VERSION ""

NS_ :

BS_:

BU_: TCM iBooster HCU CIM SCM Right_Hand_Control Left_Hand_Control GPS VCM IC_2 XM GMRS Radio_CANtool Diagnostic_Tool_Digital_Wrench Information_System_Controller_1 STEERING_CONTROLLER VEHICLE_SECURITY RADIO_Hub ABS Battery_Management_Cntrl_2 Battery_Management_Cntrl_1 Auxiliary_Power_Unit_2 Auxiliary_Power_Unit_1 Electric_Propulsion_Cntrl_Unit_4 Electric_Propulsion_Cntrl_Unit_3 Electric_Propulsion_Cntrl_Unit_2 Electric_Propulsion_Cntrl_Unit_1 ECM IC

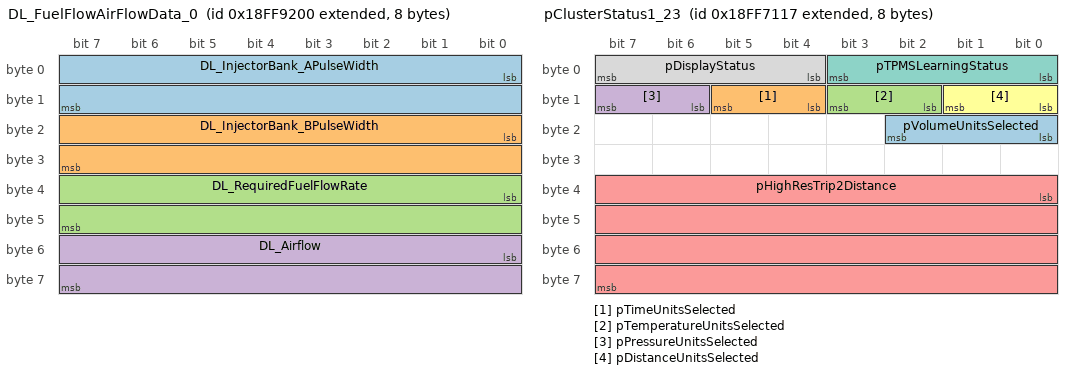
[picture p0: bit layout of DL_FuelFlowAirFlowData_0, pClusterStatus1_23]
BO_ 2566885888 DL_FuelFlowAirFlowData_0: 8 ECM
 SG_ DL_InjectorBank_APulseWidth : 0|16@1+ (0.01,0) [0|655.3] "ms" Vector__XXX
 SG_ DL_InjectorBank_BPulseWidth : 16|16@1+ (0.01,0) [0|655.3] "ms" Vector__XXX
 SG_ DL_RequiredFuelFlowRate : 32|16@1+ (0.003433,0) [0|224.96] "Kg/hr" Vector__XXX
 SG_ DL_Airflow : 48|16@1+ (0.05493,0) [0|3599.56] "Kg/hr" Vector__XXX

BO_ 2566877696 pVT1_0: 8 ECM
 SG_ pLeftHandGripTemp : 0|8@1+ (1,-40) [-40|210] "deg C" Vector__XXX
 SG_ pRightHandGripTemp : 8|8@1+ (1,-40) [-40|210] "deg C" Vector__XXX

BO_ 2566877463 pClusterStatus1_23: 8 IC
 SG_ pVolumeUnitsSelected : 16|3@1+ (1,0) [0|7] "" Vector__XXX
 SG_ pTimeUnitsSelected : 12|2@1+ (1,0) [0|3] "" Vector__XXX
 SG_ pTemperatureUnitsSelected : 10|2@1+ (1,0) [0|3] "" Vector__XXX
 SG_ pPressureUnitsSelected : 14|2@1+ (1,0) [0|3] "" Vector__XXX
 SG_ pHighResTrip2Distance : 32|32@1+ (0.005,0) [0|21055406] "km" Vector__XXX
 SG_ pDistanceUnitsSelected : 8|2@1+ (1,0) [0|3] "" Vector__XXX
 SG_ pTPMSLearningStatus : 0|4@1+ (1,0) [0|15] "" Vector__XXX
 SG_ pDisplayStatus : 4|4@1+ (1,0) [0|15] "" Vector__XXX

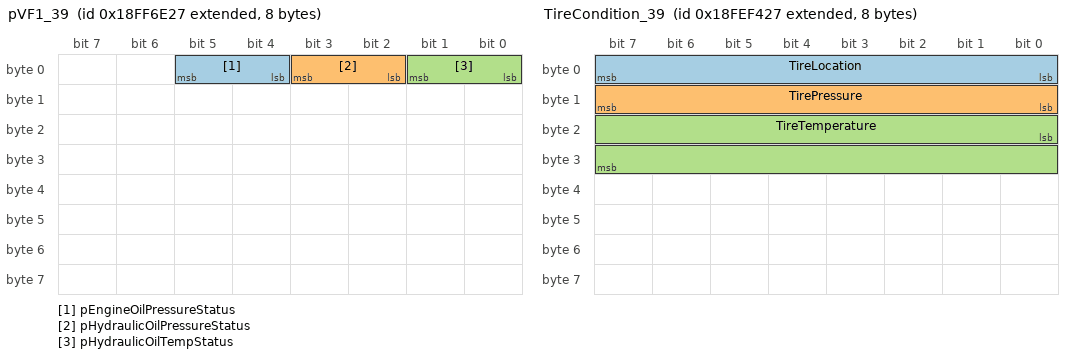
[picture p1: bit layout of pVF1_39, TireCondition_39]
BO_ 2566876711 pVF1_39: 8 VCM
 SG_ pEngineOilPressureStatus : 4|2@1+ (1,0) [0|3] "" Vector__XXX
 SG_ pHydraulicOilPressureStatus : 2|2@1+ (1,0) [0|3] "" Vector__XXX
 SG_ pHydraulicOilTempStatus : 0|2@1+ (1,0) [0|3] "" Vector__XXX

BO_ 2633984551 pDriveSystemStatus_39: 8 VCM
 SG_ pHeatedGripEnable : 48|2@1+ (1,0) [0|3] "" Vector__XXX
 SG_ pSideStandStatus : 36|2@1+ (1,0) [0|3] "" Vector__XXX
 SG_ pTetherSwitchStatus : 46|2@1+ (1,0) [0|3] "" Vector__XXX
 SG_ pLowFuelIndicatorStatus : 10|2@1+ (1,0) [0|3] "" Vector__XXX
 SG_ pOperatorNotInOperatingStation : 38|2@1+ (1,0) [0|3] "" Vector__XXX
 SG_ pParkBrakeIndicatorStatus : 40|3@1+ (1,0) [0|7] "" Vector__XXX
 SG_ pADCRequested : 34|2@1+ (1,0) [0|3] "" Vector__XXX
 SG_ pAWDModeRequested : 32|2@1+ (1,0) [0|3] "" Vector__XXX
 SG_ pRWDModeRequested : 30|2@1+ (1,0) [0|3] "" Vector__XXX
 SG_ pTurfModeRequested : 28|2@1+ (1,0) [0|3] "" Vector__XXX
 SG_ pADCStatus : 0|2@1+ (1,0) [0|3] "" Vector__XXX
 SG_ pTreadleNeutralStatus : 2|2@1+ (1,0) [0|3] "" Vector__XXX
 SG_ pTreadleReverseStatus : 4|2@1+ (1,0) [0|3] "" Vector__XXX
 SG_ pSecurityLightStatus : 6|2@1+ (1,0) [0|3] "" Vector__XXX
 SG_ pHighBeamIndicatorStatus : 8|2@1+ (1,0) [0|3] "" Vector__XXX
 SG_ pHeatedGripsPercentage : 16|8@1+ (0.4,0) [0|100] "%" Vector__XXX
 SG_ pCruiseControlSetStatus : 24|2@1+ (1,0) [0|3] "" Vector__XXX
 SG_ pSeatBeltIndicatorStatus : 12|3@1+ (1,0) [0|7] "" Vector__XXX

BO_ 2432656679 pOperatorSwitchStatus_39: 8 VCM
 SG_ pOperatorButton29 : 58|2@1+ (1,0) [0|3] "" Vector__XXX
 SG_ pOperatorButton1 : 0|2@1+ (1,0) [0|3] "" Vector__XXX
 SG_ pOperatorButton2 : 2|2@1+ (1,0) [0|3] "" Vector__XXX
 SG_ pOperatorButton3 : 4|2@1+ (1,0) [0|3] "" Vector__XXX
 SG_ pOperatorButton4 : 6|2@1+ (1,0) [0|3] "" Vector__XXX
 SG_ pOperatorButton5 : 8|2@1+ (1,0) [0|3] "" Vector__XXX
 SG_ pOperatorButton6 : 10|2@1+ (1,0) [0|3] "" Vector__XXX
 SG_ pOperatorButton7 : 12|2@1+ (1,0) [0|3] "" Vector__XXX
 SG_ pOperatorButton8 : 14|2@1+ (1,0) [0|3] "" Vector__XXX
 SG_ pOperatorButton9 : 16|2@1+ (1,0) [0|3] "" Vector__XXX
 SG_ pOperatorButton10 : 18|2@1+ (1,0) [0|3] "" Vector__XXX
 SG_ pOperatorButton11 : 20|2@1+ (1,0) [0|3] "" Vector__XXX
 SG_ pOperatorButton12 : 22|2@1+ (1,0) [0|3] "" Vector__XXX
 SG_ pOperatorButton13 : 24|2@1+ (1,0) [0|3] "" Vector__XXX
 SG_ pOperatorButton14 : 26|2@1+ (1,0) [0|3] "" Vector__XXX
 SG_ pOperatorButton15 : 28|2@1+ (1,0) [0|3] "" Vector__XXX
 SG_ pOperatorButton16 : 30|2@1+ (1,0) [0|3] "" Vector__XXX
 SG_ pOperatorButton17 : 32|2@1+ (1,0) [0|3] "" Vector__XXX
 SG_ pOperatorButton18 : 34|2@1+ (1,0) [0|3] "" Vector__XXX
 SG_ pOperatorButton19 : 36|2@1+ (1,0) [0|3] "" Vector__XXX
 SG_ pOperatorButton20 : 38|2@1+ (1,0) [0|3] "" Vector__XXX
 SG_ pOperatorButton21 : 40|2@1+ (1,0) [0|3] "" Vector__XXX
 SG_ pOperatorButton22 : 42|2@1+ (1,0) [0|3] "" Vector__XXX
 SG_ pOperatorButton23 : 44|2@1+ (1,0) [0|3] "" Vector__XXX
 SG_ pOperatorButton24 : 46|2@1+ (1,0) [0|3] "" Vector__XXX
 SG_ pOperatorButton25 : 48|2@1+ (1,0) [0|3] "" Vector__XXX
 SG_ pOperatorButton26 : 50|2@1+ (1,0) [0|3] "" Vector__XXX
 SG_ pOperatorButton27 : 52|2@1+ (1,0) [0|3] "" Vector__XXX
 SG_ pOperatorButton28 : 54|2@1+ (1,0) [0|3] "" Vector__XXX
 SG_ pSideStandStatus : 56|2@1+ (1,0) [0|3] "" Vector__XXX

BO_ 2566845479 TireCondition_39: 8 VCM
 SG_ TireLocation : 0|8@1+ (1,0) [0|255] "Bit" Vector__XXX
 SG_ TirePressure : 8|8@1+ (4,0) [0|1000] "kPa" Vector__XXX
 SG_ TireTemperature : 16|16@1+ (0.03125,-273) [-273|1734.96875] "DegC" Vector__XXX

BO_ 2566844711 CruiseControlVehSpeed_39: 8 VCM
 SG_ pCruiseCntrlCounter : 50|4@1+ (1,0) [0|15] "" Vector__XXX
 SG_ TwoSpeedAxleSwitch : 0|2@1+ (1,0) [0|3] "" Vector__XXX
 SG_ ParkingBrakeSwitch : 2|2@1+ (1,0) [0|3] "" Vector__XXX
 SG_ Wheel_BasedVehicleSpeed : 8|16@1+ (0.00390625,0) [0|251] "km/h" Vector__XXX
 SG_ CruiseCtrlActive : 24|2@1+ (1,0) [0|3] "" Vector__XXX
 SG_ CruiseCtrlEnableSwitch : 26|2@1+ (1,0) [0|3] "" Vector__XXX
 SG_ BrakeSwitch : 28|2@1+ (1,0) [0|3] "" Vector__XXX
 SG_ ClutchSwitch : 30|2@1+ (1,0) [0|3] "" Vector__XXX
 SG_ CruiseCtrlSetSwitch : 32|2@1+ (1,0) [0|3] "" Vector__XXX
 SG_ CruiseCtrlCoastSwitch : 34|2@1+ (1,0) [0|3] "" Vector__XXX
 SG_ CruiseCtrlResumeSwitch : 36|2@1+ (1,0) [0|3] "" Vector__XXX
 SG_ CruiseCtrlAccelerateSwitch : 38|2@1+ (1,0) [0|3] "" Vector__XXX
 SG_ CruiseCtrlSetSpeed : 40|8@1+ (1,0) [0|250] "km/h" Vector__XXX
 SG_ pOdometerDriveBit : 6|2@1+ (1,0) [0|3] "" Vector__XXX
 SG_ CruiseCtrlPauseSw : 4|2@1+ (1,0) [0|3] "" Vector__XXX
 SG_ pCCChecksum : 56|8@1+ (1,0) [0|255] "" Vector__XXX
 SG_ pCruiseEnableStatus : 48|4@1+ (1,0) [0|15] "" Vector__XXX

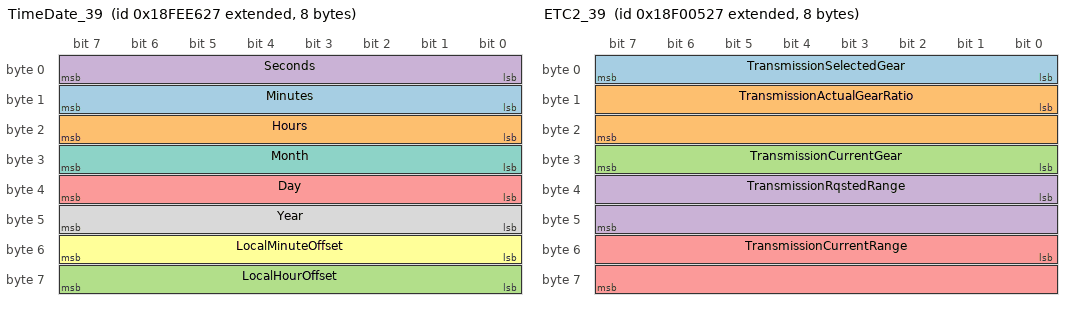
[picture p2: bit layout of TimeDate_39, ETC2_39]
BO_ 2566841895 TimeDate_39: 8 VCM
 SG_ Minutes : 8|8@1+ (1,0) [0|250] "Minutes" Vector__XXX
 SG_ Hours : 16|8@1+ (1,0) [0|250] "Hours" Vector__XXX
 SG_ LocalHourOffset : 56|8@1+ (1,-125) [-125|125] "Hours" Vector__XXX
 SG_ Seconds : 0|8@1+ (0.25,0) [0|62.5] "Seconds" Vector__XXX
 SG_ Day : 32|8@1+ (0.25,0) [0|62.5] "Days" Vector__XXX
 SG_ LocalMinuteOffset : 48|8@1+ (1,-125) [-125|125] "Mins" Vector__XXX
 SG_ Month : 24|8@1+ (1,0) [0|250] "Months" Vector__XXX
 SG_ Year : 40|8@1+ (1,1985) [0|2235] "Years" Vector__XXX

BO_ 2565866791 ETC2_39: 8 VCM
 SG_ TransmissionSelectedGear : 0|8@1+ (1,-125) [-125|125] "" Vector__XXX
 SG_ TransmissionActualGearRatio : 8|16@1+ (0.001,0) [0|64.255] "" Vector__XXX
 SG_ TransmissionCurrentGear : 24|8@1+ (1,-125) [-125|125] "" Vector__XXX
 SG_ TransmissionRqstedRange : 32|16@1+ (1,0) [0|65535] "" Vector__XXX
 SG_ TransmissionCurrentRange : 48|16@1+ (1,0) [0|65535] "" Vector__XXX

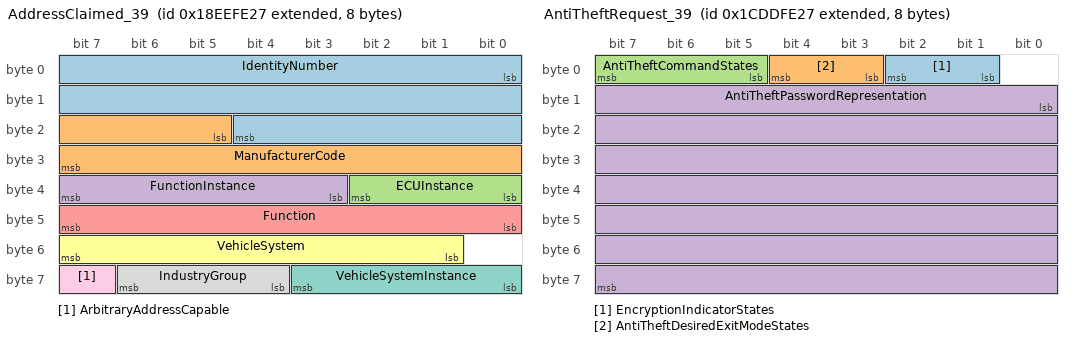
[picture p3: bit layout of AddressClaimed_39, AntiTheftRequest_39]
BO_ 2565799463 AddressClaimed_39: 8 VCM
 SG_ IdentityNumber : 0|21@1+ (1,0) [0|2097151] "" Vector__XXX
 SG_ ManufacturerCode : 21|11@1+ (1,0) [0|2047] "" Vector__XXX
 SG_ ECUInstance : 32|3@1+ (1,0) [0|7] "" Vector__XXX
 SG_ FunctionInstance : 35|5@1+ (1,0) [0|31] "" Vector__XXX
 SG_ Function : 40|8@1+ (1,0) [0|255] "" Vector__XXX
 SG_ VehicleSystem : 49|7@1+ (1,0) [0|127] "" Vector__XXX
 SG_ VehicleSystemInstance : 56|4@1+ (1,0) [0|15] "" Vector__XXX
 SG_ IndustryGroup : 60|3@1+ (1,0) [0|7] "" Vector__XXX
 SG_ ArbitraryAddressCapable : 63|1@1+ (1,0) [0|0] "" Vector__XXX

BO_ 2631794215 AntiTheftRequest_39: 8 VCM
 SG_ EncryptionIndicatorStates : 1|2@1+ (1,0) [0|3] "" Vector__XXX
 SG_ AntiTheftDesiredExitModeStates : 3|2@1+ (1,0) [0|3] "" Vector__XXX
 SG_ AntiTheftCommandStates : 5|3@1+ (1,0) [0|7] "" Vector__XXX
 SG_ AntiTheftPasswordRepresentation : 8|56@1+ (1,0) [0|0] "" Vector__XXX

BO_ 2550791719 SRASI_39: 8 VCM
 SG_ StaticRollAngle : 0|8@1+ (1,-125) [-125|130] "Degrees" Vector__XXX
 SG_ StaticRollAngleStatus : 8|3@1+ (1,0) [0|7] "" Vector__XXX

BO_ 2566842495 VehicleDirectionSpeed_127: 8 RADIO_Hub
 SG_ CompassBearing : 0|16@1+ (0.0078125,0) [0|501.99] "Degree" Vector__XXX

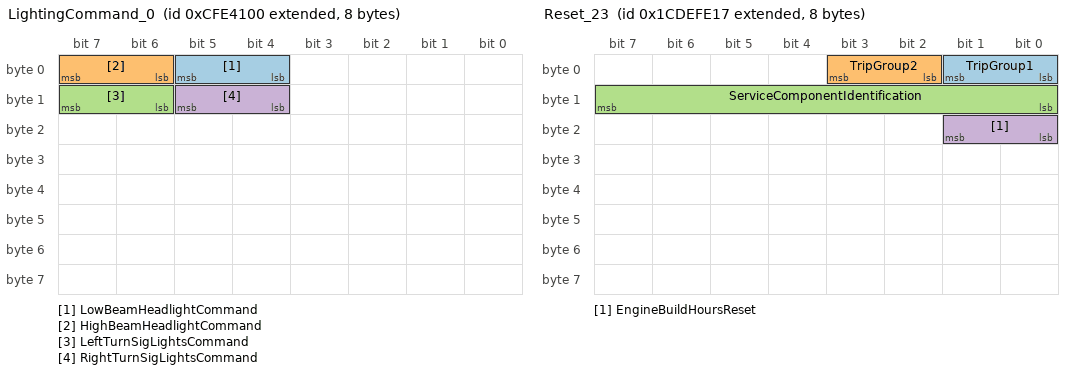
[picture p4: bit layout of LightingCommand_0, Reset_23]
BO_ 2365473024 LightingCommand_0: 8 ECM
 SG_ LowBeamHeadlightCommand : 4|2@1+ (1,0) [0|3] "" Vector__XXX
 SG_ HighBeamHeadlightCommand : 6|2@1+ (1,0) [0|3] "" Vector__XXX
 SG_ LeftTurnSigLightsCommand : 14|2@1+ (1,0) [0|3] "" Vector__XXX
 SG_ RightTurnSigLightsCommand : 12|2@1+ (1,0) [0|3] "" Vector__XXX

BO_ 2631859735 Reset_23: 8 IC
 SG_ TripGroup1 : 0|2@1+ (1,0) [0|3] "" Vector__XXX
 SG_ TripGroup2 : 2|2@1+ (1,0) [0|3] "" Vector__XXX
 SG_ ServiceComponentIdentification : 8|8@1+ (1,0) [0|250] "" Vector__XXX
 SG_ EngineBuildHoursReset : 16|2@1+ (1,0) [0|3] "" Vector__XXX

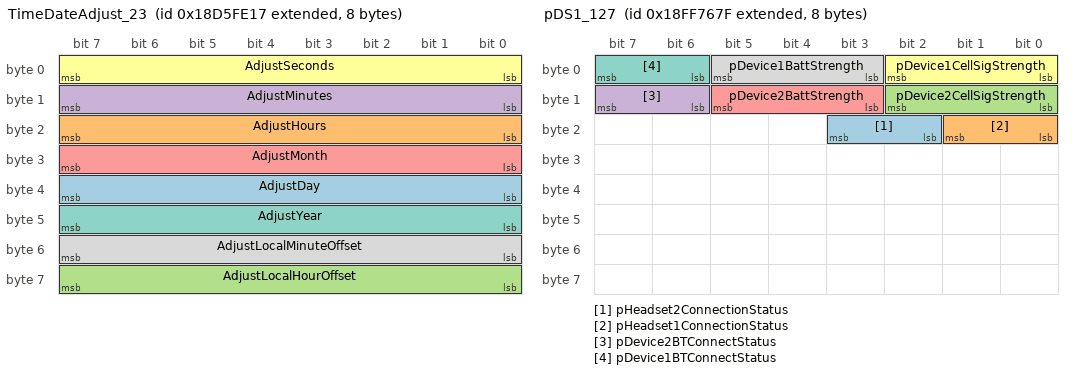
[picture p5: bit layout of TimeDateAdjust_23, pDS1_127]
BO_ 2564161047 TimeDateAdjust_23: 8 IC
 SG_ AdjustDay : 32|8@1+ (0.25,0) [0|62.5] "Days" Vector__XXX
 SG_ AdjustHours : 16|8@1+ (1,0) [0|250] "Hours" Vector__XXX
 SG_ AdjustLocalHourOffset : 56|8@1+ (1,-125) [-125|130] "Hours" Vector__XXX
 SG_ AdjustMinutes : 8|8@1+ (1,0) [0|250] "Minutes" Vector__XXX
 SG_ AdjustMonth : 24|8@1+ (1,0) [0|250] "Months" Vector__XXX
 SG_ AdjustSeconds : 0|8@1+ (0.25,0) [0|62.5] "Seconds" Vector__XXX
 SG_ AdjustYear : 40|8@1+ (1,1985) [1985|2235] "Years" Vector__XXX
 SG_ AdjustLocalMinuteOffset : 48|8@1+ (1,-125) [-125|130] "Minutes" Vector__XXX

BO_ 2550201867 TorqueSpeedControl1_11: 4 ABS
 SG_ EngOverrideCtlMode : 0|2@1+ (1,0) [0|3] "" Vector__XXX
 SG_ EngReqSpeedControlCond : 2|2@1+ (1,0) [0|3] "" Vector__XXX
 SG_ OverrideCtlModePriority : 4|2@1+ (1,0) [0|3] "" Vector__XXX
 SG_ EngReqSpeedLimit : 8|16@1+ (1,0) [0|65535] "" Vector__XXX
 SG_ EngReqTorqueLimit : 24|8@1+ (1,-125) [-125|130] "%" Vector__XXX
 SG_ TSC1_TransmissionRate : 32|3@1+ (1,0) [0|7] "" Vector__XXX
 SG_ EngineRequestedTorque_HiRes : 40|4@1+ (0.125,0) [0|0.875] "%" Vector__XXX
 SG_ MessageCounter : 56|4@1- (1,0) [-8|7] "Count" Vector__XXX
 SG_ MessageChecksum : 60|4@1+ (1,0) [0|15] "" Vector__XXX

BO_ 2566878847 pDS1_127: 8 RADIO_Hub
 SG_ pHeadset2ConnectionStatus : 18|2@1+ (1,0) [0|3] "" Vector__XXX
 SG_ pHeadset1ConnectionStatus : 16|2@1+ (1,0) [0|3] "" Vector__XXX
 SG_ pDevice2CellSigStrength : 8|3@1+ (1,0) [0|7] "" Vector__XXX
 SG_ pDevice2BTConnectStatus : 14|2@1+ (1,0) [0|3] "" Vector__XXX
 SG_ pDevice2BattStrength : 11|3@1+ (1,0) [0|7] "" Vector__XXX
 SG_ pDevice1CellSigStrength : 0|3@1+ (1,0) [0|7] "" Vector__XXX
 SG_ pDevice1BTConnectStatus : 6|2@1+ (1,0) [0|3] "" Vector__XXX
 SG_ pDevice1BattStrength : 3|3@1+ (1,0) [0|7] "" Vector__XXX

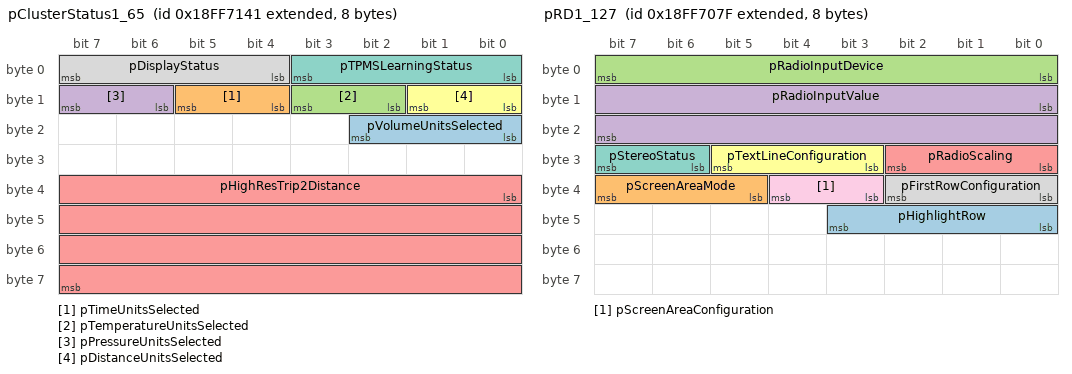
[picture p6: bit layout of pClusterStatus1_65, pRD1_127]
BO_ 2566877505 pClusterStatus1_65: 8 Information_System_Controller_1
 SG_ pVolumeUnitsSelected : 16|3@1+ (1,0) [0|7] "" Vector__XXX
 SG_ pTimeUnitsSelected : 12|2@1+ (1,0) [0|3] "" Vector__XXX
 SG_ pTemperatureUnitsSelected : 10|2@1+ (1,0) [0|3] "" Vector__XXX
 SG_ pPressureUnitsSelected : 14|2@1+ (1,0) [0|3] "" Vector__XXX
 SG_ pHighResTrip2Distance : 32|32@1+ (0.005,0) [0|21055406] "km" Vector__XXX
 SG_ pDistanceUnitsSelected : 8|2@1+ (1,0) [0|3] "" Vector__XXX
 SG_ pTPMSLearningStatus : 0|4@1+ (1,0) [0|15] "" Vector__XXX
 SG_ pDisplayStatus : 4|4@1+ (1,0) [0|15] "" Vector__XXX

BO_ 2566877311 pRD1_127: 8 RADIO_Hub
 SG_ pHighlightRow : 40|4@1+ (1,0) [0|15] "" Vector__XXX
 SG_ pScreenAreaMode : 37|3@1+ (1,0) [0|7] "" Vector__XXX
 SG_ pRadioInputDevice : 0|8@1+ (1,0) [0|65535] "" Vector__XXX
 SG_ pRadioInputValue : 8|16@1+ (1,0) [0|65535] "" Vector__XXX
 SG_ pRadioScaling : 24|3@1+ (1,0) [0|7] "" Vector__XXX
 SG_ pTextLineConfiguration : 27|3@1+ (1,0) [0|7] "" Vector__XXX
 SG_ pStereoStatus : 30|2@1+ (1,0) [0|3] "" Vector__XXX
 SG_ pFirstRowConfiguration : 32|3@1+ (1,0) [0|7] "" Vector__XXX
 SG_ pScreenAreaConfiguration : 35|2@1+ (1,0) [0|3] "" Vector__XXX

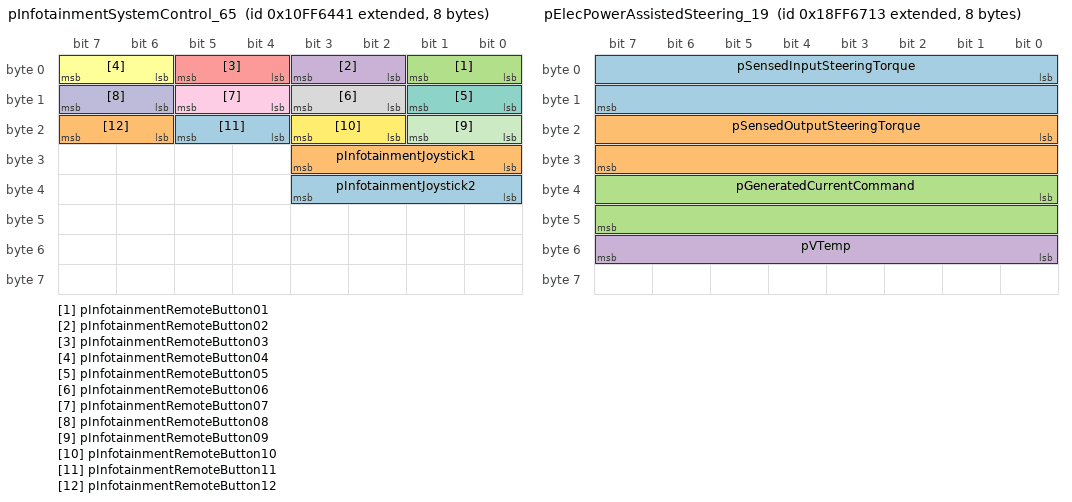
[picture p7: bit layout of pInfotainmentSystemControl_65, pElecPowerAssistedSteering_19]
BO_ 2432656449 pInfotainmentSystemControl_65: 8 Information_System_Controller_1
 SG_ pInfotainmentJoystick2 : 32|4@1+ (1,0) [0|15] "" Vector__XXX
 SG_ pInfotainmentJoystick1 : 24|4@1+ (1,0) [0|15] "" Vector__XXX
 SG_ pInfotainmentRemoteButton01 : 0|2@1+ (1,0) [0|3] "" Vector__XXX
 SG_ pInfotainmentRemoteButton02 : 2|2@1+ (1,0) [0|3] "" Vector__XXX
 SG_ pInfotainmentRemoteButton03 : 4|2@1+ (1,0) [0|3] "" Vector__XXX
 SG_ pInfotainmentRemoteButton04 : 6|2@1+ (1,0) [0|3] "" Vector__XXX
 SG_ pInfotainmentRemoteButton05 : 8|2@1+ (1,0) [0|3] "" Vector__XXX
 SG_ pInfotainmentRemoteButton06 : 10|2@1+ (1,0) [0|3] "" Vector__XXX
 SG_ pInfotainmentRemoteButton07 : 12|2@1+ (1,0) [0|3] "" Vector__XXX
 SG_ pInfotainmentRemoteButton08 : 14|2@1+ (1,0) [0|3] "" Vector__XXX
 SG_ pInfotainmentRemoteButton09 : 16|2@1+ (1,0) [0|3] "" Vector__XXX
 SG_ pInfotainmentRemoteButton10 : 18|2@1+ (1,0) [0|3] "" Vector__XXX
 SG_ pInfotainmentRemoteButton11 : 20|2@1+ (1,0) [0|3] "" Vector__XXX
 SG_ pInfotainmentRemoteButton12 : 22|2@1+ (1,0) [0|3] "" Vector__XXX

BO_ 2566874899 pElecPowerAssistedSteering_19: 8 STEERING_CONTROLLER
 SG_ pSensedInputSteeringTorque : 0|16@1- (0.1,-3200) [-3200|3353.5] "Nm" Vector__XXX
 SG_ pSensedOutputSteeringTorque : 16|16@1- (0.1,-3200) [-3200|3353.5] "Nm" Vector__XXX
 SG_ pGeneratedCurrentCommand : 32|16@1+ (0.00381467265625,-125) [-125|124.994572527344] "A" Vector__XXX
 SG_ pVTemp : 48|8@1- (1,-40) [-40|210] "C" Vector__XXX

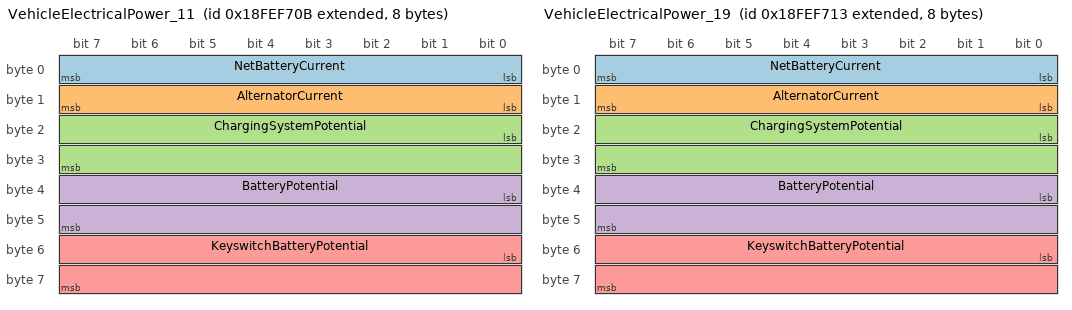
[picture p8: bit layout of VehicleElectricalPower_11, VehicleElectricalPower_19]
BO_ 2566846219 VehicleElectricalPower_11: 8 ABS
 SG_ NetBatteryCurrent : 0|8@1+ (1,-125) [-125|125] "A" Vector__XXX
 SG_ AlternatorCurrent : 8|8@1+ (1,0) [0|250] "A" Vector__XXX
 SG_ ChargingSystemPotential : 16|16@1+ (0.05,0) [0|3212.75] "V" Vector__XXX
 SG_ BatteryPotential : 32|16@1+ (0.05,0) [0|3212.75] "V" Vector__XXX
 SG_ KeyswitchBatteryPotential : 48|16@1+ (0.05,0) [0|3212.75] "V" Vector__XXX

BO_ 2566846227 VehicleElectricalPower_19: 8 STEERING_CONTROLLER
 SG_ NetBatteryCurrent : 0|8@1+ (1,-125) [-125|125] "A" Vector__XXX
 SG_ AlternatorCurrent : 8|8@1+ (1,0) [0|250] "A" Vector__XXX
 SG_ ChargingSystemPotential : 16|16@1+ (0.05,0) [0|3212.75] "V" Vector__XXX
 SG_ BatteryPotential : 32|16@1+ (0.05,0) [0|3212.75] "V" Vector__XXX
 SG_ KeyswitchBatteryPotential : 48|16@1+ (0.05,0) [0|3212.75] "V" Vector__XXX

BO_ 2566844683 CruiseControlVehSpeed_11: 8 ABS
 SG_ TwoSpeedAxleSwitch : 0|2@1+ (1,0) [0|3] "" Vector__XXX
 SG_ ParkingBrakeSwitch : 2|2@1+ (1,0) [0|3] "" Vector__XXX
 SG_ Wheel_BasedVehicleSpeed : 8|16@1+ (0.00390625,0) [0|251] "km/h" Vector__XXX
 SG_ CruiseCtrlActive : 24|2@1+ (1,0) [0|3] "" Vector__XXX
 SG_ CruiseCtrlEnableSwitch : 26|2@1+ (1,0) [0|3] "" Vector__XXX
 SG_ BrakeSwitch : 28|2@1+ (1,0) [0|3] "" Vector__XXX
 SG_ ClutchSwitch : 30|2@1+ (1,0) [0|3] "" Vector__XXX
 SG_ CruiseCtrlSetSwitch : 32|2@1+ (1,0) [0|3] "" Vector__XXX
 SG_ CruiseCtrlCoastSwitch : 34|2@1+ (1,0) [0|3] "" Vector__XXX
 SG_ CruiseCtrlResumeSwitch : 36|2@1+ (1,0) [0|3] "" Vector__XXX
 SG_ CruiseCtrlAccelerateSwitch : 38|2@1+ (1,0) [0|3] "" Vector__XXX
 SG_ CruiseCtrlSetSpeed : 40|8@1+ (1,0) [0|250] "km/h" Vector__XXX
 SG_ pOdometerDriveBit : 6|2@1+ (1,0) [0|3] "" Vector__XXX
 SG_ CruiseCtrlPauseSw : 4|2@1+ (1,0) [0|3] "" Vector__XXX
 SG_ pCCChecksum : 56|8@1+ (1,0) [0|255] "" Vector__XXX
 SG_ pCruiseEnableStatus : 48|4@1+ (1,0) [0|15] "" Vector__XXX
 SG_ pCCMessageCounter : 52|4@1+ (1,0) [0|15] "" Vector__XXX

BO_ 2566844839 CruiseControlVehSpeed_167: 8 IC_2
 SG_ TwoSpeedAxleSwitch : 0|2@1+ (1,0) [0|3] "" Vector__XXX
 SG_ ParkingBrakeSwitch : 2|2@1+ (1,0) [0|3] "" Vector__XXX
 SG_ Wheel_BasedVehicleSpeed : 8|16@1+ (0.00390625,0) [0|251] "km/h" Vector__XXX
 SG_ CruiseCtrlActive : 24|2@1+ (1,0) [0|3] "" Vector__XXX
 SG_ CruiseCtrlEnableSwitch : 26|2@1+ (1,0) [0|3] "" Vector__XXX
 SG_ BrakeSwitch : 28|2@1+ (1,0) [0|3] "" Vector__XXX
 SG_ ClutchSwitch : 30|2@1+ (1,0) [0|3] "" Vector__XXX
 SG_ CruiseCtrlSetSwitch : 32|2@1+ (1,0) [0|3] "" Vector__XXX
 SG_ CruiseCtrlCoastSwitch : 34|2@1+ (1,0) [0|3] "" Vector__XXX
 SG_ CruiseCtrlResumeSwitch : 36|2@1+ (1,0) [0|3] "" Vector__XXX
 SG_ CruiseCtrlAccelerateSwitch : 38|2@1+ (1,0) [0|3] "" Vector__XXX
 SG_ CruiseCtrlSetSpeed : 40|8@1+ (1,0) [0|250] "km/h" Vector__XXX
 SG_ pOdometerDriveBit : 6|2@1+ (1,0) [0|3] "" Vector__XXX
 SG_ CruiseCtrlPauseSw : 4|2@1+ (1,0) [0|3] "" Vector__XXX
 SG_ pCCChecksum : 56|8@1+ (1,0) [0|255] "" Vector__XXX
 SG_ pCruiseEnableStatus : 48|4@1+ (1,0) [0|15] "" Vector__XXX
 SG_ pCruiseCntrlCounter : 52|4@1+ (1,0) [0|15] "" Vector__XXX

BO_ 2566834855 DM1_167: 22 IC_2
 SG_ DTC5 : 144|32@1+ (1,0) [0|4294967295] "" Vector__XXX
 SG_ DTC4 : 112|32@1+ (1,0) [0|4294967295] "" Vector__XXX
 SG_ DTC3 : 80|32@1+ (1,0) [0|4294967295] "" Vector__XXX
 SG_ DTC2 : 48|32@1+ (1,0) [0|4294967295] "" Vector__XXX
 SG_ DTC1 : 16|32@1+ (1,0) [0|4294967295] "" Vector__XXX
 SG_ DM_FlashRedStopLamp : 12|2@1+ (1,0) [0|3] "" Vector__XXX
 SG_ DM_FlashProtectLamp : 8|2@1+ (1,0) [0|3] "" Vector__XXX
 SG_ DM_FlashMalfuncIndicatorLamp : 14|2@1+ (1,0) [0|3] "" Vector__XXX
 SG_ DM_FlashAmberWarningLamp : 10|2@1+ (1,0) [0|3] "" Vector__XXX
 SG_ DM_ProtectLampStatus : 0|2@1+ (1,0) [0|3] "" Vector__XXX
 SG_ DM_RedStopLampState : 4|2@1+ (1,0) [0|3] "" Vector__XXX
 SG_ DM_AmberWrningLmpStatus : 2|2@1+ (1,0) [0|3] "" Vector__XXX
 SG_ DM_MalfuncnIndicatorLampStatus : 6|2@1+ (1,0) [0|3] "" Vector__XXX

BO_ 2566834815 DM1_127: 22 RADIO_Hub
 SG_ DTC5 : 144|32@1+ (1,0) [0|4294967295] "" Vector__XXX
 SG_ DTC4 : 112|32@1+ (1,0) [0|4294967295] "" Vector__XXX
 SG_ DTC3 : 80|32@1+ (1,0) [0|4294967295] "" Vector__XXX
 SG_ DTC2 : 48|32@1+ (1,0) [0|4294967295] "" Vector__XXX
 SG_ DTC1 : 16|32@1+ (1,0) [0|4294967295] "" Vector__XXX
 SG_ DM_FlashRedStopLamp : 12|2@1+ (1,0) [0|3] "" Vector__XXX
 SG_ DM_FlashProtectLamp : 8|2@1+ (1,0) [0|3] "" Vector__XXX
 SG_ DM_FlashMalfuncIndicatorLamp : 14|2@1+ (1,0) [0|3] "" Vector__XXX
 SG_ DM_FlashAmberWarningLamp : 10|2@1+ (1,0) [0|3] "" Vector__XXX
 SG_ DM_ProtectLampStatus : 0|2@1+ (1,0) [0|3] "" Vector__XXX
 SG_ DM_RedStopLampState : 4|2@1+ (1,0) [0|3] "" Vector__XXX
 SG_ DM_AmberWrningLmpStatus : 2|2@1+ (1,0) [0|3] "" Vector__XXX
 SG_ DM_MalfuncnIndicatorLampStatus : 6|2@1+ (1,0) [0|3] "" Vector__XXX

BO_ 2566834814 DM1_126: 22 XM
 SG_ DTC5 : 144|32@1+ (1,0) [0|4294967295] "" Vector__XXX
 SG_ DTC4 : 112|32@1+ (1,0) [0|4294967295] "" Vector__XXX
 SG_ DTC3 : 80|32@1+ (1,0) [0|4294967295] "" Vector__XXX
 SG_ DTC2 : 48|32@1+ (1,0) [0|4294967295] "" Vector__XXX
 SG_ DTC1 : 16|32@1+ (1,0) [0|4294967295] "" Vector__XXX
 SG_ DM_FlashRedStopLamp : 12|2@1+ (1,0) [0|3] "" Vector__XXX
 SG_ DM_FlashProtectLamp : 8|2@1+ (1,0) [0|3] "" Vector__XXX
 SG_ DM_FlashMalfuncIndicatorLamp : 14|2@1+ (1,0) [0|3] "" Vector__XXX
 SG_ DM_FlashAmberWarningLamp : 10|2@1+ (1,0) [0|3] "" Vector__XXX
 SG_ DM_ProtectLampStatus : 0|2@1+ (1,0) [0|3] "" Vector__XXX
 SG_ DM_RedStopLampState : 4|2@1+ (1,0) [0|3] "" Vector__XXX
 SG_ DM_AmberWrningLmpStatus : 2|2@1+ (1,0) [0|3] "" Vector__XXX
 SG_ DM_MalfuncnIndicatorLampStatus : 6|2@1+ (1,0) [0|3] "" Vector__XXX

BO_ 2566834812 DM1_124: 22 GMRS
 SG_ DTC5 : 144|32@1+ (1,0) [0|4294967295] "" Vector__XXX
 SG_ DTC4 : 112|32@1+ (1,0) [0|4294967295] "" Vector__XXX
 SG_ DTC3 : 80|32@1+ (1,0) [0|4294967295] "" Vector__XXX
 SG_ DTC2 : 48|32@1+ (1,0) [0|4294967295] "" Vector__XXX
 SG_ DTC1 : 16|32@1+ (1,0) [0|4294967295] "" Vector__XXX
 SG_ DM_FlashRedStopLamp : 12|2@1+ (1,0) [0|3] "" Vector__XXX
 SG_ DM_FlashProtectLamp : 8|2@1+ (1,0) [0|3] "" Vector__XXX
 SG_ DM_FlashMalfuncIndicatorLamp : 14|2@1+ (1,0) [0|3] "" Vector__XXX
 SG_ DM_FlashAmberWarningLamp : 10|2@1+ (1,0) [0|3] "" Vector__XXX
 SG_ DM_ProtectLampStatus : 0|2@1+ (1,0) [0|3] "" Vector__XXX
 SG_ DM_RedStopLampState : 4|2@1+ (1,0) [0|3] "" Vector__XXX
 SG_ DM_AmberWrningLmpStatus : 2|2@1+ (1,0) [0|3] "" Vector__XXX
 SG_ DM_MalfuncnIndicatorLampStatus : 6|2@1+ (1,0) [0|3] "" Vector__XXX

BO_ 2566834808 DM1_120: 22 Radio_CANtool
 SG_ DTC5 : 144|32@1+ (1,0) [0|4294967295] "" Vector__XXX
 SG_ DTC4 : 112|32@1+ (1,0) [0|4294967295] "" Vector__XXX
 SG_ DTC3 : 80|32@1+ (1,0) [0|4294967295] "" Vector__XXX
 SG_ DTC2 : 48|32@1+ (1,0) [0|4294967295] "" Vector__XXX
 SG_ DTC1 : 16|32@1+ (1,0) [0|4294967295] "" Vector__XXX
 SG_ DM_FlashRedStopLamp : 12|2@1+ (1,0) [0|3] "" Vector__XXX
 SG_ DM_FlashProtectLamp : 8|2@1+ (1,0) [0|3] "" Vector__XXX
 SG_ DM_FlashMalfuncIndicatorLamp : 14|2@1+ (1,0) [0|3] "" Vector__XXX
 SG_ DM_FlashAmberWarningLamp : 10|2@1+ (1,0) [0|3] "" Vector__XXX
 SG_ DM_ProtectLampStatus : 0|2@1+ (1,0) [0|3] "" Vector__XXX
 SG_ DM_RedStopLampState : 4|2@1+ (1,0) [0|3] "" Vector__XXX
 SG_ DM_AmberWrningLmpStatus : 2|2@1+ (1,0) [0|3] "" Vector__XXX
 SG_ DM_MalfuncnIndicatorLampStatus : 6|2@1+ (1,0) [0|3] "" Vector__XXX

BO_ 2566834937 DM1_249: 22 Diagnostic_Tool_Digital_Wrench
 SG_ DTC5 : 144|32@1+ (1,0) [0|4294967295] "" Vector__XXX
 SG_ DTC4 : 112|32@1+ (1,0) [0|4294967295] "" Vector__XXX
 SG_ DTC3 : 80|32@1+ (1,0) [0|4294967295] "" Vector__XXX
 SG_ DTC2 : 48|32@1+ (1,0) [0|4294967295] "" Vector__XXX
 SG_ DTC1 : 16|32@1+ (1,0) [0|4294967295] "" Vector__XXX
 SG_ DM_FlashRedStopLamp : 12|2@1+ (1,0) [0|3] "" Vector__XXX
 SG_ DM_FlashProtectLamp : 8|2@1+ (1,0) [0|3] "" Vector__XXX
 SG_ DM_FlashMalfuncIndicatorLamp : 14|2@1+ (1,0) [0|3] "" Vector__XXX
 SG_ DM_FlashAmberWarningLamp : 10|2@1+ (1,0) [0|3] "" Vector__XXX
 SG_ DM_ProtectLampStatus : 0|2@1+ (1,0) [0|3] "" Vector__XXX
 SG_ DM_RedStopLampState : 4|2@1+ (1,0) [0|3] "" Vector__XXX
 SG_ DM_AmberWrningLmpStatus : 2|2@1+ (1,0) [0|3] "" Vector__XXX
 SG_ DM_MalfuncnIndicatorLampStatus : 6|2@1+ (1,0) [0|3] "" Vector__XXX

BO_ 2566834753 DM1_65: 22 Information_System_Controller_1
 SG_ DTC5 : 144|32@1+ (1,0) [0|4294967295] "" Vector__XXX
 SG_ DTC4 : 112|32@1+ (1,0) [0|4294967295] "" Vector__XXX
 SG_ DTC3 : 80|32@1+ (1,0) [0|4294967295] "" Vector__XXX
 SG_ DTC2 : 48|32@1+ (1,0) [0|4294967295] "" Vector__XXX
 SG_ DTC1 : 16|32@1+ (1,0) [0|4294967295] "" Vector__XXX
 SG_ DM_FlashRedStopLamp : 12|2@1+ (1,0) [0|3] "" Vector__XXX
 SG_ DM_FlashProtectLamp : 8|2@1+ (1,0) [0|3] "" Vector__XXX
 SG_ DM_FlashMalfuncIndicatorLamp : 14|2@1+ (1,0) [0|3] "" Vector__XXX
 SG_ DM_FlashAmberWarningLamp : 10|2@1+ (1,0) [0|3] "" Vector__XXX
 SG_ DM_ProtectLampStatus : 0|2@1+ (1,0) [0|3] "" Vector__XXX
 SG_ DM_RedStopLampState : 4|2@1+ (1,0) [0|3] "" Vector__XXX
 SG_ DM_AmberWrningLmpStatus : 2|2@1+ (1,0) [0|3] "" Vector__XXX
 SG_ DM_MalfuncnIndicatorLampStatus : 6|2@1+ (1,0) [0|3] "" Vector__XXX

BO_ 2566834717 DM1_29: 22 VEHICLE_SECURITY
 SG_ DTC5 : 144|32@1+ (1,0) [0|4294967295] "" Vector__XXX
 SG_ DTC4 : 112|32@1+ (1,0) [0|4294967295] "" Vector__XXX
 SG_ DTC3 : 80|32@1+ (1,0) [0|4294967295] "" Vector__XXX
 SG_ DTC2 : 48|32@1+ (1,0) [0|4294967295] "" Vector__XXX
 SG_ DTC1 : 16|32@1+ (1,0) [0|4294967295] "" Vector__XXX
 SG_ DM_FlashRedStopLamp : 12|2@1+ (1,0) [0|3] "" Vector__XXX
 SG_ DM_FlashProtectLamp : 8|2@1+ (1,0) [0|3] "" Vector__XXX
 SG_ DM_FlashMalfuncIndicatorLamp : 14|2@1+ (1,0) [0|3] "" Vector__XXX
 SG_ DM_FlashAmberWarningLamp : 10|2@1+ (1,0) [0|3] "" Vector__XXX
 SG_ DM_ProtectLampStatus : 0|2@1+ (1,0) [0|3] "" Vector__XXX
 SG_ DM_RedStopLampState : 4|2@1+ (1,0) [0|3] "" Vector__XXX
 SG_ DM_AmberWrningLmpStatus : 2|2@1+ (1,0) [0|3] "" Vector__XXX
 SG_ DM_MalfuncnIndicatorLampStatus : 6|2@1+ (1,0) [0|3] "" Vector__XXX

BO_ 2566834711 DM1_23: 22 IC
 SG_ DTC5 : 144|32@1+ (1,0) [0|4294967295] "" Vector__XXX
 SG_ DTC4 : 112|32@1+ (1,0) [0|4294967295] "" Vector__XXX
 SG_ DTC3 : 80|32@1+ (1,0) [0|4294967295] "" Vector__XXX
 SG_ DTC2 : 48|32@1+ (1,0) [0|4294967295] "" Vector__XXX
 SG_ DTC1 : 16|32@1+ (1,0) [0|4294967295] "" Vector__XXX
 SG_ DM_FlashRedStopLamp : 12|2@1+ (1,0) [0|3] "" Vector__XXX
 SG_ DM_FlashProtectLamp : 8|2@1+ (1,0) [0|3] "" Vector__XXX
 SG_ DM_FlashMalfuncIndicatorLamp : 14|2@1+ (1,0) [0|3] "" Vector__XXX
 SG_ DM_FlashAmberWarningLamp : 10|2@1+ (1,0) [0|3] "" Vector__XXX
 SG_ DM_ProtectLampStatus : 0|2@1+ (1,0) [0|3] "" Vector__XXX
 SG_ DM_RedStopLampState : 4|2@1+ (1,0) [0|3] "" Vector__XXX
 SG_ DM_AmberWrningLmpStatus : 2|2@1+ (1,0) [0|3] "" Vector__XXX
 SG_ DM_MalfuncnIndicatorLampStatus : 6|2@1+ (1,0) [0|3] "" Vector__XXX

BO_ 2566834707 DM1_19: 22 STEERING_CONTROLLER
 SG_ DTC5 : 144|32@1+ (1,0) [0|4294967295] "" Vector__XXX
 SG_ DTC4 : 112|32@1+ (1,0) [0|4294967295] "" Vector__XXX
 SG_ DTC3 : 80|32@1+ (1,0) [0|4294967295] "" Vector__XXX
 SG_ DTC2 : 48|32@1+ (1,0) [0|4294967295] "" Vector__XXX
 SG_ DTC1 : 16|32@1+ (1,0) [0|4294967295] "" Vector__XXX
 SG_ DM_FlashRedStopLamp : 12|2@1+ (1,0) [0|3] "" Vector__XXX
 SG_ DM_FlashProtectLamp : 8|2@1+ (1,0) [0|3] "" Vector__XXX
 SG_ DM_FlashMalfuncIndicatorLamp : 14|2@1+ (1,0) [0|3] "" Vector__XXX
 SG_ DM_FlashAmberWarningLamp : 10|2@1+ (1,0) [0|3] "" Vector__XXX
 SG_ DM_ProtectLampStatus : 0|2@1+ (1,0) [0|3] "" Vector__XXX
 SG_ DM_RedStopLampState : 4|2@1+ (1,0) [0|3] "" Vector__XXX
 SG_ DM_AmberWrningLmpStatus : 2|2@1+ (1,0) [0|3] "" Vector__XXX
 SG_ DM_MalfuncnIndicatorLampStatus : 6|2@1+ (1,0) [0|3] "" Vector__XXX

BO_ 2566834699 DM1_11: 22 ABS
 SG_ DTC5 : 144|32@1+ (1,0) [0|4294967295] "" Vector__XXX
 SG_ DTC4 : 112|32@1+ (1,0) [0|4294967295] "" Vector__XXX
 SG_ DTC3 : 80|32@1+ (1,0) [0|4294967295] "" Vector__XXX
 SG_ DTC2 : 48|32@1+ (1,0) [0|4294967295] "" Vector__XXX
 SG_ DTC1 : 16|32@1+ (1,0) [0|4294967295] "" Vector__XXX
 SG_ DM_FlashRedStopLamp : 12|2@1+ (1,0) [0|3] "" Vector__XXX
 SG_ DM_FlashProtectLamp : 8|2@1+ (1,0) [0|3] "" Vector__XXX
 SG_ DM_FlashMalfuncIndicatorLamp : 14|2@1+ (1,0) [0|3] "" Vector__XXX
 SG_ DM_FlashAmberWarningLamp : 10|2@1+ (1,0) [0|3] "" Vector__XXX
 SG_ DM_ProtectLampStatus : 0|2@1+ (1,0) [0|3] "" Vector__XXX
 SG_ DM_RedStopLampState : 4|2@1+ (1,0) [0|3] "" Vector__XXX
 SG_ DM_AmberWrningLmpStatus : 2|2@1+ (1,0) [0|3] "" Vector__XXX
 SG_ DM_MalfuncnIndicatorLampStatus : 6|2@1+ (1,0) [0|3] "" Vector__XXX

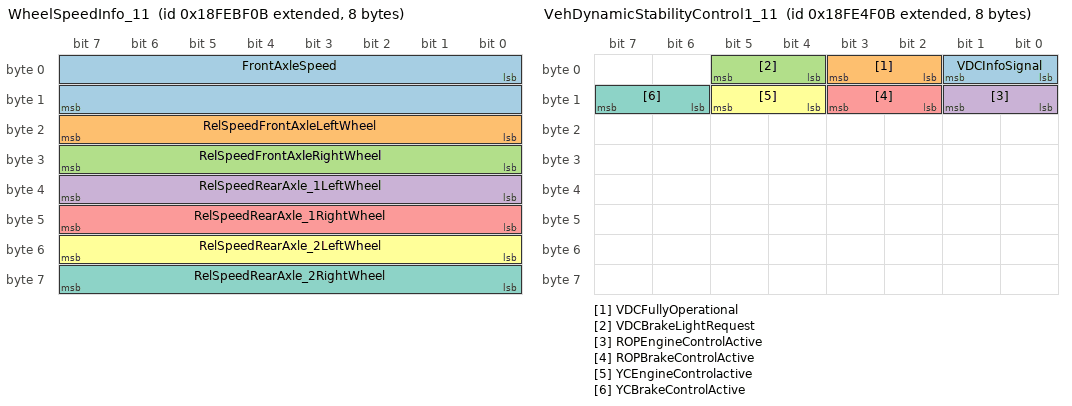
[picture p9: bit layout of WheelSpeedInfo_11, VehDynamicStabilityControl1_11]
BO_ 2566831883 WheelSpeedInfo_11: 8 ABS
 SG_ FrontAxleSpeed : 0|16@1+ (0.00390625,0) [0|251] "km/" Vector__XXX
 SG_ RelSpeedFrontAxleLeftWheel : 16|8@1+ (0.0625,-7.8125) [-7.8125|7.8125] "km/h" Vector__XXX
 SG_ RelSpeedFrontAxleRightWheel : 24|8@1+ (0.0625,-7.8125) [-7.8125|7.8125] "km/h" Vector__XXX
 SG_ RelSpeedRearAxle_1LeftWheel : 32|8@1+ (0.0625,-7.8125) [-7.8125|7.8125] "km/h" Vector__XXX
 SG_ RelSpeedRearAxle_1RightWheel : 40|8@1+ (0.0625,-7.8125) [-7.8125|7.8125] "km/h" Vector__XXX
 SG_ RelSpeedRearAxle_2LeftWheel : 48|8@1+ (0.0625,-7.8125) [-7.8125|7.8125] "km/h" Vector__XXX
 SG_ RelSpeedRearAxle_2RightWheel : 56|8@1+ (0.0625,-7.8125) [-7.8125|7.8125] "km/h" Vector__XXX

BO_ 2566819840 EngineTorqueHistory_0: 8 ECM
 SG_ EnginePeakTorque1 : 8|16@1+ (1,0) [0|64255] "Nm" Vector__XXX

BO_ 2566803211 VehDynamicStabilityControl1_11: 8 ABS
 SG_ VDCInfoSignal : 0|2@1+ (1,0) [0|3] "" Vector__XXX
 SG_ VDCFullyOperational : 2|2@1+ (1,0) [0|3] "" Vector__XXX
 SG_ VDCBrakeLightRequest : 4|2@1+ (1,0) [0|3] "" Vector__XXX
 SG_ ROPEngineControlActive : 8|2@1+ (1,0) [0|3] "" Vector__XXX
 SG_ ROPBrakeControlActive : 10|2@1+ (1,0) [0|3] "" Vector__XXX
 SG_ YCEngineControlactive : 12|2@1+ (1,0) [0|3] "" Vector__XXX
 SG_ YCBrakeControlActive : 14|2@1+ (1,0) [0|3] "" Vector__XXX

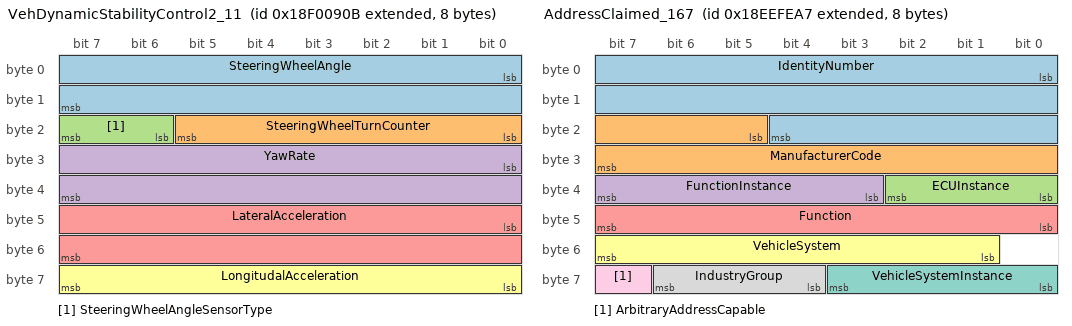
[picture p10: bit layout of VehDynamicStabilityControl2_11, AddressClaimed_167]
BO_ 2565867787 VehDynamicStabilityControl2_11: 8 ABS
 SG_ SteeringWheelAngle : 0|16@1- (0.0009765625,-31.374) [-31.374|31.374] "Rad" Vector__XXX
 SG_ SteeringWheelTurnCounter : 16|6@1+ (1,-32) [-32|31] "" Vector__XXX
 SG_ SteeringWheelAngleSensorType : 22|2@1+ (1,0) [0|3] "" Vector__XXX
 SG_ YawRate : 24|16@1+ (0.0001220703125,-3.92) [-3.92|4.0798779297] "rad/s" Vector__XXX
 SG_ LateralAcceleration : 40|16@1+ (0.00048828125,-15.687) [-15.687|16.312511719] "m/s^2" Vector__XXX
 SG_ LongitudalAcceleration : 56|8@1+ (0.1,-12.5) [-12.5|13] "m/s^2" Vector__XXX

BO_ 2565866240 EEC2_0: 8 ECM
 SG_ AccelPedalPosition1 : 8|8@1+ (0.4,0) [0|100] "%" Vector__XXX

BO_ 2565865739 EBC1_11: 8 ABS
 SG_ ABSActive : 4|2@1+ (1,0) [0|3] "" Vector__XXX
 SG_ ASREngineCtrlActive : 0|2@1+ (1,0) [0|3] "" Vector__XXX
 SG_ ASRBrakeCtrlActive : 2|2@1+ (1,0) [0|3] "" Vector__XXX
 SG_ BrakePedalPosition : 8|8@1+ (0.4,0) [0|100] "%" Vector__XXX
 SG_ ABSOffroadSwitch : 16|2@1+ (1,0) [0|3] "" Vector__XXX
 SG_ ASROffroadSwitch : 18|2@1+ (1,0) [0|3] "" Vector__XXX
 SG_ ASRHillHolderSwitch : 20|2@1+ (1,0) [0|3] "" Vector__XXX
 SG_ EBSBrakeSwitch : 6|2@1+ (1,0) [0|3] "" Vector__XXX
 SG_ DL17_TractionCtrlOverrideSwitch : 22|2@1+ (1,0) [0|0] "" Vector__XXX
 SG_ AcceleratorInterlockSwitch : 24|2@1+ (1,0) [0|3] "" Vector__XXX
 SG_ EngineDerateSwitch : 26|2@1+ (1,0) [0|3] "" Vector__XXX
 SG_ AuxEngineShutdownSwitch : 28|2@1+ (1,0) [0|3] "" Vector__XXX
 SG_ RemoteAcceleratorSwitch : 30|2@1+ (1,0) [0|3] "" Vector__XXX
 SG_ EngineRetarderSelection : 32|8@1+ (0.4,0) [0|100] "%" Vector__XXX
 SG_ ABSFullyOperational : 40|2@1+ (1,0) [0|3] "" Vector__XXX
 SG_ EBSRedWarningState : 42|2@1+ (1,0) [0|3] "" Vector__XXX
 SG_ ABSEBSAmberWarningState : 44|2@1+ (1,0) [0|3] "" Vector__XXX
 SG_ SourceAddress : 48|8@1+ (1,0) [0|253] "" Vector__XXX
 SG_ ATC_ASR_InfoSig : 46|2@1+ (1,0) [0|3] "" Vector__XXX

BO_ 2563833367 CabIlluminationMessage_23: 8 IC
 SG_ IlluminationBrightnessPercent : 0|8@1+ (0.4,0) [0|100] "%" Vector__XXX
 SG_ SwitchBacklightIlluminPercent : 8|8@1+ (0.4,0) [0|100] "%" Vector__XXX

BO_ 2565799591 AddressClaimed_167: 8 IC_2
 SG_ IdentityNumber : 0|21@1+ (1,0) [0|2097151] "" Vector__XXX
 SG_ ManufacturerCode : 21|11@1+ (1,0) [0|2047] "" Vector__XXX
 SG_ ECUInstance : 32|3@1+ (1,0) [0|7] "" Vector__XXX
 SG_ FunctionInstance : 35|5@1+ (1,0) [0|31] "" Vector__XXX
 SG_ Function : 40|8@1+ (1,0) [0|255] "" Vector__XXX
 SG_ VehicleSystem : 49|7@1+ (1,0) [0|127] "" Vector__XXX
 SG_ VehicleSystemInstance : 56|4@1+ (1,0) [0|15] "" Vector__XXX
 SG_ IndustryGroup : 60|3@1+ (1,0) [0|7] "" Vector__XXX
 SG_ ArbitraryAddressCapable : 63|1@1+ (1,0) [0|0] "" Vector__XXX

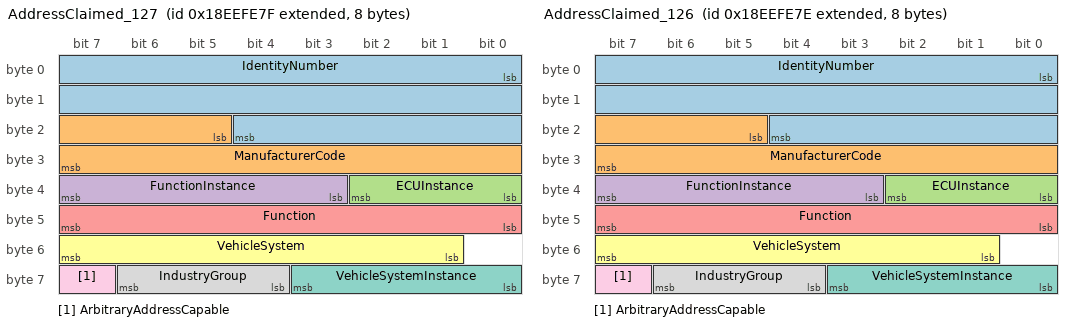
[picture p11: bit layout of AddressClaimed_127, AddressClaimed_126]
BO_ 2565799551 AddressClaimed_127: 8 RADIO_Hub
 SG_ IdentityNumber : 0|21@1+ (1,0) [0|2097151] "" Vector__XXX
 SG_ ManufacturerCode : 21|11@1+ (1,0) [0|2047] "" Vector__XXX
 SG_ ECUInstance : 32|3@1+ (1,0) [0|7] "" Vector__XXX
 SG_ FunctionInstance : 35|5@1+ (1,0) [0|31] "" Vector__XXX
 SG_ Function : 40|8@1+ (1,0) [0|255] "" Vector__XXX
 SG_ VehicleSystem : 49|7@1+ (1,0) [0|127] "" Vector__XXX
 SG_ VehicleSystemInstance : 56|4@1+ (1,0) [0|15] "" Vector__XXX
 SG_ IndustryGroup : 60|3@1+ (1,0) [0|7] "" Vector__XXX
 SG_ ArbitraryAddressCapable : 63|1@1+ (1,0) [0|0] "" Vector__XXX

BO_ 2565799550 AddressClaimed_126: 8 XM
 SG_ IdentityNumber : 0|21@1+ (1,0) [0|2097151] "" Vector__XXX
 SG_ ManufacturerCode : 21|11@1+ (1,0) [0|2047] "" Vector__XXX
 SG_ ECUInstance : 32|3@1+ (1,0) [0|7] "" Vector__XXX
 SG_ FunctionInstance : 35|5@1+ (1,0) [0|31] "" Vector__XXX
 SG_ Function : 40|8@1+ (1,0) [0|255] "" Vector__XXX
 SG_ VehicleSystem : 49|7@1+ (1,0) [0|127] "" Vector__XXX
 SG_ VehicleSystemInstance : 56|4@1+ (1,0) [0|15] "" Vector__XXX
 SG_ IndustryGroup : 60|3@1+ (1,0) [0|7] "" Vector__XXX
 SG_ ArbitraryAddressCapable : 63|1@1+ (1,0) [0|0] "" Vector__XXX

CM_ BO_ 2566877696 "pVehicle Temperature 1";
CM_ SG_ 2566877696 pLeftHandGripTemp "Temperature of the Left Hand grip";
CM_ SG_ 2566877696 pRightHandGripTemp "Temperature of the Right Hand grip";
CM_ BO_ 2566877463 "Instrument Cluster Information";
CM_ SG_ 2566877463 pVolumeUnitsSelected "Active display volume units beased on user selection or auto-configuration.";
CM_ SG_ 2566877463 pTimeUnitsSelected "Active display time units beased on user selection or auto-configuration.";
CM_ SG_ 2566877463 pTemperatureUnitsSelected "Active display temperature units beased on user selection or auto-configuration.";
CM_ SG_ 2566877463 pPressureUnitsSelected "Active display pressure units beased on user selection or auto-configuration.";
CM_ SG_ 2566877463 pHighResTrip2Distance "Secondary distance travled during all or part of a journey.";
CM_ SG_ 2566877463 pDistanceUnitsSelected "Active display distance units beased on user selection or auto-configuration.";
CM_ SG_ 2566877463 pTPMSLearningStatus "Status of the Tire Pressure Monitor System learning process.";
CM_ SG_ 2566877463 pDisplayStatus "Status of the radio display to the radio stating what the display is showing";
CM_ BO_ 2566876711 "Vehicle Fluid Information";
CM_ SG_ 2566876711 pEngineOilPressureStatus "Pressure Status of the Engine Oil";
CM_ SG_ 2566876711 pHydraulicOilPressureStatus "Pressure Status of the Hydraulic Oil Pressure";
CM_ SG_ 2566876711 pHydraulicOilTempStatus "Status of the hydraulic oil temperature";
CM_ BO_ 2633984551 "Status of Drive System Information";
CM_ SG_ 2633984551 pHeatedGripEnable "Indicates if the controller broadcasting this SPN is calibrated to support vehicle speed limit 3";
CM_ SG_ 2633984551 pSideStandStatus "Status of the side stand switch of a motorcycle";
CM_ SG_ 2633984551 pTetherSwitchStatus "Status of the Tether Switch";
CM_ SG_ 2633984551 pLowFuelIndicatorStatus "Broadcasting the status of the fuel level for user indication.";
CM_ SG_ 2633984551 pOperatorNotInOperatingStation "Status of Operator presence in a vehicle";
CM_ SG_ 2633984551 pParkBrakeIndicatorStatus "Broadcasting the status of the park brake for user indication";
CM_ SG_ 2633984551 pADCRequested "Broadcasting the status of the users request for ADC mode";
CM_ SG_ 2633984551 pAWDModeRequested "Broadcasting the status of the users request for AWD mode";
CM_ SG_ 2633984551 pRWDModeRequested "Broadcasting the status of the users request for RWD mode";
CM_ SG_ 2633984551 pTurfModeRequested "Broadcasting the status of the users request for TURF mode";
CM_ SG_ 2633984551 pADCStatus "Broadcasting the status of the ADC (active indicates the solenoid is powered)";
CM_ SG_ 2633984551 pTreadleNeutralStatus "Broadcasting the status of the switch indicating the treadle is/is not in the Neutral position";
CM_ SG_ 2633984551 pTreadleReverseStatus "Broadcasting the status of the switch indicating the treadle is/is not in the Reverse position";
CM_ SG_ 2633984551 pSecurityLightStatus "Broadcasting the status of the security system for user indication";
CM_ SG_ 2633984551 pHighBeamIndicatorStatus "Broadcasting the status of the high beam headlight for user indication";
CM_ SG_ 2633984551 pHeatedGripsPercentage "Heated Grips Percent On, 0% is Off and 100% is the maximum heat";
CM_ SG_ 2633984551 pCruiseControlSetStatus "Broadcasting the status of the Cruise Control Set Status for user indication";
CM_ SG_ 2633984551 pSeatBeltIndicatorStatus "Broadcasting the status of the seat belt for user indication";
CM_ BO_ 2432656679 "Indicates the status of multiple operator controlled switches.";
CM_ SG_ 2432656679 pOperatorButton29 "Drive Mode - 1()";
CM_ SG_ 2432656679 pOperatorButton1 "Instrument Cluster Control - 1";
CM_ SG_ 2432656679 pOperatorButton2 "Instrument Cluster Control  - 2";
CM_ SG_ 2432656679 pOperatorButton3 "Headlamp - 1 (Low)";
CM_ SG_ 2432656679 pOperatorButton4 "Headlamp - 2 (High)";
CM_ SG_ 2432656679 pOperatorButton5 "Headlamp - 3 (Driving)";
CM_ SG_ 2432656679 pOperatorButton6 "Turn - 1 (Left)";
CM_ SG_ 2432656679 pOperatorButton7 "Turn - 2 (Right)";
CM_ SG_ 2432656679 pOperatorButton8 "Turn - 3 (Cancel)";
CM_ SG_ 2432656679 pOperatorButton9 "Hazard";
CM_ SG_ 2432656679 pOperatorButton10 "Cruise - 1 (On)";
CM_ SG_ 2432656679 pOperatorButton11 "Cruise - 2 (Set)";
CM_ SG_ 2432656679 pOperatorButton12 "Cruise - 3 (Accel)";
CM_ SG_ 2432656679 pOperatorButton13 "Horn";
CM_ SG_ 2432656679 pOperatorButton14 "Start";
CM_ SG_ 2432656679 pOperatorButton15 "Warmer - 1";
CM_ SG_ 2432656679 pOperatorButton16 "Warmer - 2";
CM_ SG_ 2432656679 pOperatorButton17 "Warmer - 3";
CM_ SG_ 2432656679 pOperatorButton18 "Warmer - 4";
CM_ SG_ 2432656679 pOperatorButton19 "Windshield Wiper";
CM_ SG_ 2432656679 pOperatorButton20 "Engine On";
CM_ SG_ 2432656679 pOperatorButton21 "Reverse";
CM_ SG_ 2432656679 pOperatorButton22 "Homelink 1";
CM_ SG_ 2432656679 pOperatorButton23 "Homelink 2";
CM_ SG_ 2432656679 pOperatorButton24 "Throttle Safety Switch - 1";
CM_ SG_ 2432656679 pOperatorButton25 "Windshield - 1 (Up)";
CM_ SG_ 2432656679 pOperatorButton26 "Windshield - 2 (Down)";
CM_ SG_ 2432656679 pOperatorButton27 "Hand Brake Switch";
CM_ SG_ 2432656679 pOperatorButton28 "Clutch Switch";
CM_ SG_ 2432656679 pSideStandStatus "Status of the side stand switch of a motorcycle";
CM_ BO_ 2566845479 "Tire Condition";
CM_ SG_ 2566845479 TireLocation "Identifies which tire is associated with the parametric data in this PGN.";
CM_ SG_ 2566845479 TirePressure "Pressure at which air is contained in cavity formed by tire and rim.";
CM_ SG_ 2566845479 TireTemperature "Temperature at the surface of the tire sidewall.";
CM_ BO_ 2566844711 "Cruise Control Status and Vehicle Speed Information";
CM_ SG_ 2566844711 pCruiseCntrlCounter "Rolling Counter (ensures updated message is used).";
CM_ SG_ 2566844711 TwoSpeedAxleSwitch "Switch signal which indicates the current axle range.";
CM_ SG_ 2566844711 ParkingBrakeSwitch "Switch signal which indicates when the parking brake is set. In general the switch actuated by the operator's park brake control,
whether a pedal, lever, or other control mechanism.";
CM_ SG_ 2566844711 Wheel_BasedVehicleSpeed "Speed of the vehicle as calculated from wheel or tailshaft speed.";
CM_ SG_ 2566844711 CruiseCtrlActive "Cruise control is switched on.  It is not ensured that the engine is controlled by cruise control, as in the case of a large driver's demand the engine is controlled by the driver while
cruise control is active.";
CM_ SG_ 2566844711 CruiseCtrlEnableSwitch "Switch signal which indicates that it is possible to manage the cruise control function";
CM_ SG_ 2566844711 BrakeSwitch "Switch signal which indicates that the driver operated brake foot pedal is being pressed";
CM_ SG_ 2566844711 ClutchSwitch "Switch signal which indicates that the clutch pedal is being pressed.  It is necessary for a safe drivetrain behavior that the clutch switch is set before the clutch is opened (cruise control function).";
CM_ SG_ 2566844711 CruiseCtrlSetSwitch "Switch signal of the cruise control activator which indicates that the activator is in the position 'set'.";
CM_ SG_ 2566844711 CruiseCtrlCoastSwitch "Switch signal of the cruise control activator which indicates that the activator is in the position 'coast'";
CM_ SG_ 2566844711 CruiseCtrlResumeSwitch "Switch signal of the cruise control activator which indicates that the activator is in the position 'resume'";
CM_ SG_ 2566844711 CruiseCtrlAccelerateSwitch "Switch signal of the cruise control activator which indicates that the activator is in the position 'accelerate'";
CM_ SG_ 2566844711 CruiseCtrlSetSpeed "Value of set (chosen) velocity of velocity control system.";
CM_ SG_ 2566844711 pOdometerDriveBit "Alternate state (A->B, B->A) each time the vehicle has moved a defined distance (currently 40m).";
CM_ SG_ 2566844711 CruiseCtrlPauseSw "Switch signal which indicates the positon of the Cruise Control Pause Switch used on Remote Cruise Control applications. The Cruise Control Pause Switch signal temporarily
disables the Cruise Control function.";
CM_ SG_ 2566844711 pCCChecksum "XOR of bytes 0-6 (ensures data is valid before use)";
CM_ SG_ 2566844711 pCruiseEnableStatus "The Cruise Control System has been enabled by the operator.  (Amber Light)";
CM_ BO_ 2566841895 "Contains system time and date information";
CM_ SG_ 2566841895 Minutes "The minutes component of the current time of day.";
CM_ SG_ 2566841895 Hours "The hour component of the current time of day.";
CM_ SG_ 2566841895 LocalHourOffset "The hour component of the offset between the UTC (Universal Time Coordinate) time and date and a local time zone time
and date.";
CM_ SG_ 2566841895 Seconds "Seconds component of the current time of day.";
CM_ SG_ 2566841895 Day "The day component of the current calendar date.";
CM_ SG_ 2566841895 Month "The month component of the current calendar date.";
CM_ SG_ 2566841895 Year "The year component of the current calendar date.";
CM_ BO_ 2565866791 "Electronic Transmission Controller 2";
CM_ SG_ 2565866791 TransmissionSelectedGear "The gear that the transmission will attempt to achieve during the current shift if a shift is in progress,
or the next shift if one is pending";
CM_ SG_ 2565866791 TransmissionActualGearRatio "Actual ratio of input shaft speed to output shaft speed";
CM_ SG_ 2565866791 TransmissionCurrentGear "The gear currently engaged in the transmission or the last gear engaged while the transmission is in
the process of shifting to the new or selected gear";
CM_ SG_ 2565866791 TransmissionRqstedRange "Range selected by the operator.";
CM_ SG_ 2565866791 TransmissionCurrentRange "Range currently being commanded by the transmission control system.";
CM_ BO_ 2565799463 "Used to claim an address by a module.";
CM_ BO_ 2631794215 "Used by the interface device to lock or unlock the lockabe/unlockable device.";
CM_ SG_ 2631794215 EncryptionIndicatorStates "This parameter is used to indicate if a random number of seed is being requested, or if an encrypted password is being provided
to the component.";
CM_ SG_ 2631794215 AntiTheftDesiredExitModeStates "This parameter is used to specify the desired triggers that are to be used by the component  in deciding when
to transition to the locked states.";
CM_ SG_ 2631794215 AntiTheftCommandStates "This parameter is used to identify the specific requests being sent to the component.";
CM_ SG_ 2631794215 AntiTheftPasswordRepresentation "This parameter is the 7-byte numeric code that is generated based on the encryption algorithm,
the password supplied by the end user, and the random number seed giben by the component.
";
CM_ BO_ 2550791719 "Static Roll Angle Sensor Information";
CM_ SG_ 2550791719 StaticRollAngle "The measured static roll angle between the vehicle y-axis and the ground plane about the X-axis.";
CM_ SG_ 2550791719 StaticRollAngleStatus "Status of the transmitted roll angle data.";
CM_ BO_ 2566842495 "Vehicle dynamics information";
CM_ SG_ 2566842495 CompassBearing "Present compass bearing of vehicle.";
CM_ BO_ 2365473024 "The lighting command message has been defined as a global message from the vehicle to all lighting controllers on the
tractor and attached implements.";
CM_ SG_ 2365473024 LowBeamHeadlightCommand "Command to activate or de-activate the tractor low beam head light lamps.";
CM_ SG_ 2365473024 HighBeamHeadlightCommand "Command to activate or de-activate the tractor high beam head light lamps.";
CM_ SG_ 2365473024 LeftTurnSigLightsCommand "Command to activate or de-activate left turn signal lights";
CM_ SG_ 2365473024 RightTurnSigLightsCommand "Command to activate or de-activate right turn signal lights on the tractor and all connected implements";
CM_ BO_ 2631859735 "Used to reset parameters of a controller when requested by the user or other controlling device.";
CM_ SG_ 2631859735 TripGroup1 "Command signal used to reset the PGNs and parameters as defined in Table SPN988_A.";
CM_ SG_ 2631859735 TripGroup2 "Command signal used to reset proprietary parameters associated with a trip but not defined in SAE J1939-71

Polaris defined paremeters to reset: PGN65266 Fuel Economy (Liquid), SPN 185 Average Fuel Economy";
CM_ SG_ 2631859735 ServiceComponentIdentification "Not approved for use at Polaris at this time.

(Identification of component needing service.)";
CM_ SG_ 2631859735 EngineBuildHoursReset "Not approved for use at Polaris at this time.

(Command signal used to reset the engine rebuild hours.)";
CM_ BO_ 2564161047 "Time and Date Adjustment Information";
CM_ SG_ 2564161047 AdjustDay "The day component for setting the current calendar date.";
CM_ SG_ 2564161047 AdjustHours "The hours component for setting the current time of day.";
CM_ SG_ 2564161047 AdjustLocalHourOffset "The hour component for setting the offset between the UTC (Universal Time Coordinate) time and date and a the local
time zone time and date.";
CM_ SG_ 2564161047 AdjustMinutes "The minutes component for setting the current time of day.";
CM_ SG_ 2564161047 AdjustMonth "The month component for setting the current calendar date.";
CM_ SG_ 2564161047 AdjustSeconds "The seconds component for setting the current time of day.";
CM_ SG_ 2564161047 AdjustYear "The year component for setting the current calendar date.";
CM_ SG_ 2564161047 AdjustLocalMinuteOffset "The minute component for setting the offset between the UTC (Universal Time Coordinate) time and date and a the local
time zone time and date.";
CM_ BO_ 2550201867 "Torque/Speed Control 1";
CM_ SG_ 2550201867 EngOverrideCtlMode "The override control mode defines which sort of command is used.";
CM_ SG_ 2550201867 EngReqSpeedControlCond "This mode tells the engine control system the governor characteristics that are desired during speed control.";
CM_ SG_ 2550201867 OverrideCtlModePriority "This field is used as an input to the engine or retarder to determine the priority of the Override Control Mode received in the Torque/Speed Control message (PGN 0).";
CM_ SG_ 2550201867 EngReqSpeedLimit "Parameter provided to the engine from external sources in the torque/speed control message. This is the engine speed which the engine is expected to operate at (speed control mode) or not
to exceed (speed limit mode).";
CM_ SG_ 2550201867 EngReqTorqueLimit "Parameter provided to the engine or retarder in the torque/speed control message for controlling or limiting the output torque.";
CM_ SG_ 2550201867 TSC1_TransmissionRate "This parameter indicates the transmission rate at which the sending device will transmit the TSC1 message. The engine
shall adjust its timeout for TSC1 messages accordingly.";
CM_ SG_ 2550201867 EngineRequestedTorque_HiRes "This parameter displays an additional torque in percent of the reference engine torque.";
CM_ SG_ 2550201867 MessageChecksum "The message checksum is used to verify the signal path from the transmitting device to the receiving device.";
CM_ BO_ 2566878847 "Device Status Information";
CM_ SG_ 2566878847 pHeadset2ConnectionStatus "Used to send the connection status of a connected Bluetooth headset. This typically will be the driver headset.";
CM_ SG_ 2566878847 pHeadset1ConnectionStatus "Used to send the connection status of a connected Bluetooth headset. This typically will be the driver headset.";
CM_ SG_ 2566878847 pDevice2CellSigStrength "Used to send the cell signal strength of a cell device to the infotainment display. This typically will be the driver device.";
CM_ SG_ 2566878847 pDevice2BTConnectStatus "Used to send the connection status of a connected Bluetooth device. This typically will be the driver device.";
CM_ SG_ 2566878847 pDevice2BattStrength "Used to send the battery strength of a connected device to the infotainment display. This typically will be the driver device.";
CM_ SG_ 2566878847 pDevice1CellSigStrength "Used to send the cell signal strength of a cell device to the infotainment display. This typically will be the driver device.";
CM_ SG_ 2566878847 pDevice1BTConnectStatus "Used to send the connection status of a connected Bluetooth device. This typically will be the driver device.";
CM_ SG_ 2566878847 pDevice1BattStrength "Used to send the battery strength of a connected device to the infotainment display. This typically will be the driver device.";
CM_ BO_ 2566877505 "Instrument Cluster Information";
CM_ SG_ 2566877505 pVolumeUnitsSelected "Active display volume units beased on user selection or auto-configuration.";
CM_ SG_ 2566877505 pTimeUnitsSelected "Active display time units beased on user selection or auto-configuration.";
CM_ SG_ 2566877505 pTemperatureUnitsSelected "Active display temperature units beased on user selection or auto-configuration.";
CM_ SG_ 2566877505 pPressureUnitsSelected "Active display pressure units beased on user selection or auto-configuration.";
CM_ SG_ 2566877505 pHighResTrip2Distance "Secondary distance travled during all or part of a journey.";
CM_ SG_ 2566877505 pDistanceUnitsSelected "Active display distance units beased on user selection or auto-configuration.";
CM_ SG_ 2566877505 pTPMSLearningStatus "Status of the Tire Pressure Monitor System learning process.";
CM_ SG_ 2566877505 pDisplayStatus "Status of the radio display to the radio stating what the display is showing";
CM_ BO_ 2566877311 "pRadio Display 1";
CM_ SG_ 2566877311 pHighlightRow "Number of row to highlight on the display.";
CM_ SG_ 2566877311 pScreenAreaMode "Broadcasting the type of information data being sent";
CM_ SG_ 2566877311 pRadioInputDevice "Broadcasting the source the radio is playing";
CM_ SG_ 2566877311 pRadioInputValue "Numerical value of channel or volume for display.";
CM_ SG_ 2566877311 pRadioScaling "Where to put the decimal for the pRadioScaling signal.";
CM_ SG_ 2566877311 pTextLineConfiguration "Number of lines of text being sent to the display";
CM_ SG_ 2566877311 pStereoStatus "Broadcasting the status of the radio reception";
CM_ SG_ 2566877311 pFirstRowConfiguration "Used to setup the radio display layout.";
CM_ SG_ 2566877311 pScreenAreaConfiguration "Used to setup the display screen size.";
CM_ BO_ 2432656449 "Infotaiment Button Status";
CM_ SG_ 2432656449 pInfotainmentJoystick2 "Switch signal which requests that all engine fueling and spark stop.";
CM_ SG_ 2432656449 pInfotainmentJoystick1 "Switch signal which requests that all engine fueling and spark stop.";
CM_ SG_ 2432656449 pInfotainmentRemoteButton01 "Volume Down";
CM_ SG_ 2432656449 pInfotainmentRemoteButton02 "Volume Up";
CM_ SG_ 2432656449 pInfotainmentRemoteButton03 "Tune Down";
CM_ SG_ 2432656449 pInfotainmentRemoteButton04 "Tune Up";
CM_ SG_ 2432656449 pInfotainmentRemoteButton05 "Source";
CM_ SG_ 2432656449 pInfotainmentRemoteButton06 "Mute";
CM_ SG_ 2432656449 pInfotainmentRemoteButton07 "ICOM";
CM_ SG_ 2432656449 pInfotainmentRemoteButton08 "COM";
CM_ SG_ 2432656449 pInfotainmentRemoteButton09 "Squelch (SQ) Down";
CM_ SG_ 2432656449 pInfotainmentRemoteButton10 "Squelch (SQ) Up";
CM_ SG_ 2432656449 pInfotainmentRemoteButton11 "Push To Talk (PTT)";
CM_ SG_ 2432656449 pInfotainmentRemoteButton12 "Preset";
CM_ BO_ 2566874899 "Signal group for Electric Power Assisted Steering";
CM_ SG_ 2566874899 pSensedInputSteeringTorque "?";
CM_ SG_ 2566874899 pSensedOutputSteeringTorque "?";
CM_ SG_ 2566874899 pGeneratedCurrentCommand "?";
CM_ SG_ 2566874899 pVTemp "Temperature of the PCB near the motor inverter.  Used to derate or turn off the inverter based on preset limits.";
CM_ BO_ 2566846219 "Vehicle Electrical Power Information";
CM_ SG_ 2566846219 NetBatteryCurrent "Net flow of electrical current into/out of the battery or batteries.";
CM_ SG_ 2566846219 AlternatorCurrent "Measure of electrical current flow from the alternator. Alternator Current (High Range/Resolution) parameter SPN 1795 has a higher range and resolution of the same parameter.";
CM_ SG_ 2566846219 ChargingSystemPotential "Electrical potential measured at the charging system output. The charging system may be any device charging the batteries. This includes alternators, generators, solid state charger,
and other charging devices.";
CM_ SG_ 2566846219 BatteryPotential "This parameter measures the first souce of battery potential as measured at the input of the ECM/actuator etc. coming from one or more batteries, irrespective of the distance between the component
and the battery.";
CM_ SG_ 2566846219 KeyswitchBatteryPotential "Battery potential measured at the input of the electronic control unit supplied through a keyswitch or similar switching device.";
CM_ BO_ 2566846227 "Vehicle Electrical Power Information";
CM_ SG_ 2566846227 NetBatteryCurrent "Net flow of electrical current into/out of the battery or batteries.";
CM_ SG_ 2566846227 AlternatorCurrent "Measure of electrical current flow from the alternator. Alternator Current (High Range/Resolution) parameter SPN 1795 has a higher range and resolution of the same parameter.";
CM_ SG_ 2566846227 ChargingSystemPotential "Electrical potential measured at the charging system output. The charging system may be any device charging the batteries. This includes alternators, generators, solid state charger,
and other charging devices.";
CM_ SG_ 2566846227 BatteryPotential "This parameter measures the first souce of battery potential as measured at the input of the ECM/actuator etc. coming from one or more batteries, irrespective of the distance between the component
and the battery.";
CM_ SG_ 2566846227 KeyswitchBatteryPotential "Battery potential measured at the input of the electronic control unit supplied through a keyswitch or similar switching device.";
CM_ BO_ 2566844683 "Cruise Control Status and Vehicle Speed Information";
CM_ SG_ 2566844683 TwoSpeedAxleSwitch "Switch signal which indicates the current axle range.";
CM_ SG_ 2566844683 ParkingBrakeSwitch "Switch signal which indicates when the parking brake is set. In general the switch actuated by the operator's park brake control,
whether a pedal, lever, or other control mechanism.";
CM_ SG_ 2566844683 Wheel_BasedVehicleSpeed "Speed of the vehicle as calculated from wheel or tailshaft speed.";
CM_ SG_ 2566844683 CruiseCtrlActive "Cruise control is switched on.  It is not ensured that the engine is controlled by cruise control, as in the case of a large driver's demand the engine is controlled by the driver while
cruise control is active.";
CM_ SG_ 2566844683 CruiseCtrlEnableSwitch "Switch signal which indicates that it is possible to manage the cruise control function";
CM_ SG_ 2566844683 BrakeSwitch "Switch signal which indicates that the driver operated brake foot pedal is being pressed";
CM_ SG_ 2566844683 ClutchSwitch "Switch signal which indicates that the clutch pedal is being pressed.  It is necessary for a safe drivetrain behavior that the clutch switch is set before the clutch is opened (cruise control function).";
CM_ SG_ 2566844683 CruiseCtrlSetSwitch "Switch signal of the cruise control activator which indicates that the activator is in the position 'set'.";
CM_ SG_ 2566844683 CruiseCtrlCoastSwitch "Switch signal of the cruise control activator which indicates that the activator is in the position 'coast'";
CM_ SG_ 2566844683 CruiseCtrlResumeSwitch "Switch signal of the cruise control activator which indicates that the activator is in the position 'resume'";
CM_ SG_ 2566844683 CruiseCtrlAccelerateSwitch "Switch signal of the cruise control activator which indicates that the activator is in the position 'accelerate'";
CM_ SG_ 2566844683 CruiseCtrlSetSpeed "Value of set (chosen) velocity of velocity control system.";
CM_ SG_ 2566844683 pOdometerDriveBit "Alternate state (A->B, B->A) each time the vehicle has moved a defined distance (currently 40m).";
CM_ SG_ 2566844683 CruiseCtrlPauseSw "Switch signal which indicates the positon of the Cruise Control Pause Switch used on Remote Cruise Control applications. The Cruise Control Pause Switch signal temporarily
disables the Cruise Control function.";
CM_ SG_ 2566844683 pCCChecksum "XOR of bytes 0-6 (ensures data is valid before use)";
CM_ SG_ 2566844683 pCruiseEnableStatus "The Cruise Control System has been enabled by the operator.  (Amber Light)";
CM_ SG_ 2566844683 pCCMessageCounter "Rolling Counter (ensures updated message is used)";
CM_ BO_ 2566844839 "Cruise Control Status and Vehicle Speed Information";
CM_ SG_ 2566844839 TwoSpeedAxleSwitch "Switch signal which indicates the current axle range.";
CM_ SG_ 2566844839 ParkingBrakeSwitch "Switch signal which indicates when the parking brake is set. In general the switch actuated by the operator's park brake control,
whether a pedal, lever, or other control mechanism.";
CM_ SG_ 2566844839 Wheel_BasedVehicleSpeed "Speed of the vehicle as calculated from wheel or tailshaft speed.";
CM_ SG_ 2566844839 CruiseCtrlActive "Cruise control is switched on.  It is not ensured that the engine is controlled by cruise control, as in the case of a large driver's demand the engine is controlled by the driver while
cruise control is active.";
CM_ SG_ 2566844839 CruiseCtrlEnableSwitch "Switch signal which indicates that it is possible to manage the cruise control function";
CM_ SG_ 2566844839 BrakeSwitch "Switch signal which indicates that the driver operated brake foot pedal is being pressed";
CM_ SG_ 2566844839 ClutchSwitch "Switch signal which indicates that the clutch pedal is being pressed.  It is necessary for a safe drivetrain behavior that the clutch switch is set before the clutch is opened (cruise control function).";
CM_ SG_ 2566844839 CruiseCtrlSetSwitch "Switch signal of the cruise control activator which indicates that the activator is in the position 'set'.";
CM_ SG_ 2566844839 CruiseCtrlCoastSwitch "Switch signal of the cruise control activator which indicates that the activator is in the position 'coast'";
CM_ SG_ 2566844839 CruiseCtrlResumeSwitch "Switch signal of the cruise control activator which indicates that the activator is in the position 'resume'";
CM_ SG_ 2566844839 CruiseCtrlAccelerateSwitch "Switch signal of the cruise control activator which indicates that the activator is in the position 'accelerate'";
CM_ SG_ 2566844839 CruiseCtrlSetSpeed "Value of set (chosen) velocity of velocity control system.";
CM_ SG_ 2566844839 pOdometerDriveBit "Alternate state (A->B, B->A) each time the vehicle has moved a defined distance (currently 40m).";
CM_ SG_ 2566844839 CruiseCtrlPauseSw "Switch signal which indicates the positon of the Cruise Control Pause Switch used on Remote Cruise Control applications. The Cruise Control Pause Switch signal temporarily
disables the Cruise Control function.";
CM_ SG_ 2566844839 pCCChecksum "XOR of bytes 0-6 (ensures data is valid before use)";
CM_ SG_ 2566844839 pCruiseEnableStatus "The Cruise Control System has been enabled by the operator.  (Amber Light)";
CM_ SG_ 2566844839 pCruiseCntrlCounter "Rolling Counter (ensures updated message is used).";
CM_ BO_ 2566834855 "Active diagnostic trouble codes";
CM_ SG_ 2566834855 DTC5 "Diagnostic Trouble Code";
CM_ SG_ 2566834855 DTC4 "Diagnostic Trouble Code";
CM_ SG_ 2566834855 DTC3 "Diagnostic Trouble Code";
CM_ SG_ 2566834855 DTC2 "Diagnostic Trouble Code";
CM_ SG_ 2566834855 DTC1 "Diagnostic Trouble Code";
CM_ SG_ 2566834855 DM_FlashRedStopLamp "Flash status of the Red Stop Lamp";
CM_ SG_ 2566834855 DM_FlashProtectLamp "Flash status of the Stop Protect Lamp";
CM_ SG_ 2566834855 DM_FlashMalfuncIndicatorLamp "Flash status of the Malfunction Indicator Lamp";
CM_ SG_ 2566834855 DM_FlashAmberWarningLamp "Flash status of the Amber Warning Lamp";
CM_ SG_ 2566834855 DM_ProtectLampStatus "This lamp is used to relay trouble code informatio that is reporting a problem with a vehicle system that is most
probably not electronic subsystem related.";
CM_ SG_ 2566834855 DM_RedStopLampState "This lamp is uesed to relay trouble code information that is of a severe enought condition that it warrants stopping the vehicle.";
CM_ SG_ 2566834855 DM_AmberWrningLmpStatus "This lamp is used to relay trouble code information that is reporting a problem with the vehicle system but the vehicle need
not be immediately stopped.";
CM_ SG_ 2566834855 DM_MalfuncnIndicatorLampStatus "A lamp used to relay only emissions-related trouble code information.";
CM_ BO_ 2566834815 "Active diagnostic trouble codes";
CM_ SG_ 2566834815 DTC5 "Diagnostic Trouble Code";
CM_ SG_ 2566834815 DTC4 "Diagnostic Trouble Code";
CM_ SG_ 2566834815 DTC3 "Diagnostic Trouble Code";
CM_ SG_ 2566834815 DTC2 "Diagnostic Trouble Code";
CM_ SG_ 2566834815 DTC1 "Diagnostic Trouble Code";
CM_ SG_ 2566834815 DM_FlashRedStopLamp "Flash status of the Red Stop Lamp";
CM_ SG_ 2566834815 DM_FlashProtectLamp "Flash status of the Stop Protect Lamp";
CM_ SG_ 2566834815 DM_FlashMalfuncIndicatorLamp "Flash status of the Malfunction Indicator Lamp";
CM_ SG_ 2566834815 DM_FlashAmberWarningLamp "Flash status of the Amber Warning Lamp";
CM_ SG_ 2566834815 DM_ProtectLampStatus "This lamp is used to relay trouble code informatio that is reporting a problem with a vehicle system that is most
probably not electronic subsystem related.";
CM_ SG_ 2566834815 DM_RedStopLampState "This lamp is uesed to relay trouble code information that is of a severe enought condition that it warrants stopping the vehicle.";
CM_ SG_ 2566834815 DM_AmberWrningLmpStatus "This lamp is used to relay trouble code information that is reporting a problem with the vehicle system but the vehicle need
not be immediately stopped.";
CM_ SG_ 2566834815 DM_MalfuncnIndicatorLampStatus "A lamp used to relay only emissions-related trouble code information.";
CM_ BO_ 2566834814 "Active diagnostic trouble codes";
CM_ SG_ 2566834814 DTC5 "Diagnostic Trouble Code";
CM_ SG_ 2566834814 DTC4 "Diagnostic Trouble Code";
CM_ SG_ 2566834814 DTC3 "Diagnostic Trouble Code";
CM_ SG_ 2566834814 DTC2 "Diagnostic Trouble Code";
CM_ SG_ 2566834814 DTC1 "Diagnostic Trouble Code";
CM_ SG_ 2566834814 DM_FlashRedStopLamp "Flash status of the Red Stop Lamp";
CM_ SG_ 2566834814 DM_FlashProtectLamp "Flash status of the Stop Protect Lamp";
CM_ SG_ 2566834814 DM_FlashMalfuncIndicatorLamp "Flash status of the Malfunction Indicator Lamp";
CM_ SG_ 2566834814 DM_FlashAmberWarningLamp "Flash status of the Amber Warning Lamp";
CM_ SG_ 2566834814 DM_ProtectLampStatus "This lamp is used to relay trouble code informatio that is reporting a problem with a vehicle system that is most
probably not electronic subsystem related.";
CM_ SG_ 2566834814 DM_RedStopLampState "This lamp is uesed to relay trouble code information that is of a severe enought condition that it warrants stopping the vehicle.";
CM_ SG_ 2566834814 DM_AmberWrningLmpStatus "This lamp is used to relay trouble code information that is reporting a problem with the vehicle system but the vehicle need
not be immediately stopped.";
CM_ SG_ 2566834814 DM_MalfuncnIndicatorLampStatus "A lamp used to relay only emissions-related trouble code information.";
CM_ BO_ 2566834812 "Active diagnostic trouble codes";
CM_ SG_ 2566834812 DTC5 "Diagnostic Trouble Code";
CM_ SG_ 2566834812 DTC4 "Diagnostic Trouble Code";
CM_ SG_ 2566834812 DTC3 "Diagnostic Trouble Code";
CM_ SG_ 2566834812 DTC2 "Diagnostic Trouble Code";
CM_ SG_ 2566834812 DTC1 "Diagnostic Trouble Code";
CM_ SG_ 2566834812 DM_FlashRedStopLamp "Flash status of the Red Stop Lamp";
CM_ SG_ 2566834812 DM_FlashProtectLamp "Flash status of the Stop Protect Lamp";
CM_ SG_ 2566834812 DM_FlashMalfuncIndicatorLamp "Flash status of the Malfunction Indicator Lamp";
CM_ SG_ 2566834812 DM_FlashAmberWarningLamp "Flash status of the Amber Warning Lamp";
CM_ SG_ 2566834812 DM_ProtectLampStatus "This lamp is used to relay trouble code informatio that is reporting a problem with a vehicle system that is most
probably not electronic subsystem related.";
CM_ SG_ 2566834812 DM_RedStopLampState "This lamp is uesed to relay trouble code information that is of a severe enought condition that it warrants stopping the vehicle.";
CM_ SG_ 2566834812 DM_AmberWrningLmpStatus "This lamp is used to relay trouble code information that is reporting a problem with the vehicle system but the vehicle need
not be immediately stopped.";
CM_ SG_ 2566834812 DM_MalfuncnIndicatorLampStatus "A lamp used to relay only emissions-related trouble code information.";
CM_ BO_ 2566834808 "Active diagnostic trouble codes";
CM_ SG_ 2566834808 DTC5 "Diagnostic Trouble Code";
CM_ SG_ 2566834808 DTC4 "Diagnostic Trouble Code";
CM_ SG_ 2566834808 DTC3 "Diagnostic Trouble Code";
CM_ SG_ 2566834808 DTC2 "Diagnostic Trouble Code";
CM_ SG_ 2566834808 DTC1 "Diagnostic Trouble Code";
CM_ SG_ 2566834808 DM_FlashRedStopLamp "Flash status of the Red Stop Lamp";
CM_ SG_ 2566834808 DM_FlashProtectLamp "Flash status of the Stop Protect Lamp";
CM_ SG_ 2566834808 DM_FlashMalfuncIndicatorLamp "Flash status of the Malfunction Indicator Lamp";
CM_ SG_ 2566834808 DM_FlashAmberWarningLamp "Flash status of the Amber Warning Lamp";
CM_ SG_ 2566834808 DM_ProtectLampStatus "This lamp is used to relay trouble code informatio that is reporting a problem with a vehicle system that is most
probably not electronic subsystem related.";
CM_ SG_ 2566834808 DM_RedStopLampState "This lamp is uesed to relay trouble code information that is of a severe enought condition that it warrants stopping the vehicle.";
CM_ SG_ 2566834808 DM_AmberWrningLmpStatus "This lamp is used to relay trouble code information that is reporting a problem with the vehicle system but the vehicle need
not be immediately stopped.";
CM_ SG_ 2566834808 DM_MalfuncnIndicatorLampStatus "A lamp used to relay only emissions-related trouble code information.";
CM_ BO_ 2566834937 "Active diagnostic trouble codes";
CM_ SG_ 2566834937 DTC5 "Diagnostic Trouble Code";
CM_ SG_ 2566834937 DTC4 "Diagnostic Trouble Code";
CM_ SG_ 2566834937 DTC3 "Diagnostic Trouble Code";
CM_ SG_ 2566834937 DTC2 "Diagnostic Trouble Code";
CM_ SG_ 2566834937 DTC1 "Diagnostic Trouble Code";
CM_ SG_ 2566834937 DM_FlashRedStopLamp "Flash status of the Red Stop Lamp";
CM_ SG_ 2566834937 DM_FlashProtectLamp "Flash status of the Stop Protect Lamp";
CM_ SG_ 2566834937 DM_FlashMalfuncIndicatorLamp "Flash status of the Malfunction Indicator Lamp";
CM_ SG_ 2566834937 DM_FlashAmberWarningLamp "Flash status of the Amber Warning Lamp";
CM_ SG_ 2566834937 DM_ProtectLampStatus "This lamp is used to relay trouble code informatio that is reporting a problem with a vehicle system that is most
probably not electronic subsystem related.";
CM_ SG_ 2566834937 DM_RedStopLampState "This lamp is uesed to relay trouble code information that is of a severe enought condition that it warrants stopping the vehicle.";
CM_ SG_ 2566834937 DM_AmberWrningLmpStatus "This lamp is used to relay trouble code information that is reporting a problem with the vehicle system but the vehicle need
not be immediately stopped.";
CM_ SG_ 2566834937 DM_MalfuncnIndicatorLampStatus "A lamp used to relay only emissions-related trouble code information.";
CM_ BO_ 2566834753 "Active diagnostic trouble codes";
CM_ SG_ 2566834753 DTC5 "Diagnostic Trouble Code";
CM_ SG_ 2566834753 DTC4 "Diagnostic Trouble Code";
CM_ SG_ 2566834753 DTC3 "Diagnostic Trouble Code";
CM_ SG_ 2566834753 DTC2 "Diagnostic Trouble Code";
CM_ SG_ 2566834753 DTC1 "Diagnostic Trouble Code";
CM_ SG_ 2566834753 DM_FlashRedStopLamp "Flash status of the Red Stop Lamp";
CM_ SG_ 2566834753 DM_FlashProtectLamp "Flash status of the Stop Protect Lamp";
CM_ SG_ 2566834753 DM_FlashMalfuncIndicatorLamp "Flash status of the Malfunction Indicator Lamp";
CM_ SG_ 2566834753 DM_FlashAmberWarningLamp "Flash status of the Amber Warning Lamp";
CM_ SG_ 2566834753 DM_ProtectLampStatus "This lamp is used to relay trouble code informatio that is reporting a problem with a vehicle system that is most
probably not electronic subsystem related.";
CM_ SG_ 2566834753 DM_RedStopLampState "This lamp is uesed to relay trouble code information that is of a severe enought condition that it warrants stopping the vehicle.";
CM_ SG_ 2566834753 DM_AmberWrningLmpStatus "This lamp is used to relay trouble code information that is reporting a problem with the vehicle system but the vehicle need
not be immediately stopped.";
CM_ SG_ 2566834753 DM_MalfuncnIndicatorLampStatus "A lamp used to relay only emissions-related trouble code information.";
CM_ BO_ 2566834717 "Active diagnostic trouble codes";
CM_ SG_ 2566834717 DTC5 "Diagnostic Trouble Code";
CM_ SG_ 2566834717 DTC4 "Diagnostic Trouble Code";
CM_ SG_ 2566834717 DTC3 "Diagnostic Trouble Code";
CM_ SG_ 2566834717 DTC2 "Diagnostic Trouble Code";
CM_ SG_ 2566834717 DTC1 "Diagnostic Trouble Code";
CM_ SG_ 2566834717 DM_FlashRedStopLamp "Flash status of the Red Stop Lamp";
CM_ SG_ 2566834717 DM_FlashProtectLamp "Flash status of the Stop Protect Lamp";
CM_ SG_ 2566834717 DM_FlashMalfuncIndicatorLamp "Flash status of the Malfunction Indicator Lamp";
CM_ SG_ 2566834717 DM_FlashAmberWarningLamp "Flash status of the Amber Warning Lamp";
CM_ SG_ 2566834717 DM_ProtectLampStatus "This lamp is used to relay trouble code informatio that is reporting a problem with a vehicle system that is most
probably not electronic subsystem related.";
CM_ SG_ 2566834717 DM_RedStopLampState "This lamp is uesed to relay trouble code information that is of a severe enought condition that it warrants stopping the vehicle.";
CM_ SG_ 2566834717 DM_AmberWrningLmpStatus "This lamp is used to relay trouble code information that is reporting a problem with the vehicle system but the vehicle need
not be immediately stopped.";
CM_ SG_ 2566834717 DM_MalfuncnIndicatorLampStatus "A lamp used to relay only emissions-related trouble code information.";
CM_ BO_ 2566834711 "Active diagnostic trouble codes";
CM_ SG_ 2566834711 DTC5 "Diagnostic Trouble Code";
CM_ SG_ 2566834711 DTC4 "Diagnostic Trouble Code";
CM_ SG_ 2566834711 DTC3 "Diagnostic Trouble Code";
CM_ SG_ 2566834711 DTC2 "Diagnostic Trouble Code";
CM_ SG_ 2566834711 DTC1 "Diagnostic Trouble Code";
CM_ SG_ 2566834711 DM_FlashRedStopLamp "Flash status of the Red Stop Lamp";
CM_ SG_ 2566834711 DM_FlashProtectLamp "Flash status of the Stop Protect Lamp";
CM_ SG_ 2566834711 DM_FlashMalfuncIndicatorLamp "Flash status of the Malfunction Indicator Lamp";
CM_ SG_ 2566834711 DM_FlashAmberWarningLamp "Flash status of the Amber Warning Lamp";
CM_ SG_ 2566834711 DM_ProtectLampStatus "This lamp is used to relay trouble code informatio that is reporting a problem with a vehicle system that is most
probably not electronic subsystem related.";
CM_ SG_ 2566834711 DM_RedStopLampState "This lamp is uesed to relay trouble code information that is of a severe enought condition that it warrants stopping the vehicle.";
CM_ SG_ 2566834711 DM_AmberWrningLmpStatus "This lamp is used to relay trouble code information that is reporting a problem with the vehicle system but the vehicle need
not be immediately stopped.";
CM_ SG_ 2566834711 DM_MalfuncnIndicatorLampStatus "A lamp used to relay only emissions-related trouble code information.";
CM_ BO_ 2566834707 "Active diagnostic trouble codes";
CM_ SG_ 2566834707 DTC5 "Diagnostic Trouble Code";
CM_ SG_ 2566834707 DTC4 "Diagnostic Trouble Code";
CM_ SG_ 2566834707 DTC3 "Diagnostic Trouble Code";
CM_ SG_ 2566834707 DTC2 "Diagnostic Trouble Code";
CM_ SG_ 2566834707 DTC1 "Diagnostic Trouble Code";
CM_ SG_ 2566834707 DM_FlashRedStopLamp "Flash status of the Red Stop Lamp";
CM_ SG_ 2566834707 DM_FlashProtectLamp "Flash status of the Stop Protect Lamp";
CM_ SG_ 2566834707 DM_FlashMalfuncIndicatorLamp "Flash status of the Malfunction Indicator Lamp";
CM_ SG_ 2566834707 DM_FlashAmberWarningLamp "Flash status of the Amber Warning Lamp";
CM_ SG_ 2566834707 DM_ProtectLampStatus "This lamp is used to relay trouble code informatio that is reporting a problem with a vehicle system that is most
probably not electronic subsystem related.";
CM_ SG_ 2566834707 DM_RedStopLampState "This lamp is uesed to relay trouble code information that is of a severe enought condition that it warrants stopping the vehicle.";
CM_ SG_ 2566834707 DM_AmberWrningLmpStatus "This lamp is used to relay trouble code information that is reporting a problem with the vehicle system but the vehicle need
not be immediately stopped.";
CM_ SG_ 2566834707 DM_MalfuncnIndicatorLampStatus "A lamp used to relay only emissions-related trouble code information.";
CM_ BO_ 2566834699 "Active diagnostic trouble codes";
CM_ SG_ 2566834699 DTC5 "Diagnostic Trouble Code";
CM_ SG_ 2566834699 DTC4 "Diagnostic Trouble Code";
CM_ SG_ 2566834699 DTC3 "Diagnostic Trouble Code";
CM_ SG_ 2566834699 DTC2 "Diagnostic Trouble Code";
CM_ SG_ 2566834699 DTC1 "Diagnostic Trouble Code";
CM_ SG_ 2566834699 DM_FlashRedStopLamp "Flash status of the Red Stop Lamp";
CM_ SG_ 2566834699 DM_FlashProtectLamp "Flash status of the Stop Protect Lamp";
CM_ SG_ 2566834699 DM_FlashMalfuncIndicatorLamp "Flash status of the Malfunction Indicator Lamp";
CM_ SG_ 2566834699 DM_FlashAmberWarningLamp "Flash status of the Amber Warning Lamp";
CM_ SG_ 2566834699 DM_ProtectLampStatus "This lamp is used to relay trouble code informatio that is reporting a problem with a vehicle system that is most
probably not electronic subsystem related.";
CM_ SG_ 2566834699 DM_RedStopLampState "This lamp is uesed to relay trouble code information that is of a severe enought condition that it warrants stopping the vehicle.";
CM_ SG_ 2566834699 DM_AmberWrningLmpStatus "This lamp is used to relay trouble code information that is reporting a problem with the vehicle system but the vehicle need
not be immediately stopped.";
CM_ SG_ 2566834699 DM_MalfuncnIndicatorLampStatus "A lamp used to relay only emissions-related trouble code information.";
CM_ BO_ 2566831883 "Wheel Speed Information of individual or multiple wheels on a vehicle";
CM_ SG_ 2566831883 FrontAxleSpeed "The average speed of the two front wheels.  If the front axle has only 1 wheel, the value is equal to the speed of the single wheel.";
CM_ SG_ 2566831883 RelSpeedFrontAxleLeftWheel "The speed of the front axle, left wheel relative to the front axle speed. The value of this message should be zero if the front axle has only 1 wheel.";
CM_ SG_ 2566831883 RelSpeedFrontAxleRightWheel "The speed of the front axle, right wheel relative to the front axle speed. The value of this message should be zero if the axle has only 1 wheel.";
CM_ SG_ 2566831883 RelSpeedRearAxle_1LeftWheel "The speed of the rear axle #1, left wheel relative to the front.axle speed. Use this message if the rear axle #1 has only 1 wheel.";
CM_ SG_ 2566831883 RelSpeedRearAxle_1RightWheel "The speed of the rear axle #1, right wheel relative to the front axle speed. If the rear axle #1 has only 1 wheel, use the left wheel message (SPN 907).";
CM_ SG_ 2566831883 RelSpeedRearAxle_2LeftWheel "The speed of the rear axle #2, left wheel relative to the front axle speed";
CM_ SG_ 2566831883 RelSpeedRearAxle_2RightWheel "The speed of the rear axle #2, right wheel relative to the front axle speed";
CM_ BO_ 2566819840 "Use of the limit mode allows the use of the
retarder only up to the limit specified in the request.";
CM_ SG_ 2566819840 EnginePeakTorque1 "Maximum torque output of the current ECU calibration when the engine operates on torque curve 1.";
CM_ BO_ 2566803211 "Contains information which relates to the VDC system status";
CM_ SG_ 2566803211 VDCInfoSignal "This parameter commands the VDC info signal, for example a dash lamp";
CM_ SG_ 2566803211 VDCFullyOperational "Indicates wether VDC is fully operational or not";
CM_ SG_ 2566803211 VDCBrakeLightRequest "Indicates wether VDC requests to turn the vehicle brake lights on";
CM_ SG_ 2566803211 ROPEngineControlActive "Indicates wether Roll Over Protection (ROP) is active or not";
CM_ SG_ 2566803211 ROPBrakeControlActive "Indicates wether ROP (Roll Over Protection) Brake Control is active";
CM_ SG_ 2566803211 YCEngineControlactive "Indicates wether YC (Yaw Control) is active or not";
CM_ SG_ 2566803211 YCBrakeControlActive "Indicates wether YC (Yaw Control) has activated brake control or not";
CM_ BO_ 2565867787 "Contains information which relates to the vehicle's movement.";
CM_ SG_ 2565867787 SteeringWheelAngle "The main operator's steering wheel angle (on the steering column, not the actual wheel angle). The vehicle being steered to the left results in a positive steering wheel angle.";
CM_ SG_ 2565867787 SteeringWheelTurnCounter "Indicates number of steering wheel turns, absolute position or relative position at ignition on.  Positive values indicate left turns.";
CM_ SG_ 2565867787 SteeringWheelAngleSensorType "Indicates whether the steering wheel angle sensor is capable of absolute measuring of the number of steering wheel turns or not (relative measuring to position at ignition on).";
CM_ SG_ 2565867787 YawRate "Rate of rotation about the vertical axis.  Positive raw rate results when the vehicle turns counter-clockwise.";
CM_ SG_ 2565867787 LateralAcceleration "Indicates a lateral acceleration of the vehicle (the component of vehicle acceleration vector along the Y-axis).";
CM_ SG_ 2565867787 LongitudalAcceleration "Indicates the longitudinal acceleration of the vehicle.";
CM_ BO_ 2565866240 "Identifies electronic engine control related parameters";
CM_ SG_ 2565866240 AccelPedalPosition1 "The ratio of actual position of the analog engine speed/torque request input device to the maximum position of the input device.";
CM_ BO_ 2565865739 "Electronic brake controller #1
Used for brake control information";
CM_ SG_ 2565865739 ABSActive "State signal which indicates that the ABS is active.  The signal is set when wheel brake pressure actually starts to be modulated by ABS and is reset when all wheels are in a stable condition
for a certain time.";
CM_ SG_ 2565865739 ASREngineCtrlActive "Not approved for use at Polaris at this time.

(State signal which indicates that ASR engine control has been commanded to be active)";
CM_ SG_ 2565865739 ASRBrakeCtrlActive "Not approved for use at Polaris at this time.

(State signal which indicates that ASR brake control is active)";
CM_ SG_ 2565865739 BrakePedalPosition "Not approved for use at Polaris at this time.";
CM_ SG_ 2565865739 ABSOffroadSwitch "Not approved for use at Polaris at this time.

(Switch signal which indicates the position of the ASR off-road switch)";
CM_ SG_ 2565865739 ASROffroadSwitch "Not approved for use at Polaris at this time.

(Switch signal which indicates the position of the ASR off-road switch)";
CM_ SG_ 2565865739 ASRHillHolderSwitch "Not approved for use at Polaris at this time.

(Switch signal which indicates the position of the ASR 'hill holder' switch)";
CM_ SG_ 2565865739 EBSBrakeSwitch "Not approved for use at Polaris at this time.

(Switch signal which indicates that the brake pedal is being pressed.)";
CM_ SG_ 2565865739 AcceleratorInterlockSwitch "Not approved for use at Polaris at this time.

(Switch signal used to disable the accelerator and remote accelerator input, causing the engine to return to idle.)";
CM_ SG_ 2565865739 EngineDerateSwitch "Not approved for use at Polaris at this time.

(Switch signal used to activate the torque limiting feature of the engine.)";
CM_ SG_ 2565865739 AuxEngineShutdownSwitch "Not approved for use at Polaris at this time.

(Switch signal which requests that all engine fueling stop.)";
CM_ SG_ 2565865739 RemoteAcceleratorSwitch "Not approved for use at Polaris at this time.

(Switch signal which indicates that the rmote accelerator has been enabled and controls the engine.)";
CM_ SG_ 2565865739 EngineRetarderSelection "Not approved for use at Polaris at this time.

(The percent engine retarder torque requested by the operator as percent of maximum braking torque at the current retarder speed.)";
CM_ SG_ 2565865739 ABSFullyOperational "Signal which indicates wether an ABS system is fully operational or wether its functionality is reduced by a defect or by an intended action.";
CM_ SG_ 2565865739 EBSRedWarningState "Not approved for use at Polaris at this time.

(The EBS red warning state is set if critical EBS faults are detected and the vehicle has to stop.)";
CM_ SG_ 2565865739 ABSEBSAmberWarningState "The ABS/EBS amber warning state is set as non-critical faults are detected in the ABS/EBS system.";
CM_ SG_ 2565865739 SourceAddress "Source address of controlling device for brake control.";
CM_ SG_ 2565865739 ATC_ASR_InfoSig "This parameter commands the ATC/ASR driver information signal, for example a dash lamp.  Used to control the amber traction control disabled lamp.";
CM_ BO_ 2563833367 "This message contains information that controls illumination devices inside the vehicle's cab.";
CM_ SG_ 2563833367 IlluminationBrightnessPercent "Commanded backlight brightness level for all cab displays.";
CM_ SG_ 2563833367 SwitchBacklightIlluminPercent "Commanded switch backlight brightness level for all operator control switches. This is separate from the cab display
illumination Brightness Percent parameter.";
CM_ BO_ 2565799591 "Used to claim an address by a module.";
CM_ BO_ 2565799551 "Used to claim an address by a module.";
CM_ BO_ 2565799550 "Used to claim an address by a module.";
BA_DEF_ SG_  "GenSigSendType" ENUM  "Cyclic","OnWrite","OnWriteWithRepetition","OnChange","OnChangeWithRepetition","IfActive","IfActiveWithRepetition","NoSigSendType";
BA_DEF_ SG_  "GenSigStartValue" INT 0 10000;
BA_DEF_ SG_  "GenSigEVName" STRING ;
BA_DEF_ SG_  "SPN" INT 0 524287;
BA_DEF_ SG_  "SigType" ENUM  "Default","Range","RangeSigned","ASCII","Discrete","Control","ReferencePGN","DTC","StringDelimiter","StringLength","StringLengthControl","MessageCounter","MessageChecksum";
BA_DEF_ SG_  "GenSigILSupport" ENUM  "No","Yes";
BA_DEF_ BO_  "GenMsgCycleTimeFast" INT 0 3600000;
BA_DEF_ BO_  "GenMsgILSupport" ENUM  "No","Yes";
BA_DEF_ BO_  "J1939PGNameSecSrc0Dest3" STRING ;
BA_DEF_ BO_  "J1939PGRelationDest3Src0" INT 0 254;
BA_DEF_ BO_  "J1939PGtoECUSrc0Dest3" INT 0 254;
BA_DEF_ BO_  "J1939PGtoWSMSrc0Dest3" INT 0 254;
BA_DEF_ BO_  "J1939PGRelationSrc0Dest3" INT 0 254;
BA_DEF_ BO_  "J1939PGRepTypeSrc0Dest3" INT 0 4;
BA_DEF_ BO_  "J1939PGRepCycleSrc0Dest3" INT -1 65535;
BA_DEF_ BO_  "J1939PGPrioSrc0Dest3" INT 0 7;
BA_DEF_ BO_  "J1939PGRepetitionType" ENUM  "always","when active","on request";
BA_DEF_ BO_  "J1939PGRepetitionCycle" INT 0 65535;
BA_DEF_ BO_  "J1939PGPrio" INT 0 7;
BA_DEF_ BO_  "VFrameFormat" ENUM  "StandardCAN","ExtendedCAN","reserved","J1939PG";
BA_DEF_ BO_  "GenMsgCycleTime" INT 0 3600000;
BA_DEF_ BO_  "GenMsgRequestable" INT 0 1;
BA_DEF_ BO_  "GenMsgSendType" ENUM  "cyclic","spontaneous","cyclicIfActive","spontaneousWithDelay","cyclicAndSpontaneous","cyclicAndSpontaneousWithDelay","spontaneousWithRepetition","cyclicIfActiveAndSpontaneousWD";
BA_DEF_DEF_  "GenSigSendType" "NoSigSendType";
BA_DEF_DEF_  "GenSigStartValue" 0;
BA_DEF_DEF_  "GenSigEVName" "Env@Nodename_@Signame";
BA_DEF_DEF_  "SPN" 0;
BA_DEF_DEF_  "SigType" "Default";
BA_DEF_DEF_  "GenSigILSupport" "Yes";
BA_DEF_DEF_  "GenMsgCycleTimeFast" 0;
BA_DEF_DEF_  "GenMsgILSupport" "Yes";
BA_DEF_DEF_  "J1939PGNameSecSrc0Dest3" "(null)";
BA_DEF_DEF_  "J1939PGRelationDest3Src0" 254;
BA_DEF_DEF_  "J1939PGtoECUSrc0Dest3" -1;
BA_DEF_DEF_  "J1939PGtoWSMSrc0Dest3" -1;
BA_DEF_DEF_  "J1939PGRelationSrc0Dest3" 254;
BA_DEF_DEF_  "J1939PGRepTypeSrc0Dest3" 3;
BA_DEF_DEF_  "J1939PGRepCycleSrc0Dest3" -1;
BA_DEF_DEF_  "J1939PGPrioSrc0Dest3" 6;
BA_DEF_DEF_  "J1939PGRepetitionType" "always";
BA_DEF_DEF_  "J1939PGRepetitionCycle" 100;
BA_DEF_DEF_  "J1939PGPrio" 6;
BA_DEF_DEF_  "VFrameFormat" "J1939PG";
BA_DEF_DEF_  "GenMsgCycleTime" 0;
BA_DEF_DEF_  "GenMsgRequestable" 1;
BA_DEF_DEF_  "GenMsgSendType" "cyclic";
BA_ "GenMsgCycleTime" BO_ 2566885888 100;
BA_ "GenMsgCycleTime" BO_ 2566877696 1000;
BA_ "GenMsgCycleTime" BO_ 2566877463 1000;
BA_ "GenMsgCycleTime" BO_ 2566876711 1000;
BA_ "GenMsgCycleTime" BO_ 2633984551 100;
BA_ "GenMsgCycleTime" BO_ 2432656679 100;
BA_ "GenMsgCycleTime" BO_ 2566845479 10000;
BA_ "GenMsgCycleTime" BO_ 2566844711 100;
BA_ "GenMsgCycleTime" BO_ 2566841895 60000;
BA_ "GenMsgCycleTime" BO_ 2565866791 100;
BA_ "GenMsgCycleTime" BO_ 2565799463 100;
BA_ "GenMsgCycleTime" BO_ 2631794215 100;
BA_ "GenMsgCycleTime" BO_ 2550791719 100;
BA_ "GenMsgCycleTime" BO_ 2566842495 100;
BA_ "GenMsgCycleTime" BO_ 2365473024 100;
BA_ "GenMsgCycleTime" BO_ 2631859735 100;
BA_ "GenMsgCycleTime" BO_ 2564161047 100;
BA_ "GenMsgCycleTime" BO_ 2550201867 100;
BA_ "GenMsgCycleTime" BO_ 2566878847 1000;
BA_ "GenMsgCycleTime" BO_ 2566877505 1000;
BA_ "GenMsgCycleTime" BO_ 2566877311 1000;
BA_ "GenMsgCycleTime" BO_ 2432656449 200;
BA_ "GenMsgCycleTime" BO_ 2566874899 100;
BA_ "GenMsgCycleTime" BO_ 2566846219 1000;
BA_ "GenMsgCycleTime" BO_ 2566846227 1000;
BA_ "GenMsgCycleTime" BO_ 2566844683 100;
BA_ "GenMsgCycleTime" BO_ 2566844839 100;
BA_ "GenMsgCycleTime" BO_ 2566834855 100;
BA_ "GenMsgCycleTime" BO_ 2566834815 100;
BA_ "GenMsgCycleTime" BO_ 2566834814 100;
BA_ "GenMsgCycleTime" BO_ 2566834812 100;
BA_ "GenMsgCycleTime" BO_ 2566834808 100;
BA_ "GenMsgCycleTime" BO_ 2566834937 100;
BA_ "GenMsgCycleTime" BO_ 2566834753 100;
BA_ "GenMsgCycleTime" BO_ 2566834717 100;
BA_ "GenMsgCycleTime" BO_ 2566834711 100;
BA_ "GenMsgCycleTime" BO_ 2566834707 100;
BA_ "GenMsgCycleTime" BO_ 2566834699 100;
BA_ "GenMsgCycleTime" BO_ 2566831883 100;
BA_ "GenMsgCycleTime" BO_ 2566819840 1000;
BA_ "GenMsgCycleTime" BO_ 2566803211 100;
BA_ "GenMsgCycleTime" BO_ 2565867787 100;
BA_ "GenMsgCycleTime" BO_ 2565866240 100;
BA_ "GenMsgCycleTime" BO_ 2565865739 100;
BA_ "GenMsgCycleTime" BO_ 2563833367 100;
BA_ "GenMsgCycleTime" BO_ 2565799591 100;
BA_ "GenMsgCycleTime" BO_ 2565799551 100;
BA_ "GenMsgCycleTime" BO_ 2565799550 100;
BA_ "SigType" SG_ 2566885888 DL_InjectorBank_APulseWidth 1.7E-308;
BA_ "SigType" SG_ 2566885888 DL_InjectorBank_BPulseWidth 1.7E-308;
BA_ "SigType" SG_ 2566885888 DL_RequiredFuelFlowRate 1.7E-308;
BA_ "SigType" SG_ 2566885888 DL_Airflow 1.7E-308;
BA_ "SPN" SG_ 2566877696 pLeftHandGripTemp 524109;
BA_ "SigType" SG_ 2566877696 pLeftHandGripTemp 1.7E-308;
BA_ "SPN" SG_ 2566877696 pRightHandGripTemp 524110;
BA_ "SigType" SG_ 2566877696 pRightHandGripTemp 1.7E-308;
BA_ "SPN" SG_ 2566877463 pVolumeUnitsSelected 524267;
BA_ "SPN" SG_ 2566877463 pTimeUnitsSelected 524268;
BA_ "SPN" SG_ 2566877463 pTemperatureUnitsSelected 524266;
BA_ "SPN" SG_ 2566877463 pPressureUnitsSelected 524269;
BA_ "SPN" SG_ 2566877463 pHighResTrip2Distance 524264;
BA_ "SPN" SG_ 2566877463 pDistanceUnitsSelected 524265;
BA_ "SPN" SG_ 2566877463 pTPMSLearningStatus 524104;
BA_ "SigType" SG_ 2566877463 pTPMSLearningStatus 1.7E-308;
BA_ "SPN" SG_ 2566877463 pDisplayStatus 524105;
BA_ "SigType" SG_ 2566877463 pDisplayStatus 1.7E-308;
BA_ "SPN" SG_ 2566876711 pEngineOilPressureStatus 524076;
BA_ "SigType" SG_ 2566876711 pEngineOilPressureStatus 1.7E-308;
BA_ "SPN" SG_ 2566876711 pHydraulicOilPressureStatus 524075;
BA_ "SigType" SG_ 2566876711 pHydraulicOilPressureStatus 1.7E-308;
BA_ "SPN" SG_ 2566876711 pHydraulicOilTempStatus 524074;
BA_ "SigType" SG_ 2566876711 pHydraulicOilTempStatus 1.7E-308;
BA_ "SPN" SG_ 2633984551 pHeatedGripEnable 520366;
BA_ "SPN" SG_ 2633984551 pSideStandStatus 524098;
BA_ "SigType" SG_ 2633984551 pSideStandStatus 1.7E-308;
BA_ "SPN" SG_ 2633984551 pTetherSwitchStatus 520600;
BA_ "SPN" SG_ 2633984551 pLowFuelIndicatorStatus 524087;
BA_ "SPN" SG_ 2633984551 pOperatorNotInOperatingStation 2832;
BA_ "SPN" SG_ 2633984551 pParkBrakeIndicatorStatus 524271;
BA_ "SPN" SG_ 2633984551 pADCRequested 524139;
BA_ "SPN" SG_ 2633984551 pAWDModeRequested 524138;
BA_ "SPN" SG_ 2633984551 pRWDModeRequested 524137;
BA_ "SPN" SG_ 2633984551 pTurfModeRequested 524136;
BA_ "SPN" SG_ 2633984551 pADCStatus 524013;
BA_ "SigType" SG_ 2633984551 pADCStatus 1.7E-308;
BA_ "SPN" SG_ 2633984551 pTreadleNeutralStatus 524017;
BA_ "SigType" SG_ 2633984551 pTreadleNeutralStatus 1.7E-308;
BA_ "SPN" SG_ 2633984551 pTreadleReverseStatus 524018;
BA_ "SigType" SG_ 2633984551 pTreadleReverseStatus 1.7E-308;
BA_ "SPN" SG_ 2633984551 pSecurityLightStatus 524019;
BA_ "SigType" SG_ 2633984551 pSecurityLightStatus 1.7E-308;
BA_ "SPN" SG_ 2633984551 pHighBeamIndicatorStatus 524084;
BA_ "SigType" SG_ 2633984551 pHighBeamIndicatorStatus 1.7E-308;
BA_ "SPN" SG_ 2633984551 pHeatedGripsPercentage 524096;
BA_ "SigType" SG_ 2633984551 pHeatedGripsPercentage 1.7E-308;
BA_ "SPN" SG_ 2633984551 pCruiseControlSetStatus 524097;
BA_ "SigType" SG_ 2633984551 pCruiseControlSetStatus 1.7E-308;
BA_ "SPN" SG_ 2633984551 pSeatBeltIndicatorStatus 524092;
BA_ "SigType" SG_ 2633984551 pSeatBeltIndicatorStatus 1.7E-308;
BA_ "SPN" SG_ 2432656679 pOperatorButton29 524060;
BA_ "SPN" SG_ 2432656679 pOperatorButton1 524059;
BA_ "SigType" SG_ 2432656679 pOperatorButton1 1.7E-308;
BA_ "SPN" SG_ 2432656679 pOperatorButton2 524058;
BA_ "SigType" SG_ 2432656679 pOperatorButton2 1.7E-308;
BA_ "SPN" SG_ 2432656679 pOperatorButton3 524057;
BA_ "SigType" SG_ 2432656679 pOperatorButton3 1.7E-308;
BA_ "SPN" SG_ 2432656679 pOperatorButton4 524056;
BA_ "SigType" SG_ 2432656679 pOperatorButton4 1.7E-308;
BA_ "SPN" SG_ 2432656679 pOperatorButton5 524055;
BA_ "SigType" SG_ 2432656679 pOperatorButton5 1.7E-308;
BA_ "SPN" SG_ 2432656679 pOperatorButton6 524054;
BA_ "SigType" SG_ 2432656679 pOperatorButton6 1.7E-308;
BA_ "SPN" SG_ 2432656679 pOperatorButton7 524053;
BA_ "SigType" SG_ 2432656679 pOperatorButton7 1.7E-308;
BA_ "SPN" SG_ 2432656679 pOperatorButton8 524052;
BA_ "SigType" SG_ 2432656679 pOperatorButton8 1.7E-308;
BA_ "SPN" SG_ 2432656679 pOperatorButton9 524051;
BA_ "SigType" SG_ 2432656679 pOperatorButton9 1.7E-308;
BA_ "SPN" SG_ 2432656679 pOperatorButton10 524050;
BA_ "SigType" SG_ 2432656679 pOperatorButton10 1.7E-308;
BA_ "SPN" SG_ 2432656679 pOperatorButton11 524049;
BA_ "SigType" SG_ 2432656679 pOperatorButton11 1.7E-308;
BA_ "SPN" SG_ 2432656679 pOperatorButton12 524048;
BA_ "SigType" SG_ 2432656679 pOperatorButton12 1.7E-308;
BA_ "SPN" SG_ 2432656679 pOperatorButton13 524047;
BA_ "SigType" SG_ 2432656679 pOperatorButton13 1.7E-308;
BA_ "SPN" SG_ 2432656679 pOperatorButton14 524046;
BA_ "SigType" SG_ 2432656679 pOperatorButton14 1.7E-308;
BA_ "SPN" SG_ 2432656679 pOperatorButton15 524045;
BA_ "SigType" SG_ 2432656679 pOperatorButton15 1.7E-308;
BA_ "SPN" SG_ 2432656679 pOperatorButton16 524044;
BA_ "SigType" SG_ 2432656679 pOperatorButton16 1.7E-308;
BA_ "SPN" SG_ 2432656679 pOperatorButton17 524043;
BA_ "SigType" SG_ 2432656679 pOperatorButton17 1.7E-308;
BA_ "SPN" SG_ 2432656679 pOperatorButton18 524042;
BA_ "SigType" SG_ 2432656679 pOperatorButton18 1.7E-308;
BA_ "SPN" SG_ 2432656679 pOperatorButton19 524041;
BA_ "SigType" SG_ 2432656679 pOperatorButton19 1.7E-308;
BA_ "SPN" SG_ 2432656679 pOperatorButton20 524040;
BA_ "SigType" SG_ 2432656679 pOperatorButton20 1.7E-308;
BA_ "SPN" SG_ 2432656679 pOperatorButton21 524039;
BA_ "SigType" SG_ 2432656679 pOperatorButton21 1.7E-308;
BA_ "SPN" SG_ 2432656679 pOperatorButton22 524038;
BA_ "SigType" SG_ 2432656679 pOperatorButton22 1.7E-308;
BA_ "SPN" SG_ 2432656679 pOperatorButton23 524037;
BA_ "SigType" SG_ 2432656679 pOperatorButton23 1.7E-308;
BA_ "SPN" SG_ 2432656679 pOperatorButton24 524036;
BA_ "SigType" SG_ 2432656679 pOperatorButton24 1.7E-308;
BA_ "SPN" SG_ 2432656679 pOperatorButton25 524035;
BA_ "SigType" SG_ 2432656679 pOperatorButton25 1.7E-308;
BA_ "SPN" SG_ 2432656679 pOperatorButton26 524034;
BA_ "SigType" SG_ 2432656679 pOperatorButton26 1.7E-308;
BA_ "SPN" SG_ 2432656679 pOperatorButton27 520322;
BA_ "SigType" SG_ 2432656679 pOperatorButton27 1.7E-308;
BA_ "SPN" SG_ 2432656679 pOperatorButton28 524032;
BA_ "SigType" SG_ 2432656679 pOperatorButton28 1.7E-308;
BA_ "SPN" SG_ 2432656679 pSideStandStatus 524098;
BA_ "SigType" SG_ 2432656679 pSideStandStatus 1.7E-308;
BA_ "SPN" SG_ 2566845479 TireLocation 929;
BA_ "SigType" SG_ 2566845479 TireLocation 1.7E-308;
BA_ "SPN" SG_ 2566845479 TirePressure 241;
BA_ "SigType" SG_ 2566845479 TirePressure 1.7E-308;
BA_ "SPN" SG_ 2566845479 TireTemperature 242;
BA_ "SigType" SG_ 2566845479 TireTemperature 1.7E-308;
BA_ "GenSigStartValue" SG_ 2566844711 pCruiseCntrlCounter 7;
BA_ "SPN" SG_ 2566844711 pCruiseCntrlCounter 524080;
BA_ "SPN" SG_ 2566844711 TwoSpeedAxleSwitch 69;
BA_ "SigType" SG_ 2566844711 TwoSpeedAxleSwitch 1.7E-308;
BA_ "SPN" SG_ 2566844711 ParkingBrakeSwitch 70;
BA_ "SigType" SG_ 2566844711 ParkingBrakeSwitch 1.7E-308;
BA_ "SPN" SG_ 2566844711 Wheel_BasedVehicleSpeed 84;
BA_ "SigType" SG_ 2566844711 Wheel_BasedVehicleSpeed 1.7E-308;
BA_ "SPN" SG_ 2566844711 CruiseCtrlActive 595;
BA_ "SigType" SG_ 2566844711 CruiseCtrlActive 1.7E-308;
BA_ "SPN" SG_ 2566844711 CruiseCtrlEnableSwitch 596;
BA_ "SigType" SG_ 2566844711 CruiseCtrlEnableSwitch 1.7E-308;
BA_ "SPN" SG_ 2566844711 BrakeSwitch 597;
BA_ "SigType" SG_ 2566844711 BrakeSwitch 1.7E-308;
BA_ "SPN" SG_ 2566844711 ClutchSwitch 598;
BA_ "SigType" SG_ 2566844711 ClutchSwitch 1.7E-308;
BA_ "SPN" SG_ 2566844711 CruiseCtrlSetSwitch 599;
BA_ "SigType" SG_ 2566844711 CruiseCtrlSetSwitch 1.7E-308;
BA_ "SPN" SG_ 2566844711 CruiseCtrlCoastSwitch 600;
BA_ "SigType" SG_ 2566844711 CruiseCtrlCoastSwitch 1.7E-308;
BA_ "SPN" SG_ 2566844711 CruiseCtrlResumeSwitch 601;
BA_ "SigType" SG_ 2566844711 CruiseCtrlResumeSwitch 1.7E-308;
BA_ "SPN" SG_ 2566844711 CruiseCtrlAccelerateSwitch 602;
BA_ "SigType" SG_ 2566844711 CruiseCtrlAccelerateSwitch 1.7E-308;
BA_ "SPN" SG_ 2566844711 CruiseCtrlSetSpeed 86;
BA_ "SigType" SG_ 2566844711 CruiseCtrlSetSpeed 1.7E-308;
BA_ "SPN" SG_ 2566844711 pOdometerDriveBit 523994;
BA_ "SigType" SG_ 2566844711 pOdometerDriveBit 1.7E-308;
BA_ "SPN" SG_ 2566844711 CruiseCtrlPauseSw 1633;
BA_ "SigType" SG_ 2566844711 CruiseCtrlPauseSw 1.7E-308;
BA_ "SPN" SG_ 2566844711 pCCChecksum 524079;
BA_ "SigType" SG_ 2566844711 pCCChecksum 1.7E-308;
BA_ "SPN" SG_ 2566844711 pCruiseEnableStatus 524108;
BA_ "SigType" SG_ 2566844711 pCruiseEnableStatus 1.7E-308;
BA_ "SPN" SG_ 2566841895 Minutes 960;
BA_ "SigType" SG_ 2566841895 Minutes 1.7E-308;
BA_ "SPN" SG_ 2566841895 Hours 961;
BA_ "SigType" SG_ 2566841895 Hours 1.7E-308;
BA_ "SPN" SG_ 2566841895 LocalHourOffset 1602;
BA_ "SigType" SG_ 2566841895 LocalHourOffset 1.7E-308;
BA_ "SPN" SG_ 2566841895 Seconds 959;
BA_ "SigType" SG_ 2566841895 Seconds 1.7E-308;
BA_ "SPN" SG_ 2566841895 Day 962;
BA_ "SigType" SG_ 2566841895 Day 1.7E-308;
BA_ "SPN" SG_ 2566841895 LocalMinuteOffset 1601;
BA_ "SigType" SG_ 2566841895 LocalMinuteOffset 1.7E-308;
BA_ "SPN" SG_ 2566841895 Month 963;
BA_ "SigType" SG_ 2566841895 Month 1.7E-308;
BA_ "SPN" SG_ 2566841895 Year 964;
BA_ "SigType" SG_ 2566841895 Year 1.7E-308;
BA_ "SPN" SG_ 2565866791 TransmissionSelectedGear 524;
BA_ "SigType" SG_ 2565866791 TransmissionSelectedGear 1.7E-308;
BA_ "SPN" SG_ 2565866791 TransmissionActualGearRatio 526;
BA_ "SigType" SG_ 2565866791 TransmissionActualGearRatio 1.7E-308;
BA_ "SPN" SG_ 2565866791 TransmissionCurrentGear 523;
BA_ "SigType" SG_ 2565866791 TransmissionCurrentGear 1.7E-308;
BA_ "SPN" SG_ 2565866791 TransmissionRqstedRange 162;
BA_ "SigType" SG_ 2565866791 TransmissionRqstedRange 1.7E-308;
BA_ "SPN" SG_ 2565866791 TransmissionCurrentRange 163;
BA_ "SigType" SG_ 2565866791 TransmissionCurrentRange 1.7E-308;
BA_ "SPN" SG_ 2565799463 IdentityNumber 2837;
BA_ "SigType" SG_ 2565799463 IdentityNumber 1.7E-308;
BA_ "SPN" SG_ 2565799463 ManufacturerCode 2838;
BA_ "SigType" SG_ 2565799463 ManufacturerCode 1.7E-308;
BA_ "SPN" SG_ 2565799463 ECUInstance 2840;
BA_ "SigType" SG_ 2565799463 ECUInstance 1.7E-308;
BA_ "SPN" SG_ 2565799463 FunctionInstance 2839;
BA_ "SigType" SG_ 2565799463 FunctionInstance 1.7E-308;
BA_ "SPN" SG_ 2565799463 Function 2841;
BA_ "SigType" SG_ 2565799463 Function 1.7E-308;
BA_ "SPN" SG_ 2565799463 VehicleSystem 2842;
BA_ "SigType" SG_ 2565799463 VehicleSystem 1.7E-308;
BA_ "SPN" SG_ 2565799463 VehicleSystemInstance 2843;
BA_ "SigType" SG_ 2565799463 VehicleSystemInstance 1.7E-308;
BA_ "SPN" SG_ 2565799463 IndustryGroup 2846;
BA_ "SigType" SG_ 2565799463 IndustryGroup 1.7E-308;
BA_ "SPN" SG_ 2565799463 ArbitraryAddressCapable 2844;
BA_ "SigType" SG_ 2565799463 ArbitraryAddressCapable 1.7E-308;
BA_ "SPN" SG_ 2631794215 EncryptionIndicatorStates 1199;
BA_ "SigType" SG_ 2631794215 EncryptionIndicatorStates 1.7E-308;
BA_ "SPN" SG_ 2631794215 AntiTheftDesiredExitModeStates 1200;
BA_ "SigType" SG_ 2631794215 AntiTheftDesiredExitModeStates 1.7E-308;
BA_ "SPN" SG_ 2631794215 AntiTheftCommandStates 1201;
BA_ "SigType" SG_ 2631794215 AntiTheftCommandStates 1.7E-308;
BA_ "SPN" SG_ 2631794215 AntiTheftPasswordRepresentation 1202;
BA_ "SigType" SG_ 2631794215 AntiTheftPasswordRepresentation 1.7E-308;
BA_ "SPN" SG_ 2550791719 StaticRollAngle 5582;
BA_ "SigType" SG_ 2550791719 StaticRollAngle 1.7E-308;
BA_ "SPN" SG_ 2550791719 StaticRollAngleStatus 5582;
BA_ "SigType" SG_ 2550791719 StaticRollAngleStatus 1.7E-308;
BA_ "SPN" SG_ 2566842495 CompassBearing 165;
BA_ "SigType" SG_ 2566842495 CompassBearing 1.7E-308;
BA_ "SPN" SG_ 2365473024 LowBeamHeadlightCommand 2349;
BA_ "SPN" SG_ 2365473024 HighBeamHeadlightCommand 2347;
BA_ "SPN" SG_ 2365473024 LeftTurnSigLightsCommand 2367;
BA_ "SigType" SG_ 2365473024 LeftTurnSigLightsCommand 1.7E-308;
BA_ "SPN" SG_ 2365473024 RightTurnSigLightsCommand 2369;
BA_ "SigType" SG_ 2365473024 RightTurnSigLightsCommand 1.7E-308;
BA_ "SPN" SG_ 2631859735 TripGroup1 988;
BA_ "SigType" SG_ 2631859735 TripGroup1 1.7E-308;
BA_ "SPN" SG_ 2631859735 TripGroup2 989;
BA_ "SigType" SG_ 2631859735 TripGroup2 1.7E-308;
BA_ "SPN" SG_ 2631859735 ServiceComponentIdentification 1584;
BA_ "SigType" SG_ 2631859735 ServiceComponentIdentification 1.7E-308;
BA_ "SPN" SG_ 2631859735 EngineBuildHoursReset 1211;
BA_ "SigType" SG_ 2631859735 EngineBuildHoursReset 1.7E-308;
BA_ "SPN" SG_ 2564161047 AdjustDay 1607;
BA_ "SigType" SG_ 2564161047 AdjustDay 1.7E-308;
BA_ "SPN" SG_ 2564161047 AdjustHours 1605;
BA_ "SigType" SG_ 2564161047 AdjustHours 1.7E-308;
BA_ "SPN" SG_ 2564161047 AdjustLocalHourOffset 1610;
BA_ "SigType" SG_ 2564161047 AdjustLocalHourOffset 1.7E-308;
BA_ "SPN" SG_ 2564161047 AdjustMinutes 1604;
BA_ "SigType" SG_ 2564161047 AdjustMinutes 1.7E-308;
BA_ "SPN" SG_ 2564161047 AdjustMonth 1606;
BA_ "SigType" SG_ 2564161047 AdjustMonth 1.7E-308;
BA_ "SPN" SG_ 2564161047 AdjustSeconds 1603;
BA_ "SigType" SG_ 2564161047 AdjustSeconds 1.7E-308;
BA_ "SPN" SG_ 2564161047 AdjustYear 1608;
BA_ "SigType" SG_ 2564161047 AdjustYear 1.7E-308;
BA_ "SPN" SG_ 2564161047 AdjustLocalMinuteOffset 1609;
BA_ "SigType" SG_ 2564161047 AdjustLocalMinuteOffset 1.7E-308;
BA_ "SPN" SG_ 2550201867 EngOverrideCtlMode 695;
BA_ "SigType" SG_ 2550201867 EngOverrideCtlMode 1.7E-308;
BA_ "SPN" SG_ 2550201867 EngReqSpeedControlCond 696;
BA_ "SigType" SG_ 2550201867 EngReqSpeedControlCond 1.7E-308;
BA_ "SPN" SG_ 2550201867 OverrideCtlModePriority 897;
BA_ "SigType" SG_ 2550201867 OverrideCtlModePriority 1.7E-308;
BA_ "SPN" SG_ 2550201867 EngReqSpeedLimit 898;
BA_ "SigType" SG_ 2550201867 EngReqSpeedLimit 1.7E-308;
BA_ "SPN" SG_ 2550201867 EngReqTorqueLimit 518;
BA_ "SigType" SG_ 2550201867 EngReqTorqueLimit 1.7E-308;
BA_ "SPN" SG_ 2550201867 TSC1_TransmissionRate 3349;
BA_ "SigType" SG_ 2550201867 TSC1_TransmissionRate 1.7E-308;
BA_ "SPN" SG_ 2550201867 EngineRequestedTorque_HiRes 4191;
BA_ "SigType" SG_ 2550201867 EngineRequestedTorque_HiRes 1.7E-308;
BA_ "SPN" SG_ 2550201867 MessageCounter 4206;
BA_ "SigType" SG_ 2550201867 MessageCounter 1.7E-308;
BA_ "SPN" SG_ 2550201867 MessageChecksum 4207;
BA_ "SigType" SG_ 2550201867 MessageChecksum 1.7E-308;
BA_ "SPN" SG_ 2566878847 pHeadset2ConnectionStatus 524131;
BA_ "SPN" SG_ 2566878847 pHeadset1ConnectionStatus 524130;
BA_ "SPN" SG_ 2566878847 pDevice2CellSigStrength 524127;
BA_ "SPN" SG_ 2566878847 pDevice2BTConnectStatus 524129;
BA_ "SPN" SG_ 2566878847 pDevice2BattStrength 524128;
BA_ "SPN" SG_ 2566878847 pDevice1CellSigStrength 524124;
BA_ "SPN" SG_ 2566878847 pDevice1BTConnectStatus 524126;
BA_ "SPN" SG_ 2566878847 pDevice1BattStrength 524125;
BA_ "SPN" SG_ 2566877505 pVolumeUnitsSelected 524267;
BA_ "SPN" SG_ 2566877505 pTimeUnitsSelected 524268;
BA_ "SPN" SG_ 2566877505 pTemperatureUnitsSelected 524266;
BA_ "SPN" SG_ 2566877505 pPressureUnitsSelected 524269;
BA_ "SPN" SG_ 2566877505 pHighResTrip2Distance 524264;
BA_ "SPN" SG_ 2566877505 pDistanceUnitsSelected 524265;
BA_ "SPN" SG_ 2566877505 pTPMSLearningStatus 524104;
BA_ "SigType" SG_ 2566877505 pTPMSLearningStatus 1.7E-308;
BA_ "SPN" SG_ 2566877505 pDisplayStatus 524105;
BA_ "SigType" SG_ 2566877505 pDisplayStatus 1.7E-308;
BA_ "SPN" SG_ 2566877311 pHighlightRow 524119;
BA_ "SPN" SG_ 2566877311 pScreenAreaMode 524132;
BA_ "SPN" SG_ 2566877311 pRadioInputDevice 524099;
BA_ "SigType" SG_ 2566877311 pRadioInputDevice 1.7E-308;
BA_ "SPN" SG_ 2566877311 pRadioInputValue 524100;
BA_ "SigType" SG_ 2566877311 pRadioInputValue 1.7E-308;
BA_ "SPN" SG_ 2566877311 pRadioScaling 524101;
BA_ "SigType" SG_ 2566877311 pRadioScaling 1.7E-308;
BA_ "SPN" SG_ 2566877311 pTextLineConfiguration 524102;
BA_ "SigType" SG_ 2566877311 pTextLineConfiguration 1.7E-308;
BA_ "SPN" SG_ 2566877311 pStereoStatus 524103;
BA_ "SigType" SG_ 2566877311 pStereoStatus 1.7E-308;
BA_ "SPN" SG_ 2566877311 pFirstRowConfiguration 524106;
BA_ "SigType" SG_ 2566877311 pFirstRowConfiguration 1.7E-308;
BA_ "SPN" SG_ 2566877311 pScreenAreaConfiguration 524107;
BA_ "SigType" SG_ 2566877311 pScreenAreaConfiguration 1.7E-308;
BA_ "SPN" SG_ 2432656449 pInfotainmentJoystick2 520364;
BA_ "SPN" SG_ 2432656449 pInfotainmentJoystick1 520363;
BA_ "SPN" SG_ 2432656449 pInfotainmentRemoteButton01 524031;
BA_ "SigType" SG_ 2432656449 pInfotainmentRemoteButton01 1.7E-308;
BA_ "SPN" SG_ 2432656449 pInfotainmentRemoteButton02 524030;
BA_ "SigType" SG_ 2432656449 pInfotainmentRemoteButton02 1.7E-308;
BA_ "SPN" SG_ 2432656449 pInfotainmentRemoteButton03 524029;
BA_ "SigType" SG_ 2432656449 pInfotainmentRemoteButton03 1.7E-308;
BA_ "SPN" SG_ 2432656449 pInfotainmentRemoteButton04 524028;
BA_ "SigType" SG_ 2432656449 pInfotainmentRemoteButton04 1.7E-308;
BA_ "SPN" SG_ 2432656449 pInfotainmentRemoteButton05 524027;
BA_ "SigType" SG_ 2432656449 pInfotainmentRemoteButton05 1.7E-308;
BA_ "SPN" SG_ 2432656449 pInfotainmentRemoteButton06 524026;
BA_ "SigType" SG_ 2432656449 pInfotainmentRemoteButton06 1.7E-308;
BA_ "SPN" SG_ 2432656449 pInfotainmentRemoteButton07 524025;
BA_ "SigType" SG_ 2432656449 pInfotainmentRemoteButton07 1.7E-308;
BA_ "SPN" SG_ 2432656449 pInfotainmentRemoteButton08 524024;
BA_ "SigType" SG_ 2432656449 pInfotainmentRemoteButton08 1.7E-308;
BA_ "SPN" SG_ 2432656449 pInfotainmentRemoteButton09 524023;
BA_ "SigType" SG_ 2432656449 pInfotainmentRemoteButton09 1.7E-308;
BA_ "SPN" SG_ 2432656449 pInfotainmentRemoteButton10 524022;
BA_ "SigType" SG_ 2432656449 pInfotainmentRemoteButton10 1.7E-308;
BA_ "SPN" SG_ 2432656449 pInfotainmentRemoteButton11 524021;
BA_ "SigType" SG_ 2432656449 pInfotainmentRemoteButton11 1.7E-308;
BA_ "SPN" SG_ 2432656449 pInfotainmentRemoteButton12 524020;
BA_ "SigType" SG_ 2432656449 pInfotainmentRemoteButton12 1.7E-308;
BA_ "SPN" SG_ 2566874899 pSensedInputSteeringTorque 524002;
BA_ "SigType" SG_ 2566874899 pSensedInputSteeringTorque 1.7E-308;
BA_ "SPN" SG_ 2566874899 pSensedOutputSteeringTorque 524003;
BA_ "SigType" SG_ 2566874899 pSensedOutputSteeringTorque 1.7E-308;
BA_ "SPN" SG_ 2566874899 pGeneratedCurrentCommand 524004;
BA_ "SigType" SG_ 2566874899 pGeneratedCurrentCommand 1.7E-308;
BA_ "SPN" SG_ 2566874899 pVTemp 524005;
BA_ "SigType" SG_ 2566874899 pVTemp 1.7E-308;
BA_ "SPN" SG_ 2566846219 NetBatteryCurrent 114;
BA_ "SigType" SG_ 2566846219 NetBatteryCurrent 1.7E-308;
BA_ "SPN" SG_ 2566846219 AlternatorCurrent 115;
BA_ "SigType" SG_ 2566846219 AlternatorCurrent 1.7E-308;
BA_ "SPN" SG_ 2566846219 ChargingSystemPotential 167;
BA_ "SigType" SG_ 2566846219 ChargingSystemPotential 1.7E-308;
BA_ "SPN" SG_ 2566846219 BatteryPotential 168;
BA_ "SigType" SG_ 2566846219 BatteryPotential 1.7E-308;
BA_ "SPN" SG_ 2566846219 KeyswitchBatteryPotential 158;
BA_ "SigType" SG_ 2566846219 KeyswitchBatteryPotential 1.7E-308;
BA_ "SPN" SG_ 2566846227 NetBatteryCurrent 114;
BA_ "SigType" SG_ 2566846227 NetBatteryCurrent 1.7E-308;
BA_ "SPN" SG_ 2566846227 AlternatorCurrent 115;
BA_ "SigType" SG_ 2566846227 AlternatorCurrent 1.7E-308;
BA_ "SPN" SG_ 2566846227 ChargingSystemPotential 167;
BA_ "SigType" SG_ 2566846227 ChargingSystemPotential 1.7E-308;
BA_ "SPN" SG_ 2566846227 BatteryPotential 168;
BA_ "SigType" SG_ 2566846227 BatteryPotential 1.7E-308;
BA_ "SPN" SG_ 2566846227 KeyswitchBatteryPotential 158;
BA_ "SigType" SG_ 2566846227 KeyswitchBatteryPotential 1.7E-308;
BA_ "SPN" SG_ 2566844683 TwoSpeedAxleSwitch 69;
BA_ "SigType" SG_ 2566844683 TwoSpeedAxleSwitch 1.7E-308;
BA_ "SPN" SG_ 2566844683 ParkingBrakeSwitch 70;
BA_ "SigType" SG_ 2566844683 ParkingBrakeSwitch 1.7E-308;
BA_ "SPN" SG_ 2566844683 Wheel_BasedVehicleSpeed 84;
BA_ "SigType" SG_ 2566844683 Wheel_BasedVehicleSpeed 1.7E-308;
BA_ "SPN" SG_ 2566844683 CruiseCtrlActive 595;
BA_ "SigType" SG_ 2566844683 CruiseCtrlActive 1.7E-308;
BA_ "SPN" SG_ 2566844683 CruiseCtrlEnableSwitch 596;
BA_ "SigType" SG_ 2566844683 CruiseCtrlEnableSwitch 1.7E-308;
BA_ "SPN" SG_ 2566844683 BrakeSwitch 597;
BA_ "SigType" SG_ 2566844683 BrakeSwitch 1.7E-308;
BA_ "SPN" SG_ 2566844683 ClutchSwitch 598;
BA_ "SigType" SG_ 2566844683 ClutchSwitch 1.7E-308;
BA_ "SPN" SG_ 2566844683 CruiseCtrlSetSwitch 599;
BA_ "SigType" SG_ 2566844683 CruiseCtrlSetSwitch 1.7E-308;
BA_ "SPN" SG_ 2566844683 CruiseCtrlCoastSwitch 600;
BA_ "SigType" SG_ 2566844683 CruiseCtrlCoastSwitch 1.7E-308;
BA_ "SPN" SG_ 2566844683 CruiseCtrlResumeSwitch 601;
BA_ "SigType" SG_ 2566844683 CruiseCtrlResumeSwitch 1.7E-308;
BA_ "SPN" SG_ 2566844683 CruiseCtrlAccelerateSwitch 602;
BA_ "SigType" SG_ 2566844683 CruiseCtrlAccelerateSwitch 1.7E-308;
BA_ "SPN" SG_ 2566844683 CruiseCtrlSetSpeed 86;
BA_ "SigType" SG_ 2566844683 CruiseCtrlSetSpeed 1.7E-308;
BA_ "SPN" SG_ 2566844683 pOdometerDriveBit 523994;
BA_ "SigType" SG_ 2566844683 pOdometerDriveBit 1.7E-308;
BA_ "SPN" SG_ 2566844683 CruiseCtrlPauseSw 1633;
BA_ "SigType" SG_ 2566844683 CruiseCtrlPauseSw 1.7E-308;
BA_ "SPN" SG_ 2566844683 pCCChecksum 524079;
BA_ "SigType" SG_ 2566844683 pCCChecksum 1.7E-308;
BA_ "SPN" SG_ 2566844683 pCruiseEnableStatus 524108;
BA_ "SigType" SG_ 2566844683 pCruiseEnableStatus 1.7E-308;
BA_ "SPN" SG_ 2566844683 pCCMessageCounter 524080;
BA_ "SigType" SG_ 2566844683 pCCMessageCounter 1.7E-308;
BA_ "SPN" SG_ 2566844839 TwoSpeedAxleSwitch 69;
BA_ "SigType" SG_ 2566844839 TwoSpeedAxleSwitch 1.7E-308;
BA_ "SPN" SG_ 2566844839 ParkingBrakeSwitch 70;
BA_ "SigType" SG_ 2566844839 ParkingBrakeSwitch 1.7E-308;
BA_ "SPN" SG_ 2566844839 Wheel_BasedVehicleSpeed 84;
BA_ "SigType" SG_ 2566844839 Wheel_BasedVehicleSpeed 1.7E-308;
BA_ "SPN" SG_ 2566844839 CruiseCtrlActive 595;
BA_ "SigType" SG_ 2566844839 CruiseCtrlActive 1.7E-308;
BA_ "SPN" SG_ 2566844839 CruiseCtrlEnableSwitch 596;
BA_ "SigType" SG_ 2566844839 CruiseCtrlEnableSwitch 1.7E-308;
BA_ "SPN" SG_ 2566844839 BrakeSwitch 597;
BA_ "SigType" SG_ 2566844839 BrakeSwitch 1.7E-308;
BA_ "SPN" SG_ 2566844839 ClutchSwitch 598;
BA_ "SigType" SG_ 2566844839 ClutchSwitch 1.7E-308;
BA_ "SPN" SG_ 2566844839 CruiseCtrlSetSwitch 599;
BA_ "SigType" SG_ 2566844839 CruiseCtrlSetSwitch 1.7E-308;
BA_ "SPN" SG_ 2566844839 CruiseCtrlCoastSwitch 600;
BA_ "SigType" SG_ 2566844839 CruiseCtrlCoastSwitch 1.7E-308;
BA_ "SPN" SG_ 2566844839 CruiseCtrlResumeSwitch 601;
BA_ "SigType" SG_ 2566844839 CruiseCtrlResumeSwitch 1.7E-308;
BA_ "SPN" SG_ 2566844839 CruiseCtrlAccelerateSwitch 602;
BA_ "SigType" SG_ 2566844839 CruiseCtrlAccelerateSwitch 1.7E-308;
BA_ "SPN" SG_ 2566844839 CruiseCtrlSetSpeed 86;
BA_ "SigType" SG_ 2566844839 CruiseCtrlSetSpeed 1.7E-308;
BA_ "SPN" SG_ 2566844839 pOdometerDriveBit 523994;
BA_ "SigType" SG_ 2566844839 pOdometerDriveBit 1.7E-308;
BA_ "SPN" SG_ 2566844839 CruiseCtrlPauseSw 1633;
BA_ "SigType" SG_ 2566844839 CruiseCtrlPauseSw 1.7E-308;
BA_ "SPN" SG_ 2566844839 pCCChecksum 524079;
BA_ "SigType" SG_ 2566844839 pCCChecksum 1.7E-308;
BA_ "SPN" SG_ 2566844839 pCruiseEnableStatus 524108;
BA_ "SigType" SG_ 2566844839 pCruiseEnableStatus 1.7E-308;
BA_ "GenSigStartValue" SG_ 2566844839 pCruiseCntrlCounter 7;
BA_ "SPN" SG_ 2566844839 pCruiseCntrlCounter 524080;
BA_ "SigType" SG_ 2566834855 DTC5 7;
BA_ "SigType" SG_ 2566834855 DTC4 7;
BA_ "SigType" SG_ 2566834855 DTC3 7;
BA_ "SigType" SG_ 2566834855 DTC2 7;
BA_ "SigType" SG_ 2566834855 DTC1 7;
BA_ "SPN" SG_ 2566834855 DM_FlashRedStopLamp 3039;
BA_ "SPN" SG_ 2566834855 DM_FlashProtectLamp 3041;
BA_ "SPN" SG_ 2566834855 DM_FlashMalfuncIndicatorLamp 3038;
BA_ "SPN" SG_ 2566834855 DM_FlashAmberWarningLamp 3040;
BA_ "SPN" SG_ 2566834855 DM_ProtectLampStatus 987;
BA_ "SigType" SG_ 2566834855 DM_ProtectLampStatus 1.7E-308;
BA_ "SPN" SG_ 2566834855 DM_RedStopLampState 623;
BA_ "SigType" SG_ 2566834855 DM_RedStopLampState 1.7E-308;
BA_ "SPN" SG_ 2566834855 DM_AmberWrningLmpStatus 624;
BA_ "SigType" SG_ 2566834855 DM_AmberWrningLmpStatus 1.7E-308;
BA_ "SPN" SG_ 2566834855 DM_MalfuncnIndicatorLampStatus 1213;
BA_ "SigType" SG_ 2566834855 DM_MalfuncnIndicatorLampStatus 1.7E-308;
BA_ "SigType" SG_ 2566834815 DTC5 7;
BA_ "SigType" SG_ 2566834815 DTC4 7;
BA_ "SigType" SG_ 2566834815 DTC3 7;
BA_ "SigType" SG_ 2566834815 DTC2 7;
BA_ "SigType" SG_ 2566834815 DTC1 7;
BA_ "SPN" SG_ 2566834815 DM_FlashRedStopLamp 3039;
BA_ "SPN" SG_ 2566834815 DM_FlashProtectLamp 3041;
BA_ "SPN" SG_ 2566834815 DM_FlashMalfuncIndicatorLamp 3038;
BA_ "SPN" SG_ 2566834815 DM_FlashAmberWarningLamp 3040;
BA_ "SPN" SG_ 2566834815 DM_ProtectLampStatus 987;
BA_ "SigType" SG_ 2566834815 DM_ProtectLampStatus 1.7E-308;
BA_ "SPN" SG_ 2566834815 DM_RedStopLampState 623;
BA_ "SigType" SG_ 2566834815 DM_RedStopLampState 1.7E-308;
BA_ "SPN" SG_ 2566834815 DM_AmberWrningLmpStatus 624;
BA_ "SigType" SG_ 2566834815 DM_AmberWrningLmpStatus 1.7E-308;
BA_ "SPN" SG_ 2566834815 DM_MalfuncnIndicatorLampStatus 1213;
BA_ "SigType" SG_ 2566834815 DM_MalfuncnIndicatorLampStatus 1.7E-308;
BA_ "SigType" SG_ 2566834814 DTC5 7;
BA_ "SigType" SG_ 2566834814 DTC4 7;
BA_ "SigType" SG_ 2566834814 DTC3 7;
BA_ "SigType" SG_ 2566834814 DTC2 7;
BA_ "SigType" SG_ 2566834814 DTC1 7;
BA_ "SPN" SG_ 2566834814 DM_FlashRedStopLamp 3039;
BA_ "SPN" SG_ 2566834814 DM_FlashProtectLamp 3041;
BA_ "SPN" SG_ 2566834814 DM_FlashMalfuncIndicatorLamp 3038;
BA_ "SPN" SG_ 2566834814 DM_FlashAmberWarningLamp 3040;
BA_ "SPN" SG_ 2566834814 DM_ProtectLampStatus 987;
BA_ "SigType" SG_ 2566834814 DM_ProtectLampStatus 1.7E-308;
BA_ "SPN" SG_ 2566834814 DM_RedStopLampState 623;
BA_ "SigType" SG_ 2566834814 DM_RedStopLampState 1.7E-308;
BA_ "SPN" SG_ 2566834814 DM_AmberWrningLmpStatus 624;
BA_ "SigType" SG_ 2566834814 DM_AmberWrningLmpStatus 1.7E-308;
BA_ "SPN" SG_ 2566834814 DM_MalfuncnIndicatorLampStatus 1213;
BA_ "SigType" SG_ 2566834814 DM_MalfuncnIndicatorLampStatus 1.7E-308;
BA_ "SigType" SG_ 2566834812 DTC5 7;
BA_ "SigType" SG_ 2566834812 DTC4 7;
BA_ "SigType" SG_ 2566834812 DTC3 7;
BA_ "SigType" SG_ 2566834812 DTC2 7;
BA_ "SigType" SG_ 2566834812 DTC1 7;
BA_ "SPN" SG_ 2566834812 DM_FlashRedStopLamp 3039;
BA_ "SPN" SG_ 2566834812 DM_FlashProtectLamp 3041;
BA_ "SPN" SG_ 2566834812 DM_FlashMalfuncIndicatorLamp 3038;
BA_ "SPN" SG_ 2566834812 DM_FlashAmberWarningLamp 3040;
BA_ "SPN" SG_ 2566834812 DM_ProtectLampStatus 987;
BA_ "SigType" SG_ 2566834812 DM_ProtectLampStatus 1.7E-308;
BA_ "SPN" SG_ 2566834812 DM_RedStopLampState 623;
BA_ "SigType" SG_ 2566834812 DM_RedStopLampState 1.7E-308;
BA_ "SPN" SG_ 2566834812 DM_AmberWrningLmpStatus 624;
BA_ "SigType" SG_ 2566834812 DM_AmberWrningLmpStatus 1.7E-308;
BA_ "SPN" SG_ 2566834812 DM_MalfuncnIndicatorLampStatus 1213;
BA_ "SigType" SG_ 2566834812 DM_MalfuncnIndicatorLampStatus 1.7E-308;
BA_ "SigType" SG_ 2566834808 DTC5 7;
BA_ "SigType" SG_ 2566834808 DTC4 7;
BA_ "SigType" SG_ 2566834808 DTC3 7;
BA_ "SigType" SG_ 2566834808 DTC2 7;
BA_ "SigType" SG_ 2566834808 DTC1 7;
BA_ "SPN" SG_ 2566834808 DM_FlashRedStopLamp 3039;
BA_ "SPN" SG_ 2566834808 DM_FlashProtectLamp 3041;
BA_ "SPN" SG_ 2566834808 DM_FlashMalfuncIndicatorLamp 3038;
BA_ "SPN" SG_ 2566834808 DM_FlashAmberWarningLamp 3040;
BA_ "SPN" SG_ 2566834808 DM_ProtectLampStatus 987;
BA_ "SigType" SG_ 2566834808 DM_ProtectLampStatus 1.7E-308;
BA_ "SPN" SG_ 2566834808 DM_RedStopLampState 623;
BA_ "SigType" SG_ 2566834808 DM_RedStopLampState 1.7E-308;
BA_ "SPN" SG_ 2566834808 DM_AmberWrningLmpStatus 624;
BA_ "SigType" SG_ 2566834808 DM_AmberWrningLmpStatus 1.7E-308;
BA_ "SPN" SG_ 2566834808 DM_MalfuncnIndicatorLampStatus 1213;
BA_ "SigType" SG_ 2566834808 DM_MalfuncnIndicatorLampStatus 1.7E-308;
BA_ "SigType" SG_ 2566834937 DTC5 7;
BA_ "SigType" SG_ 2566834937 DTC4 7;
BA_ "SigType" SG_ 2566834937 DTC3 7;
BA_ "SigType" SG_ 2566834937 DTC2 7;
BA_ "SigType" SG_ 2566834937 DTC1 7;
BA_ "SPN" SG_ 2566834937 DM_FlashRedStopLamp 3039;
BA_ "SPN" SG_ 2566834937 DM_FlashProtectLamp 3041;
BA_ "SPN" SG_ 2566834937 DM_FlashMalfuncIndicatorLamp 3038;
BA_ "SPN" SG_ 2566834937 DM_FlashAmberWarningLamp 3040;
BA_ "SPN" SG_ 2566834937 DM_ProtectLampStatus 987;
BA_ "SigType" SG_ 2566834937 DM_ProtectLampStatus 1.7E-308;
BA_ "SPN" SG_ 2566834937 DM_RedStopLampState 623;
BA_ "SigType" SG_ 2566834937 DM_RedStopLampState 1.7E-308;
BA_ "SPN" SG_ 2566834937 DM_AmberWrningLmpStatus 624;
BA_ "SigType" SG_ 2566834937 DM_AmberWrningLmpStatus 1.7E-308;
BA_ "SPN" SG_ 2566834937 DM_MalfuncnIndicatorLampStatus 1213;
BA_ "SigType" SG_ 2566834937 DM_MalfuncnIndicatorLampStatus 1.7E-308;
BA_ "SigType" SG_ 2566834753 DTC5 7;
BA_ "SigType" SG_ 2566834753 DTC4 7;
BA_ "SigType" SG_ 2566834753 DTC3 7;
BA_ "SigType" SG_ 2566834753 DTC2 7;
BA_ "SigType" SG_ 2566834753 DTC1 7;
BA_ "SPN" SG_ 2566834753 DM_FlashRedStopLamp 3039;
BA_ "SPN" SG_ 2566834753 DM_FlashProtectLamp 3041;
BA_ "SPN" SG_ 2566834753 DM_FlashMalfuncIndicatorLamp 3038;
BA_ "SPN" SG_ 2566834753 DM_FlashAmberWarningLamp 3040;
BA_ "SPN" SG_ 2566834753 DM_ProtectLampStatus 987;
BA_ "SigType" SG_ 2566834753 DM_ProtectLampStatus 1.7E-308;
BA_ "SPN" SG_ 2566834753 DM_RedStopLampState 623;
BA_ "SigType" SG_ 2566834753 DM_RedStopLampState 1.7E-308;
BA_ "SPN" SG_ 2566834753 DM_AmberWrningLmpStatus 624;
BA_ "SigType" SG_ 2566834753 DM_AmberWrningLmpStatus 1.7E-308;
BA_ "SPN" SG_ 2566834753 DM_MalfuncnIndicatorLampStatus 1213;
BA_ "SigType" SG_ 2566834753 DM_MalfuncnIndicatorLampStatus 1.7E-308;
BA_ "SigType" SG_ 2566834717 DTC5 7;
BA_ "SigType" SG_ 2566834717 DTC4 7;
BA_ "SigType" SG_ 2566834717 DTC3 7;
BA_ "SigType" SG_ 2566834717 DTC2 7;
BA_ "SigType" SG_ 2566834717 DTC1 7;
BA_ "SPN" SG_ 2566834717 DM_FlashRedStopLamp 3039;
BA_ "SPN" SG_ 2566834717 DM_FlashProtectLamp 3041;
BA_ "SPN" SG_ 2566834717 DM_FlashMalfuncIndicatorLamp 3038;
BA_ "SPN" SG_ 2566834717 DM_FlashAmberWarningLamp 3040;
BA_ "SPN" SG_ 2566834717 DM_ProtectLampStatus 987;
BA_ "SigType" SG_ 2566834717 DM_ProtectLampStatus 1.7E-308;
BA_ "SPN" SG_ 2566834717 DM_RedStopLampState 623;
BA_ "SigType" SG_ 2566834717 DM_RedStopLampState 1.7E-308;
BA_ "SPN" SG_ 2566834717 DM_AmberWrningLmpStatus 624;
BA_ "SigType" SG_ 2566834717 DM_AmberWrningLmpStatus 1.7E-308;
BA_ "SPN" SG_ 2566834717 DM_MalfuncnIndicatorLampStatus 1213;
BA_ "SigType" SG_ 2566834717 DM_MalfuncnIndicatorLampStatus 1.7E-308;
BA_ "SigType" SG_ 2566834711 DTC5 7;
BA_ "SigType" SG_ 2566834711 DTC4 7;
BA_ "SigType" SG_ 2566834711 DTC3 7;
BA_ "SigType" SG_ 2566834711 DTC2 7;
BA_ "SigType" SG_ 2566834711 DTC1 7;
BA_ "SPN" SG_ 2566834711 DM_FlashRedStopLamp 3039;
BA_ "SPN" SG_ 2566834711 DM_FlashProtectLamp 3041;
BA_ "SPN" SG_ 2566834711 DM_FlashMalfuncIndicatorLamp 3038;
BA_ "SPN" SG_ 2566834711 DM_FlashAmberWarningLamp 3040;
BA_ "SPN" SG_ 2566834711 DM_ProtectLampStatus 987;
BA_ "SigType" SG_ 2566834711 DM_ProtectLampStatus 1.7E-308;
BA_ "SPN" SG_ 2566834711 DM_RedStopLampState 623;
BA_ "SigType" SG_ 2566834711 DM_RedStopLampState 1.7E-308;
BA_ "SPN" SG_ 2566834711 DM_AmberWrningLmpStatus 624;
BA_ "SigType" SG_ 2566834711 DM_AmberWrningLmpStatus 1.7E-308;
BA_ "SPN" SG_ 2566834711 DM_MalfuncnIndicatorLampStatus 1213;
BA_ "SigType" SG_ 2566834711 DM_MalfuncnIndicatorLampStatus 1.7E-308;
BA_ "SigType" SG_ 2566834707 DTC5 7;
BA_ "SigType" SG_ 2566834707 DTC4 7;
BA_ "SigType" SG_ 2566834707 DTC3 7;
BA_ "SigType" SG_ 2566834707 DTC2 7;
BA_ "SigType" SG_ 2566834707 DTC1 7;
BA_ "SPN" SG_ 2566834707 DM_FlashRedStopLamp 3039;
BA_ "SPN" SG_ 2566834707 DM_FlashProtectLamp 3041;
BA_ "SPN" SG_ 2566834707 DM_FlashMalfuncIndicatorLamp 3038;
BA_ "SPN" SG_ 2566834707 DM_FlashAmberWarningLamp 3040;
BA_ "SPN" SG_ 2566834707 DM_ProtectLampStatus 987;
BA_ "SigType" SG_ 2566834707 DM_ProtectLampStatus 1.7E-308;
BA_ "SPN" SG_ 2566834707 DM_RedStopLampState 623;
BA_ "SigType" SG_ 2566834707 DM_RedStopLampState 1.7E-308;
BA_ "SPN" SG_ 2566834707 DM_AmberWrningLmpStatus 624;
BA_ "SigType" SG_ 2566834707 DM_AmberWrningLmpStatus 1.7E-308;
BA_ "SPN" SG_ 2566834707 DM_MalfuncnIndicatorLampStatus 1213;
BA_ "SigType" SG_ 2566834707 DM_MalfuncnIndicatorLampStatus 1.7E-308;
BA_ "SigType" SG_ 2566834699 DTC5 7;
BA_ "SigType" SG_ 2566834699 DTC4 7;
BA_ "SigType" SG_ 2566834699 DTC3 7;
BA_ "SigType" SG_ 2566834699 DTC2 7;
BA_ "SigType" SG_ 2566834699 DTC1 7;
BA_ "SPN" SG_ 2566834699 DM_FlashRedStopLamp 3039;
BA_ "SPN" SG_ 2566834699 DM_FlashProtectLamp 3041;
BA_ "SPN" SG_ 2566834699 DM_FlashMalfuncIndicatorLamp 3038;
BA_ "SPN" SG_ 2566834699 DM_FlashAmberWarningLamp 3040;
BA_ "SPN" SG_ 2566834699 DM_ProtectLampStatus 987;
BA_ "SigType" SG_ 2566834699 DM_ProtectLampStatus 1.7E-308;
BA_ "SPN" SG_ 2566834699 DM_RedStopLampState 623;
BA_ "SigType" SG_ 2566834699 DM_RedStopLampState 1.7E-308;
BA_ "SPN" SG_ 2566834699 DM_AmberWrningLmpStatus 624;
BA_ "SigType" SG_ 2566834699 DM_AmberWrningLmpStatus 1.7E-308;
BA_ "SPN" SG_ 2566834699 DM_MalfuncnIndicatorLampStatus 1213;
BA_ "SigType" SG_ 2566834699 DM_MalfuncnIndicatorLampStatus 1.7E-308;
BA_ "SPN" SG_ 2566831883 FrontAxleSpeed 904;
BA_ "SigType" SG_ 2566831883 FrontAxleSpeed 1.7E-308;
BA_ "SPN" SG_ 2566831883 RelSpeedFrontAxleLeftWheel 905;
BA_ "SigType" SG_ 2566831883 RelSpeedFrontAxleLeftWheel 1.7E-308;
BA_ "SPN" SG_ 2566831883 RelSpeedFrontAxleRightWheel 906;
BA_ "SigType" SG_ 2566831883 RelSpeedFrontAxleRightWheel 1.7E-308;
BA_ "SPN" SG_ 2566831883 RelSpeedRearAxle_1LeftWheel 907;
BA_ "SigType" SG_ 2566831883 RelSpeedRearAxle_1LeftWheel 1.7E-308;
BA_ "SPN" SG_ 2566831883 RelSpeedRearAxle_1RightWheel 908;
BA_ "SigType" SG_ 2566831883 RelSpeedRearAxle_1RightWheel 1.7E-308;
BA_ "SPN" SG_ 2566831883 RelSpeedRearAxle_2LeftWheel 909;
BA_ "SigType" SG_ 2566831883 RelSpeedRearAxle_2LeftWheel 1.7E-308;
BA_ "SPN" SG_ 2566831883 RelSpeedRearAxle_2RightWheel 910;
BA_ "SigType" SG_ 2566831883 RelSpeedRearAxle_2RightWheel 1.7E-308;
BA_ "SPN" SG_ 2566819840 EnginePeakTorque1 1248;
BA_ "SPN" SG_ 2566803211 VDCInfoSignal 1813;
BA_ "SigType" SG_ 2566803211 VDCInfoSignal 1.7E-308;
BA_ "SPN" SG_ 2566803211 VDCFullyOperational 1814;
BA_ "SigType" SG_ 2566803211 VDCFullyOperational 1.7E-308;
BA_ "SPN" SG_ 2566803211 VDCBrakeLightRequest 1815;
BA_ "SigType" SG_ 2566803211 VDCBrakeLightRequest 1.7E-308;
BA_ "SPN" SG_ 2566803211 ROPEngineControlActive 1816;
BA_ "SigType" SG_ 2566803211 ROPEngineControlActive 1.7E-308;
BA_ "SPN" SG_ 2566803211 ROPBrakeControlActive 1818;
BA_ "SigType" SG_ 2566803211 ROPBrakeControlActive 1.7E-308;
BA_ "SPN" SG_ 2566803211 YCEngineControlactive 1817;
BA_ "SigType" SG_ 2566803211 YCEngineControlactive 1.7E-308;
BA_ "SPN" SG_ 2566803211 YCBrakeControlActive 1819;
BA_ "SigType" SG_ 2566803211 YCBrakeControlActive 1.7E-308;
BA_ "SPN" SG_ 2565867787 SteeringWheelAngle 1807;
BA_ "SigType" SG_ 2565867787 SteeringWheelAngle 1.7E-308;
BA_ "SPN" SG_ 2565867787 SteeringWheelTurnCounter 1811;
BA_ "SigType" SG_ 2565867787 SteeringWheelTurnCounter 1.7E-308;
BA_ "SPN" SG_ 2565867787 SteeringWheelAngleSensorType 1812;
BA_ "SigType" SG_ 2565867787 SteeringWheelAngleSensorType 1.7E-308;
BA_ "SPN" SG_ 2565867787 YawRate 1808;
BA_ "SigType" SG_ 2565867787 YawRate 1.7E-308;
BA_ "SPN" SG_ 2565867787 LateralAcceleration 1809;
BA_ "SigType" SG_ 2565867787 LateralAcceleration 1.7E-308;
BA_ "SPN" SG_ 2565867787 LongitudalAcceleration 1810;
BA_ "SigType" SG_ 2565867787 LongitudalAcceleration 1.7E-308;
BA_ "SPN" SG_ 2565866240 AccelPedalPosition1 91;
BA_ "SigType" SG_ 2565866240 AccelPedalPosition1 1.7E-308;
BA_ "SPN" SG_ 2565865739 ABSActive 563;
BA_ "SigType" SG_ 2565865739 ABSActive 1.7E-308;
BA_ "SPN" SG_ 2565865739 ASREngineCtrlActive 561;
BA_ "SigType" SG_ 2565865739 ASREngineCtrlActive 1.7E-308;
BA_ "SPN" SG_ 2565865739 ASRBrakeCtrlActive 562;
BA_ "SigType" SG_ 2565865739 ASRBrakeCtrlActive 1.7E-308;
BA_ "SPN" SG_ 2565865739 BrakePedalPosition 521;
BA_ "SigType" SG_ 2565865739 BrakePedalPosition 1.7E-308;
BA_ "SPN" SG_ 2565865739 ABSOffroadSwitch 575;
BA_ "SigType" SG_ 2565865739 ABSOffroadSwitch 1.7E-308;
BA_ "SPN" SG_ 2565865739 ASROffroadSwitch 576;
BA_ "SigType" SG_ 2565865739 ASROffroadSwitch 1.7E-308;
BA_ "SPN" SG_ 2565865739 ASRHillHolderSwitch 577;
BA_ "SigType" SG_ 2565865739 ASRHillHolderSwitch 1.7E-308;
BA_ "SPN" SG_ 2565865739 EBSBrakeSwitch 1121;
BA_ "SigType" SG_ 2565865739 EBSBrakeSwitch 1.7E-308;
BA_ "SigType" SG_ 2565865739 DL17_TractionCtrlOverrideSwitch 1.7E-308;
BA_ "SPN" SG_ 2565865739 AcceleratorInterlockSwitch 972;
BA_ "SigType" SG_ 2565865739 AcceleratorInterlockSwitch 1.7E-308;
BA_ "SPN" SG_ 2565865739 EngineDerateSwitch 971;
BA_ "SigType" SG_ 2565865739 EngineDerateSwitch 1.7E-308;
BA_ "SPN" SG_ 2565865739 AuxEngineShutdownSwitch 970;
BA_ "SigType" SG_ 2565865739 AuxEngineShutdownSwitch 1.7E-308;
BA_ "SPN" SG_ 2565865739 RemoteAcceleratorSwitch 969;
BA_ "SigType" SG_ 2565865739 RemoteAcceleratorSwitch 1.7E-308;
BA_ "SPN" SG_ 2565865739 EngineRetarderSelection 973;
BA_ "SigType" SG_ 2565865739 EngineRetarderSelection 1.7E-308;
BA_ "SPN" SG_ 2565865739 ABSFullyOperational 1243;
BA_ "SigType" SG_ 2565865739 ABSFullyOperational 1.7E-308;
BA_ "SPN" SG_ 2565865739 EBSRedWarningState 1439;
BA_ "SigType" SG_ 2565865739 EBSRedWarningState 1.7E-308;
BA_ "SPN" SG_ 2565865739 ABSEBSAmberWarningState 1438;
BA_ "SigType" SG_ 2565865739 ABSEBSAmberWarningState 1.7E-308;
BA_ "SPN" SG_ 2565865739 SourceAddress 1481;
BA_ "SigType" SG_ 2565865739 SourceAddress 1.7E-308;
BA_ "SPN" SG_ 2565865739 ATC_ASR_InfoSig 1793;
BA_ "SigType" SG_ 2565865739 ATC_ASR_InfoSig 1.7E-308;
BA_ "SPN" SG_ 2563833367 IlluminationBrightnessPercent 1487;
BA_ "SigType" SG_ 2563833367 IlluminationBrightnessPercent 1.7E-308;
BA_ "SPN" SG_ 2563833367 SwitchBacklightIlluminPercent 5532;
BA_ "SigType" SG_ 2563833367 SwitchBacklightIlluminPercent 1.7E-308;
BA_ "SPN" SG_ 2565799591 IdentityNumber 2837;
BA_ "SigType" SG_ 2565799591 IdentityNumber 1.7E-308;
BA_ "SPN" SG_ 2565799591 ManufacturerCode 2838;
BA_ "SigType" SG_ 2565799591 ManufacturerCode 1.7E-308;
BA_ "SPN" SG_ 2565799591 ECUInstance 2840;
BA_ "SigType" SG_ 2565799591 ECUInstance 1.7E-308;
BA_ "SPN" SG_ 2565799591 FunctionInstance 2839;
BA_ "SigType" SG_ 2565799591 FunctionInstance 1.7E-308;
BA_ "SPN" SG_ 2565799591 Function 2841;
BA_ "SigType" SG_ 2565799591 Function 1.7E-308;
BA_ "SPN" SG_ 2565799591 VehicleSystem 2842;
BA_ "SigType" SG_ 2565799591 VehicleSystem 1.7E-308;
BA_ "SPN" SG_ 2565799591 VehicleSystemInstance 2843;
BA_ "SigType" SG_ 2565799591 VehicleSystemInstance 1.7E-308;
BA_ "SPN" SG_ 2565799591 IndustryGroup 2846;
BA_ "SigType" SG_ 2565799591 IndustryGroup 1.7E-308;
BA_ "SPN" SG_ 2565799591 ArbitraryAddressCapable 2844;
BA_ "SigType" SG_ 2565799591 ArbitraryAddressCapable 1.7E-308;
BA_ "SPN" SG_ 2565799551 IdentityNumber 2837;
BA_ "SigType" SG_ 2565799551 IdentityNumber 1.7E-308;
BA_ "SPN" SG_ 2565799551 ManufacturerCode 2838;
BA_ "SigType" SG_ 2565799551 ManufacturerCode 1.7E-308;
BA_ "SPN" SG_ 2565799551 ECUInstance 2840;
BA_ "SigType" SG_ 2565799551 ECUInstance 1.7E-308;
BA_ "SPN" SG_ 2565799551 FunctionInstance 2839;
BA_ "SigType" SG_ 2565799551 FunctionInstance 1.7E-308;
BA_ "SPN" SG_ 2565799551 Function 2841;
BA_ "SigType" SG_ 2565799551 Function 1.7E-308;
BA_ "SPN" SG_ 2565799551 VehicleSystem 2842;
BA_ "SigType" SG_ 2565799551 VehicleSystem 1.7E-308;
BA_ "SPN" SG_ 2565799551 VehicleSystemInstance 2843;
BA_ "SigType" SG_ 2565799551 VehicleSystemInstance 1.7E-308;
BA_ "SPN" SG_ 2565799551 IndustryGroup 2846;
BA_ "SigType" SG_ 2565799551 IndustryGroup 1.7E-308;
BA_ "SPN" SG_ 2565799551 ArbitraryAddressCapable 2844;
BA_ "SigType" SG_ 2565799551 ArbitraryAddressCapable 1.7E-308;
BA_ "SPN" SG_ 2565799550 IdentityNumber 2837;
BA_ "SigType" SG_ 2565799550 IdentityNumber 1.7E-308;
BA_ "SPN" SG_ 2565799550 ManufacturerCode 2838;
BA_ "SigType" SG_ 2565799550 ManufacturerCode 1.7E-308;
BA_ "SPN" SG_ 2565799550 ECUInstance 2840;
BA_ "SigType" SG_ 2565799550 ECUInstance 1.7E-308;
BA_ "SPN" SG_ 2565799550 FunctionInstance 2839;
BA_ "SigType" SG_ 2565799550 FunctionInstance 1.7E-308;
BA_ "SPN" SG_ 2565799550 Function 2841;
BA_ "SigType" SG_ 2565799550 Function 1.7E-308;
BA_ "SPN" SG_ 2565799550 VehicleSystem 2842;
BA_ "SigType" SG_ 2565799550 VehicleSystem 1.7E-308;
BA_ "SPN" SG_ 2565799550 VehicleSystemInstance 2843;
BA_ "SigType" SG_ 2565799550 VehicleSystemInstance 1.7E-308;
BA_ "SPN" SG_ 2565799550 IndustryGroup 2846;
BA_ "SigType" SG_ 2565799550 IndustryGroup 1.7E-308;
BA_ "SPN" SG_ 2565799550 ArbitraryAddressCapable 2844;
BA_ "SigType" SG_ 2565799550 ArbitraryAddressCapable 1.7E-308;
VAL_ 2566877463 pVolumeUnitsSelected 7 "Not Available" 6 "Error" 5 "Reserved" 4 "Reserved" 3 "Reserved" 2 "Imperial Gallons" 1 "Liters" 0 "Gallons" ;
VAL_ 2566877463 pTimeUnitsSelected 3 "Not Available" 2 "Error" 1 "24 Hour" 0 "12 Hour" ;
VAL_ 2566877463 pTemperatureUnitsSelected 3 "Not Avaialable" 2 "Error" 1 "Celsius" 0 "Farenheit" ;
VAL_ 2566877463 pPressureUnitsSelected 3 "Not Available" 2 "Error" 1 "Kilopascal (kPa)" 0 "Pounds Per Square Inch (PSI)" ;
VAL_ 2566877463 pDistanceUnitsSelected 3 "Not Available" 2 "Error" 1 "Kilometers" 0 "Miles" ;
VAL_ 2566877463 pTPMSLearningStatus 0 "Not Started" 1 "Request to start" 2 "Learning Left Front" 3 "Learning Right Front" 4 "Learning Left Rear" 5 "Learning Right Rear" 6 "Learning successfully completed" 13 "Request to end learning" 14 "Error - Failed Learning" 15 "Not Available" ;
VAL_ 2566877463 pDisplayStatus 0 "Info cant overide to full screen" 1 "User requested full screen" 2 "Info can overide to full screen" 14 "Info data is not shown" 15 "Not Available" ;
VAL_ 2566876711 pEngineOilPressureStatus 0 "Not OK; Pressure is too low" 1 "OK; Pressure is above minimum" 2 "Error" 3 "Not Available" ;
VAL_ 2566876711 pHydraulicOilPressureStatus 0 "Not OK; Pressure too low" 1 "OK; Pressure above minimum" 2 "Error" 3 "Not Available" ;
VAL_ 2566876711 pHydraulicOilTempStatus 0 "Not OK; Temp too high" 1 "OK; Temp is below max" 2 "Error" 3 "Not Available" ;
VAL_ 2633984551 pHeatedGripEnable 3 "Description for the value '3'" 2 "Error Indicator" 1 "Enabled (Installed)" 0 "Disabled (Not installed)" ;
VAL_ 2633984551 pSideStandStatus 3 "Not Available" 2 "Error Indicator" 1 "Side Stand Up" 0 "Side Stand Down" ;
VAL_ 2633984551 pTetherSwitchStatus 3 "Not Available" 2 "Error" 1 "Tether SW Open (disconnected)" 0 "Tether SW Closed (connected)" ;
VAL_ 2633984551 pLowFuelIndicatorStatus 3 "Not Available" 2 "Error" 1 "Low Fuel Indicator On" 0 "Low Fuel Indicator Off" ;
VAL_ 2633984551 pOperatorNotInOperatingStation 3 "Description for the value '3'" 2 "Error" 1 "Operator Not In OperatorStation" 0 "Operator In OperatorStation" ;
VAL_ 2633984551 pParkBrakeIndicatorStatus 7 "Not Available" 6 "Error Indicator" 5 "Available for future use" 4 "Available for future use" 3 "Park Brake Indicator 2 Hz flash" 2 "Park Brake Indicator 1 Hz flash" 1 "Park Brake Indicator On (Solid)" 0 "Park Brake Indicator Off" ;
VAL_ 2633984551 pADCRequested 3 "Not Available" 2 "Error" 1 "ADC Mode Requested" 0 "ADC Mode not Requested" ;
VAL_ 2633984551 pAWDModeRequested 3 "Not Available" 2 "Error" 1 "AWD Mode Requested" 0 "AWD Mode not Requested" ;
VAL_ 2633984551 pRWDModeRequested 3 "Not Available" 2 "Error" 1 "RWD Mode Requested" 0 "RWD Mode not Requested" ;
VAL_ 2633984551 pTurfModeRequested 3 "Not Available" 2 "Error" 1 "Turf Mode Requested" 0 "Turf Mode not Requested" ;
VAL_ 2633984551 pADCStatus 0 "ADC Actuator Not Engaged" 1 "ADC Actuator Engaged" 2 "Error" 3 "Not available" ;
VAL_ 2633984551 pTreadleNeutralStatus 0 "Treadle Neutral Not Engaged" 1 "Treadle Neutral Engaged" 2 "Error" 3 "Not Available" ;
VAL_ 2633984551 pTreadleReverseStatus 0 "Treadle Reverse Not Engaged" 1 "Treadle Reverse Engaged" 2 "Error" 3 "Not Available" ;
VAL_ 2633984551 pSecurityLightStatus 0 "Off" 1 "On (Solid)" 2 "Error (Flashing)" 3 "Not Available" ;
VAL_ 2633984551 pHighBeamIndicatorStatus 0 "Indicator Off" 1 "Indicator On" 2 "Error (Indicator Flashing)" 3 "Not Available" ;
VAL_ 2633984551 pCruiseControlSetStatus 0 "Cruise Not Set" 1 "Cruise Set" 2 "Error (Lamp Flashing)" 3 "Not Available" ;
VAL_ 2633984551 pSeatBeltIndicatorStatus 0 "Seat_Belt_Indicator_Off" 1 "Seat_Belt_Indicator_On_Solid" 2 "Seat_Belt_Indicator_1Hz" 3 "Seat_Belt_Indicator_2Hz" 4 "Future1" 5 "Future2" 6 "Error" 7 "Not_Available" ;
VAL_ 2432656679 pOperatorButton29 3 "Not Available" 2 "Error" 1 "Button Pressed" 0 "Button Not Pressed" ;
VAL_ 2432656679 pOperatorButton1 0 "Not Pressed" 1 "Pressed" 2 "Error" 3 "Not Available" ;
VAL_ 2432656679 pOperatorButton2 0 "Active" 1 "Inactive" 2 "Error" 3 "Not Available" ;
VAL_ 2432656679 pOperatorButton3 0 "Not Pressed" 1 "Pressed" 2 "Error" 3 "Not Available" ;
VAL_ 2432656679 pOperatorButton4 0 "Not Pressed" 1 "Pressed" 2 "Error" 3 "Not Available" ;
VAL_ 2432656679 pOperatorButton5 0 "Not Pressed" 1 "Pressed" 2 "Error" 3 "Not Available" ;
VAL_ 2432656679 pOperatorButton6 0 "Not Pressed" 1 "Pressed" 2 "Error" 3 "Not Available" ;
VAL_ 2432656679 pOperatorButton7 0 "Not Pressed" 1 "Pressed" 2 "Error" 3 "Not Available" ;
VAL_ 2432656679 pOperatorButton8 0 "Not Pressed" 1 "Pressed" 2 "Error" 3 "Not Available" ;
VAL_ 2432656679 pOperatorButton9 0 "Not Pressed" 1 "Pressed" 2 "Error" 3 "Not Available" ;
VAL_ 2432656679 pOperatorButton10 0 "Not Pressed" 1 "Pressed" 2 "Error" 3 "Not Available" ;
VAL_ 2432656679 pOperatorButton11 0 "Not Pressed" 1 "Pressed" 2 "Error" 3 "Not Available" ;
VAL_ 2432656679 pOperatorButton12 0 "Not Pressed" 1 "Pressed" 2 "Error" 3 "Not Available" ;
VAL_ 2432656679 pOperatorButton13 0 "Not Pressed" 1 "Pressed" 2 "Error" 3 "Not Available" ;
VAL_ 2432656679 pOperatorButton14 0 "Not Pressed" 1 "Pressed" 2 "Error" 3 "Not Available" ;
VAL_ 2432656679 pOperatorButton15 0 "Not Pressed" 1 "Pressed" 2 "Error" 3 "Not Available" ;
VAL_ 2432656679 pOperatorButton16 0 "Not Pressed" 1 "Pressed" 2 "Error" 3 "Not Available" ;
VAL_ 2432656679 pOperatorButton17 0 "Not Pressed" 1 "Pressed" 2 "Error" 3 "Not Available" ;
VAL_ 2432656679 pOperatorButton18 0 "Not Pressed" 1 "Pressed" 2 "Error" 3 "Not Available" ;
VAL_ 2432656679 pOperatorButton19 0 "Not Pressed" 1 "Pressed" 2 "Error" 3 "Not Available" ;
VAL_ 2432656679 pOperatorButton20 0 "Not Pressed" 1 "Pressed" 2 "Error" 3 "Not Available" ;
VAL_ 2432656679 pOperatorButton21 0 "Not Pressed" 1 "Pressed" 2 "Error" 3 "Not Available" ;
VAL_ 2432656679 pOperatorButton22 0 "Not Pressed" 1 "Pressed" 2 "Error" 3 "Not Available" ;
VAL_ 2432656679 pOperatorButton23 0 "Not Pressed" 1 "Pressed" 2 "Error" 3 "Not Available" ;
VAL_ 2432656679 pOperatorButton24 0 "Not Pressed" 1 "Pressed" 2 "Error" 3 "Not Available" ;
VAL_ 2432656679 pOperatorButton25 0 "Not Pressed" 1 "Pressed" 2 "Error" 3 "Not Available" ;
VAL_ 2432656679 pOperatorButton26 0 "Not Pressed" 1 "Pressed" 2 "Error" 3 "Not Available" ;
VAL_ 2432656679 pOperatorButton27 0 "Not Pressed" 1 "Pressed" 2 "Error" 3 "Not Available" ;
VAL_ 2432656679 pOperatorButton28 0 "Not Pressed" 1 "Pressed" 2 "Error" 3 "Not Available" ;
VAL_ 2432656679 pSideStandStatus 3 "Not Available" 2 "Error Indicator" 1 "Side Stand Up" 0 "Side Stand Down" ;
VAL_ 2566845479 TireLocation 0 "Front" 16 "Rear" ;
VAL_ 2566844711 TwoSpeedAxleSwitch 0 "LowSpeedRange" 1 "HighSpeedRange" 2 "Error" 3 "NotAvailable" ;
VAL_ 2566844711 ParkingBrakeSwitch 0 "NotSet" 1 "Set" 2 "Error" 3 "NotAvailable" ;
VAL_ 2566844711 CruiseCtrlActive 0 "SwitchedOff" 1 "SwitchedOn" 2 "Error" 3 "NotAvailable" ;
VAL_ 2566844711 CruiseCtrlEnableSwitch 0 "Disabled" 1 "Enabled" 2 "Error" 3 "NotAvailable" ;
VAL_ 2566844711 BrakeSwitch 0 "PedalReleased" 1 "PedalDepressed" 2 "Error" 3 "NotAvailable" ;
VAL_ 2566844711 ClutchSwitch 0 "PedalReleased" 1 "PedalDepressed" 2 "Error" 3 "NotAvailable" ;
VAL_ 2566844711 CruiseCtrlSetSwitch 0 "NotSet" 1 "Set" 2 "Error" 3 "NotAvailable" ;
VAL_ 2566844711 CruiseCtrlCoastSwitch 0 "NotCoast" 1 "Coast" 2 "Error" 3 "NotAvailable" ;
VAL_ 2566844711 CruiseCtrlResumeSwitch 0 "NotResume" 1 "Resume" 2 "Error" 3 "NotAvailable" ;
VAL_ 2566844711 CruiseCtrlAccelerateSwitch 0 "NotAccelerate" 1 "Accelerate" 2 "Error" 3 "NotAvailable" ;
VAL_ 2566844711 pOdometerDriveBit 0 "State A" 1 "State B" 2 "Error" 3 "Not Available/Initialize" ;
VAL_ 2566844711 CruiseCtrlPauseSw 0 "Off" 1 "On" 2 "Error" 3 "Take No Action" ;
VAL_ 2566844711 pCruiseEnableStatus 0 "Not enabled." 1 "Enabled but not activated." 2 "Reserved" 14 "Error Indicator" 15 "Not Available" ;
VAL_ 2565866791 TransmissionRqstedRange 21024 " R" 20512 " P" 20000 " N" 19488 " L" 18464 " H" ;
VAL_ 2565799463 ArbitraryAddressCapable 0 "No" 1 "Yes" ;
VAL_ 2631794215 EncryptionIndicatorStates 0 "Encryption seed request" 1 "Encryption code present" 2 "Not defined" 3 "Not available" ;
VAL_ 2631794215 AntiTheftDesiredExitModeStates 0 "Locked upon operator request" 1 "Lock when key off" 2 "Not defined" 3 "Not available" ;
VAL_ 2631794215 AntiTheftCommandStates 0 "Add password" 1 "Delete password" 2 "Change password" 3 "Lock or Unlock" 4 "Check status" 5 "Login" ;
VAL_ 2550791719 StaticRollAngleStatus 0 "Sensor Busy" 1 "Sensor OK" 2 "Sensor Defect" 3 "Sensor Reboots" 4 "Angle Data Invalid" 5 "Reserved" 6 "Error" 7 "Not Available" ;
VAL_ 2365473024 LowBeamHeadlightCommand 3 "Don't Care" 2 "Reserved" 1 "Activate" 0 "De-activate" ;
VAL_ 2365473024 HighBeamHeadlightCommand 3 "Don't Care" 2 "Reserved" 1 "Activate" 0 "De-activate" ;
VAL_ 2365473024 LeftTurnSigLightsCommand 0 "De-activate" 1 "Activate" 2 "Reserved" 3 "Don't Care" ;
VAL_ 2365473024 RightTurnSigLightsCommand 0 "De-activate" 1 "Activate" 2 "Reserved" 3 "Don't Care" ;
VAL_ 2631859735 TripGroup1 0 "Take no action" 1 "Reset" 3 "Not applicable" ;
VAL_ 2631859735 TripGroup2 0 "Take no action" 1 "Reset" 3 "Not applicable" ;
VAL_ 2631859735 EngineBuildHoursReset 0 "Do not reset" 1 "Reset" 3 "Take no action" ;
VAL_ 2550201867 EngOverrideCtlMode 0 "Override disabled" 1 "Speed Control" 2 "Torque Control" 3 "Speed/Torque limit control" ;
VAL_ 2550201867 EngReqSpeedControlCond 0 "Transient optimized for drivelin" 1 "Stability optimized for drivelin" ;
VAL_ 2550201867 OverrideCtlModePriority 0 "Highest priority" 1 "High priority" 2 "Medium priority" 3 "Low priority" ;
VAL_ 2550201867 TSC1_TransmissionRate 0 "1000 ms" 1 "750 ms" 2 "500 ms" 3 "250 ms" 4 "100 ms" 5 "50 ms" 6 "20 ms" 7 "10 ms" ;
VAL_ 2566878847 pHeadset2ConnectionStatus 3 "Not Available" 2 "Error" 1 "Headset Connected" 0 "Headset Not Connected" ;
VAL_ 2566878847 pHeadset1ConnectionStatus 3 "Not Available" 2 "Error" 1 "Headset Connected" 0 "Headset Not Connected" ;
VAL_ 2566878847 pDevice2CellSigStrength 7 "Not Available" 6 "Error" 5 "5 Bars of Cell Signal" 4 "4 Bars of Cell Signal" 3 "3 Bars of Cell Signal" 2 "2 Bars of Cell Signal" 1 "1 Bars of Cell Signal" 0 "0 Bars of Cell Signal" ;
VAL_ 2566878847 pDevice2BTConnectStatus 3 "Not Available" 2 "Error" 1 "Device Connected" 0 "Device Not Connected" ;
VAL_ 2566878847 pDevice2BattStrength 7 "Not Available" 6 "Error" 5 "5 Bars of Battery Strength" 4 "4 Bars of Battery Strength" 3 "3 Bars of Battery Strength" 2 "2 Bars of Battery Strength" 1 "1 Bars of Battery Strength" 0 "0 Bars of Battery Strength" ;
VAL_ 2566878847 pDevice1CellSigStrength 7 "Not Available" 6 "Error" 5 "5 Bars of Cell Signal" 4 "4 Bars of Cell Signal" 3 "3 Bars of Cell Signal" 2 "2 Bars of Cell Signal" 1 "1 Bars of Cell Signal" 0 "0 Bars of Cell Signal" ;
VAL_ 2566878847 pDevice1BTConnectStatus 3 "Not Available" 2 "Error" 1 "Device Connected" 0 "Device Not Connected" ;
VAL_ 2566878847 pDevice1BattStrength 7 "Not Available" 6 "Error" 5 "5 Bars of Battery Strength" 4 "4 Bars of Battery Strength" 3 "3 Bars of Battery Strength" 2 "2 Bars of Battery Strength" 1 "1 Bars of Battery Strength" 0 "0 Bars of Battery Strength" ;
VAL_ 2566877505 pVolumeUnitsSelected 7 "Not Available" 6 "Error" 5 "Reserved" 4 "Reserved" 3 "Reserved" 2 "Imperial Gallons" 1 "Liters" 0 "Gallons" ;
VAL_ 2566877505 pTimeUnitsSelected 3 "Not Available" 2 "Error" 1 "24 Hour" 0 "12 Hour" ;
VAL_ 2566877505 pTemperatureUnitsSelected 3 "Not Avaialable" 2 "Error" 1 "Celsius" 0 "Farenheit" ;
VAL_ 2566877505 pPressureUnitsSelected 3 "Not Available" 2 "Error" 1 "Kilopascal (kPa)" 0 "Pounds Per Square Inch (PSI)" ;
VAL_ 2566877505 pDistanceUnitsSelected 3 "Not Available" 2 "Error" 1 "Kilometers" 0 "Miles" ;
VAL_ 2566877505 pTPMSLearningStatus 0 "Not Started" 1 "Request to start" 2 "Learning Left Front" 3 "Learning Right Front" 4 "Learning Left Rear" 5 "Learning Right Rear" 6 "Learning successfully completed" 13 "Request to end learning" 14 "Error - Failed Learning" 15 "Not Available" ;
VAL_ 2566877505 pDisplayStatus 0 "Info cant overide to full screen" 1 "User requested full screen" 2 "Info can overide to full screen" 14 "Info data is not shown" 15 "Not Available" ;
VAL_ 2566877311 pHighlightRow 15 "Not Avialable" 14 "Error" 13 "Row 13 Highlighted" 12 "Row 12 Highlighted" 11 "Row 11 Highlighted" 10 "Row 10 Highlighted" 9 "Row 9 Highlighted" 8 "Row 8 Highlighted" 7 "Row 7 Highlighted" 6 "Row 6 Highlighted" 5 "Row 5 Highlighted" 4 "Row 4 Highlighted" 3 "Row 3 Highlighted" 2 "Row 2 Highlighted" 1 "Row 1 Highlighted" 0 "No Row Highlighted" ;
VAL_ 2566877311 pScreenAreaMode 7 "Not_Available" 6 "Error" 5 "Reserved" 4 "Reserved" 3 "Reserved" 2 "Reserved" 1 "Sending_Data_List" 0 "Normal_Screen_Dsiplay" ;
VAL_ 2566877311 pRadioInputDevice 0 "Blank" 1 "iPod" 2 "XM" 3 "AUX" 4 "USB" 5 "NAV" 6 "MP3" 7 "BLUETOOTH" 8 "PANDORA" 9 "SIRIUS" 10 "FM" 11 "FM1" 12 "FM2" 13 "FM3" 14 "FM4" 15 "WX" 16 "AM" 17 "LW" 18 "MW" 19 "SW" 20 "iHEART" 21 "ICOM" 22 "GMRS" 23 "CB" 24 "GMRS TX" 25 "GMRS RX" 31 "P1" 32 "P2" 33 "P3" 34 "P4" 35 "P5" 36 "P6" 37 "P7" 38 "P8" 39 "P9" 40 "P10" 41 "P11" 42 "P12" 43 "P13" 44 "P14" 45 "P15" 46 "P16" 47 "P17" 48 "P18" 49 "P19" 50 "P20" 61 "TURN LEFT" 62 "TURN RIGHT" 63 "DESTINATION" 70 "BT VOL" 71 "BT VOL+" 72 "BT VOL-" 80 "(THUMBS UP)" 81 "(THUMBS DOWN)" 91 "INCOMING CALL" 92 "INCOMING TEXT" 100 "RADIO OFF" 110 "BASS" 111 "TREBLE" 112 "MID" 113 "BALANCE" 114 "AVC" 115 "VOLUME" 116 "MUTE" 117 "FADE" 26 "Reserved" 255 "Not Available" ;
VAL_ 2566877311 pRadioScaling 0 "1/bit" 1 "0.1/bit - 1 decimal point" 2 "0.01/bit - 2 decimal points" 6 "Do not show Input value" 7 "Not Availalbe" ;
VAL_ 2566877311 pTextLineConfiguration 0 "No ASCII text shown" 1 "Standard 1 line of ASCII text" 2 "ASCII text control small area" 3 "ASCII text control large area" 7 "Not Available" ;
VAL_ 2566877311 pStereoStatus 0 "No Stereo" 1 "Stereo" 2 "Error" 3 "Not Available" ;
VAL_ 2566877311 pFirstRowConfiguration 6 "Error" 5 "Reserved" 4 "Reserved" 3 "Reserved" 0 "See Comment 0." 1 "See Comment 1." 2 "See Comment 2." 7 "Not Available" ;
VAL_ 2566877311 pScreenAreaConfiguration 0 "Normal Screen Size" 1 "Expanded Screen Size" 2 "Error" 3 "Not Available" ;
VAL_ 2432656449 pInfotainmentJoystick2 5 "Center" 4 "Right" 3 "Left" 2 "Down" 1 "Up" 0 "Neutral" ;
VAL_ 2432656449 pInfotainmentJoystick1 5 "Center" 4 "Right" 3 "Left" 2 "Down" 1 "Up" 0 "Neutral" ;
VAL_ 2432656449 pInfotainmentRemoteButton01 0 "Not Pressed" 1 "Pressed" 2 "Error" 3 "Not Available" ;
VAL_ 2432656449 pInfotainmentRemoteButton02 0 "Not Pressed" 1 "Pressed" 2 "Error" 3 "Not Available" ;
VAL_ 2432656449 pInfotainmentRemoteButton03 0 "Not Pressed" 1 "Pressed" 2 "Error" 3 "Not Available" ;
VAL_ 2432656449 pInfotainmentRemoteButton04 0 "Not Pressed" 1 "Pressed" 2 "Error" 3 "Not Available" ;
VAL_ 2432656449 pInfotainmentRemoteButton05 0 "Not Pressed" 1 "Pressed" 2 "Error" 3 "Not Available" ;
VAL_ 2432656449 pInfotainmentRemoteButton06 0 "Not Pressed" 1 "Pressed" 2 "Error" 3 "Not Available" ;
VAL_ 2432656449 pInfotainmentRemoteButton07 0 "Not Pressed" 1 "Pressed" 2 "Error" 3 "Not Available" ;
VAL_ 2432656449 pInfotainmentRemoteButton08 0 "Not Pressed" 1 "Pressed" 2 "Error" 3 "Not Available" ;
VAL_ 2432656449 pInfotainmentRemoteButton09 0 "Not Pressed" 1 "Pressed" 2 "Error" 3 "Not Available" ;
VAL_ 2432656449 pInfotainmentRemoteButton10 0 "Not Pressed" 1 "Pressed" 2 "Error" 3 "Not Available" ;
VAL_ 2432656449 pInfotainmentRemoteButton11 0 "Not Pressed" 1 "Pressed" 2 "Error" 3 "Not Available" ;
VAL_ 2432656449 pInfotainmentRemoteButton12 0 "Not Pressed" 1 "Pressed" 2 "Error" 3 "Not Available" ;
VAL_ 2566844683 TwoSpeedAxleSwitch 0 "LowSpeedRange" 1 "HighSpeedRange" 2 "Error" 3 "NotAvailable" ;
VAL_ 2566844683 ParkingBrakeSwitch 0 "NotSet" 1 "Set" 2 "Error" 3 "NotAvailable" ;
VAL_ 2566844683 CruiseCtrlActive 0 "SwitchedOff" 1 "SwitchedOn" 2 "Error" 3 "NotAvailable" ;
VAL_ 2566844683 CruiseCtrlEnableSwitch 0 "Disabled" 1 "Enabled" 2 "Error" 3 "NotAvailable" ;
VAL_ 2566844683 BrakeSwitch 0 "PedalReleased" 1 "PedalDepressed" 2 "Error" 3 "NotAvailable" ;
VAL_ 2566844683 ClutchSwitch 0 "PedalReleased" 1 "PedalDepressed" 2 "Error" 3 "NotAvailable" ;
VAL_ 2566844683 CruiseCtrlSetSwitch 0 "NotSet" 1 "Set" 2 "Error" 3 "NotAvailable" ;
VAL_ 2566844683 CruiseCtrlCoastSwitch 0 "NotCoast" 1 "Coast" 2 "Error" 3 "NotAvailable" ;
VAL_ 2566844683 CruiseCtrlResumeSwitch 0 "NotResume" 1 "Resume" 2 "Error" 3 "NotAvailable" ;
VAL_ 2566844683 CruiseCtrlAccelerateSwitch 0 "NotAccelerate" 1 "Accelerate" 2 "Error" 3 "NotAvailable" ;
VAL_ 2566844683 pOdometerDriveBit 0 "State A" 1 "State B" 2 "Error" 3 "Not Available/Initialize" ;
VAL_ 2566844683 CruiseCtrlPauseSw 0 "Off" 1 "On" 2 "Error" 3 "Take No Action" ;
VAL_ 2566844683 pCruiseEnableStatus 0 "Not enabled." 1 "Enabled but not activated." 2 "Reserved" 14 "Error Indicator" 15 "Not Available" ;
VAL_ 2566844839 TwoSpeedAxleSwitch 0 "LowSpeedRange" 1 "HighSpeedRange" 2 "Error" 3 "NotAvailable" ;
VAL_ 2566844839 ParkingBrakeSwitch 0 "NotSet" 1 "Set" 2 "Error" 3 "NotAvailable" ;
VAL_ 2566844839 CruiseCtrlActive 0 "SwitchedOff" 1 "SwitchedOn" 2 "Error" 3 "NotAvailable" ;
VAL_ 2566844839 CruiseCtrlEnableSwitch 0 "Disabled" 1 "Enabled" 2 "Error" 3 "NotAvailable" ;
VAL_ 2566844839 BrakeSwitch 0 "PedalReleased" 1 "PedalDepressed" 2 "Error" 3 "NotAvailable" ;
VAL_ 2566844839 ClutchSwitch 0 "PedalReleased" 1 "PedalDepressed" 2 "Error" 3 "NotAvailable" ;
VAL_ 2566844839 CruiseCtrlSetSwitch 0 "NotSet" 1 "Set" 2 "Error" 3 "NotAvailable" ;
VAL_ 2566844839 CruiseCtrlCoastSwitch 0 "NotCoast" 1 "Coast" 2 "Error" 3 "NotAvailable" ;
VAL_ 2566844839 CruiseCtrlResumeSwitch 0 "NotResume" 1 "Resume" 2 "Error" 3 "NotAvailable" ;
VAL_ 2566844839 CruiseCtrlAccelerateSwitch 0 "NotAccelerate" 1 "Accelerate" 2 "Error" 3 "NotAvailable" ;
VAL_ 2566844839 pOdometerDriveBit 0 "State A" 1 "State B" 2 "Error" 3 "Not Available/Initialize" ;
VAL_ 2566844839 CruiseCtrlPauseSw 0 "Off" 1 "On" 2 "Error" 3 "Take No Action" ;
VAL_ 2566844839 pCruiseEnableStatus 0 "Not enabled." 1 "Enabled but not activated." 2 "Reserved" 14 "Error Indicator" 15 "Not Available" ;
VAL_ 2566834855 DM_FlashRedStopLamp 3 "Unavailable / Do Not Flash" 2 "Reserved" 1 "Fast Flash (2 Hz, 50% DC)" 0 "Slow Flash (1 Hz, 50% DC)" ;
VAL_ 2566834855 DM_FlashProtectLamp 3 "Unavailable / Do Not Flash" 2 "Reserved" 1 "Fast Flash (2 Hz, 50% DC)" 0 "Slow Flash (1 Hz, 50% DC)" ;
VAL_ 2566834855 DM_FlashMalfuncIndicatorLamp 3 "Unavailable / Do Not Flash" 2 "Reserved" 1 "Fast Flash (2 Hz, 50% DC)" 0 "Slow Flash (1 Hz, 50% DC)" ;
VAL_ 2566834855 DM_FlashAmberWarningLamp 3 "Unavailable / Do Not Flash" 2 "Reserved" 1 "Fast Flash (2 Hz, 50% DC)" 0 "Slow Flash (1 Hz, 50% DC)" ;
VAL_ 2566834855 DM_ProtectLampStatus 0 "Lamp off" 1 "Lamp on" 2 "Reserved" 3 "Not available" ;
VAL_ 2566834855 DM_RedStopLampState 0 "Lamp off" 1 "Lamp on" 2 "Reserved" 3 "Not available" ;
VAL_ 2566834855 DM_AmberWrningLmpStatus 0 "Lamp off" 1 "Lamp on" 2 "Reserved" 3 "Not available" ;
VAL_ 2566834855 DM_MalfuncnIndicatorLampStatus 0 "Lamp off" 1 "Lamp on" 2 "Reserved" 3 "Not available" ;
VAL_ 2566834815 DM_FlashRedStopLamp 3 "Unavailable / Do Not Flash" 2 "Reserved" 1 "Fast Flash (2 Hz, 50% DC)" 0 "Slow Flash (1 Hz, 50% DC)" ;
VAL_ 2566834815 DM_FlashProtectLamp 3 "Unavailable / Do Not Flash" 2 "Reserved" 1 "Fast Flash (2 Hz, 50% DC)" 0 "Slow Flash (1 Hz, 50% DC)" ;
VAL_ 2566834815 DM_FlashMalfuncIndicatorLamp 3 "Unavailable / Do Not Flash" 2 "Reserved" 1 "Fast Flash (2 Hz, 50% DC)" 0 "Slow Flash (1 Hz, 50% DC)" ;
VAL_ 2566834815 DM_FlashAmberWarningLamp 3 "Unavailable / Do Not Flash" 2 "Reserved" 1 "Fast Flash (2 Hz, 50% DC)" 0 "Slow Flash (1 Hz, 50% DC)" ;
VAL_ 2566834815 DM_ProtectLampStatus 0 "Lamp off" 1 "Lamp on" 2 "Reserved" 3 "Not available" ;
VAL_ 2566834815 DM_RedStopLampState 0 "Lamp off" 1 "Lamp on" 2 "Reserved" 3 "Not available" ;
VAL_ 2566834815 DM_AmberWrningLmpStatus 0 "Lamp off" 1 "Lamp on" 2 "Reserved" 3 "Not available" ;
VAL_ 2566834815 DM_MalfuncnIndicatorLampStatus 0 "Lamp off" 1 "Lamp on" 2 "Reserved" 3 "Not available" ;
VAL_ 2566834814 DM_FlashRedStopLamp 3 "Unavailable / Do Not Flash" 2 "Reserved" 1 "Fast Flash (2 Hz, 50% DC)" 0 "Slow Flash (1 Hz, 50% DC)" ;
VAL_ 2566834814 DM_FlashProtectLamp 3 "Unavailable / Do Not Flash" 2 "Reserved" 1 "Fast Flash (2 Hz, 50% DC)" 0 "Slow Flash (1 Hz, 50% DC)" ;
VAL_ 2566834814 DM_FlashMalfuncIndicatorLamp 3 "Unavailable / Do Not Flash" 2 "Reserved" 1 "Fast Flash (2 Hz, 50% DC)" 0 "Slow Flash (1 Hz, 50% DC)" ;
VAL_ 2566834814 DM_FlashAmberWarningLamp 3 "Unavailable / Do Not Flash" 2 "Reserved" 1 "Fast Flash (2 Hz, 50% DC)" 0 "Slow Flash (1 Hz, 50% DC)" ;
VAL_ 2566834814 DM_ProtectLampStatus 0 "Lamp off" 1 "Lamp on" 2 "Reserved" 3 "Not available" ;
VAL_ 2566834814 DM_RedStopLampState 0 "Lamp off" 1 "Lamp on" 2 "Reserved" 3 "Not available" ;
VAL_ 2566834814 DM_AmberWrningLmpStatus 0 "Lamp off" 1 "Lamp on" 2 "Reserved" 3 "Not available" ;
VAL_ 2566834814 DM_MalfuncnIndicatorLampStatus 0 "Lamp off" 1 "Lamp on" 2 "Reserved" 3 "Not available" ;
VAL_ 2566834812 DM_FlashRedStopLamp 3 "Unavailable / Do Not Flash" 2 "Reserved" 1 "Fast Flash (2 Hz, 50% DC)" 0 "Slow Flash (1 Hz, 50% DC)" ;
VAL_ 2566834812 DM_FlashProtectLamp 3 "Unavailable / Do Not Flash" 2 "Reserved" 1 "Fast Flash (2 Hz, 50% DC)" 0 "Slow Flash (1 Hz, 50% DC)" ;
VAL_ 2566834812 DM_FlashMalfuncIndicatorLamp 3 "Unavailable / Do Not Flash" 2 "Reserved" 1 "Fast Flash (2 Hz, 50% DC)" 0 "Slow Flash (1 Hz, 50% DC)" ;
VAL_ 2566834812 DM_FlashAmberWarningLamp 3 "Unavailable / Do Not Flash" 2 "Reserved" 1 "Fast Flash (2 Hz, 50% DC)" 0 "Slow Flash (1 Hz, 50% DC)" ;
VAL_ 2566834812 DM_ProtectLampStatus 0 "Lamp off" 1 "Lamp on" 2 "Reserved" 3 "Not available" ;
VAL_ 2566834812 DM_RedStopLampState 0 "Lamp off" 1 "Lamp on" 2 "Reserved" 3 "Not available" ;
VAL_ 2566834812 DM_AmberWrningLmpStatus 0 "Lamp off" 1 "Lamp on" 2 "Reserved" 3 "Not available" ;
VAL_ 2566834812 DM_MalfuncnIndicatorLampStatus 0 "Lamp off" 1 "Lamp on" 2 "Reserved" 3 "Not available" ;
VAL_ 2566834808 DM_FlashRedStopLamp 3 "Unavailable / Do Not Flash" 2 "Reserved" 1 "Fast Flash (2 Hz, 50% DC)" 0 "Slow Flash (1 Hz, 50% DC)" ;
VAL_ 2566834808 DM_FlashProtectLamp 3 "Unavailable / Do Not Flash" 2 "Reserved" 1 "Fast Flash (2 Hz, 50% DC)" 0 "Slow Flash (1 Hz, 50% DC)" ;
VAL_ 2566834808 DM_FlashMalfuncIndicatorLamp 3 "Unavailable / Do Not Flash" 2 "Reserved" 1 "Fast Flash (2 Hz, 50% DC)" 0 "Slow Flash (1 Hz, 50% DC)" ;
VAL_ 2566834808 DM_FlashAmberWarningLamp 3 "Unavailable / Do Not Flash" 2 "Reserved" 1 "Fast Flash (2 Hz, 50% DC)" 0 "Slow Flash (1 Hz, 50% DC)" ;
VAL_ 2566834808 DM_ProtectLampStatus 0 "Lamp off" 1 "Lamp on" 2 "Reserved" 3 "Not available" ;
VAL_ 2566834808 DM_RedStopLampState 0 "Lamp off" 1 "Lamp on" 2 "Reserved" 3 "Not available" ;
VAL_ 2566834808 DM_AmberWrningLmpStatus 0 "Lamp off" 1 "Lamp on" 2 "Reserved" 3 "Not available" ;
VAL_ 2566834808 DM_MalfuncnIndicatorLampStatus 0 "Lamp off" 1 "Lamp on" 2 "Reserved" 3 "Not available" ;
VAL_ 2566834937 DM_FlashRedStopLamp 3 "Unavailable / Do Not Flash" 2 "Reserved" 1 "Fast Flash (2 Hz, 50% DC)" 0 "Slow Flash (1 Hz, 50% DC)" ;
VAL_ 2566834937 DM_FlashProtectLamp 3 "Unavailable / Do Not Flash" 2 "Reserved" 1 "Fast Flash (2 Hz, 50% DC)" 0 "Slow Flash (1 Hz, 50% DC)" ;
VAL_ 2566834937 DM_FlashMalfuncIndicatorLamp 3 "Unavailable / Do Not Flash" 2 "Reserved" 1 "Fast Flash (2 Hz, 50% DC)" 0 "Slow Flash (1 Hz, 50% DC)" ;
VAL_ 2566834937 DM_FlashAmberWarningLamp 3 "Unavailable / Do Not Flash" 2 "Reserved" 1 "Fast Flash (2 Hz, 50% DC)" 0 "Slow Flash (1 Hz, 50% DC)" ;
VAL_ 2566834937 DM_ProtectLampStatus 0 "Lamp off" 1 "Lamp on" 2 "Reserved" 3 "Not available" ;
VAL_ 2566834937 DM_RedStopLampState 0 "Lamp off" 1 "Lamp on" 2 "Reserved" 3 "Not available" ;
VAL_ 2566834937 DM_AmberWrningLmpStatus 0 "Lamp off" 1 "Lamp on" 2 "Reserved" 3 "Not available" ;
VAL_ 2566834937 DM_MalfuncnIndicatorLampStatus 0 "Lamp off" 1 "Lamp on" 2 "Reserved" 3 "Not available" ;
VAL_ 2566834753 DM_FlashRedStopLamp 3 "Unavailable / Do Not Flash" 2 "Reserved" 1 "Fast Flash (2 Hz, 50% DC)" 0 "Slow Flash (1 Hz, 50% DC)" ;
VAL_ 2566834753 DM_FlashProtectLamp 3 "Unavailable / Do Not Flash" 2 "Reserved" 1 "Fast Flash (2 Hz, 50% DC)" 0 "Slow Flash (1 Hz, 50% DC)" ;
VAL_ 2566834753 DM_FlashMalfuncIndicatorLamp 3 "Unavailable / Do Not Flash" 2 "Reserved" 1 "Fast Flash (2 Hz, 50% DC)" 0 "Slow Flash (1 Hz, 50% DC)" ;
VAL_ 2566834753 DM_FlashAmberWarningLamp 3 "Unavailable / Do Not Flash" 2 "Reserved" 1 "Fast Flash (2 Hz, 50% DC)" 0 "Slow Flash (1 Hz, 50% DC)" ;
VAL_ 2566834753 DM_ProtectLampStatus 0 "Lamp off" 1 "Lamp on" 2 "Reserved" 3 "Not available" ;
VAL_ 2566834753 DM_RedStopLampState 0 "Lamp off" 1 "Lamp on" 2 "Reserved" 3 "Not available" ;
VAL_ 2566834753 DM_AmberWrningLmpStatus 0 "Lamp off" 1 "Lamp on" 2 "Reserved" 3 "Not available" ;
VAL_ 2566834753 DM_MalfuncnIndicatorLampStatus 0 "Lamp off" 1 "Lamp on" 2 "Reserved" 3 "Not available" ;
VAL_ 2566834717 DM_FlashRedStopLamp 3 "Unavailable / Do Not Flash" 2 "Reserved" 1 "Fast Flash (2 Hz, 50% DC)" 0 "Slow Flash (1 Hz, 50% DC)" ;
VAL_ 2566834717 DM_FlashProtectLamp 3 "Unavailable / Do Not Flash" 2 "Reserved" 1 "Fast Flash (2 Hz, 50% DC)" 0 "Slow Flash (1 Hz, 50% DC)" ;
VAL_ 2566834717 DM_FlashMalfuncIndicatorLamp 3 "Unavailable / Do Not Flash" 2 "Reserved" 1 "Fast Flash (2 Hz, 50% DC)" 0 "Slow Flash (1 Hz, 50% DC)" ;
VAL_ 2566834717 DM_FlashAmberWarningLamp 3 "Unavailable / Do Not Flash" 2 "Reserved" 1 "Fast Flash (2 Hz, 50% DC)" 0 "Slow Flash (1 Hz, 50% DC)" ;
VAL_ 2566834717 DM_ProtectLampStatus 0 "Lamp off" 1 "Lamp on" 2 "Reserved" 3 "Not available" ;
VAL_ 2566834717 DM_RedStopLampState 0 "Lamp off" 1 "Lamp on" 2 "Reserved" 3 "Not available" ;
VAL_ 2566834717 DM_AmberWrningLmpStatus 0 "Lamp off" 1 "Lamp on" 2 "Reserved" 3 "Not available" ;
VAL_ 2566834717 DM_MalfuncnIndicatorLampStatus 0 "Lamp off" 1 "Lamp on" 2 "Reserved" 3 "Not available" ;
VAL_ 2566834711 DM_FlashRedStopLamp 3 "Unavailable / Do Not Flash" 2 "Reserved" 1 "Fast Flash (2 Hz, 50% DC)" 0 "Slow Flash (1 Hz, 50% DC)" ;
VAL_ 2566834711 DM_FlashProtectLamp 3 "Unavailable / Do Not Flash" 2 "Reserved" 1 "Fast Flash (2 Hz, 50% DC)" 0 "Slow Flash (1 Hz, 50% DC)" ;
VAL_ 2566834711 DM_FlashMalfuncIndicatorLamp 3 "Unavailable / Do Not Flash" 2 "Reserved" 1 "Fast Flash (2 Hz, 50% DC)" 0 "Slow Flash (1 Hz, 50% DC)" ;
VAL_ 2566834711 DM_FlashAmberWarningLamp 3 "Unavailable / Do Not Flash" 2 "Reserved" 1 "Fast Flash (2 Hz, 50% DC)" 0 "Slow Flash (1 Hz, 50% DC)" ;
VAL_ 2566834711 DM_ProtectLampStatus 0 "Lamp off" 1 "Lamp on" 2 "Reserved" 3 "Not available" ;
VAL_ 2566834711 DM_RedStopLampState 0 "Lamp off" 1 "Lamp on" 2 "Reserved" 3 "Not available" ;
VAL_ 2566834711 DM_AmberWrningLmpStatus 0 "Lamp off" 1 "Lamp on" 2 "Reserved" 3 "Not available" ;
VAL_ 2566834711 DM_MalfuncnIndicatorLampStatus 0 "Lamp off" 1 "Lamp on" 2 "Reserved" 3 "Not available" ;
VAL_ 2566834707 DM_FlashRedStopLamp 3 "Unavailable / Do Not Flash" 2 "Reserved" 1 "Fast Flash (2 Hz, 50% DC)" 0 "Slow Flash (1 Hz, 50% DC)" ;
VAL_ 2566834707 DM_FlashProtectLamp 3 "Unavailable / Do Not Flash" 2 "Reserved" 1 "Fast Flash (2 Hz, 50% DC)" 0 "Slow Flash (1 Hz, 50% DC)" ;
VAL_ 2566834707 DM_FlashMalfuncIndicatorLamp 3 "Unavailable / Do Not Flash" 2 "Reserved" 1 "Fast Flash (2 Hz, 50% DC)" 0 "Slow Flash (1 Hz, 50% DC)" ;
VAL_ 2566834707 DM_FlashAmberWarningLamp 3 "Unavailable / Do Not Flash" 2 "Reserved" 1 "Fast Flash (2 Hz, 50% DC)" 0 "Slow Flash (1 Hz, 50% DC)" ;
VAL_ 2566834707 DM_ProtectLampStatus 0 "Lamp off" 1 "Lamp on" 2 "Reserved" 3 "Not available" ;
VAL_ 2566834707 DM_RedStopLampState 0 "Lamp off" 1 "Lamp on" 2 "Reserved" 3 "Not available" ;
VAL_ 2566834707 DM_AmberWrningLmpStatus 0 "Lamp off" 1 "Lamp on" 2 "Reserved" 3 "Not available" ;
VAL_ 2566834707 DM_MalfuncnIndicatorLampStatus 0 "Lamp off" 1 "Lamp on" 2 "Reserved" 3 "Not available" ;
VAL_ 2566834699 DM_FlashRedStopLamp 3 "Unavailable / Do Not Flash" 2 "Reserved" 1 "Fast Flash (2 Hz, 50% DC)" 0 "Slow Flash (1 Hz, 50% DC)" ;
VAL_ 2566834699 DM_FlashProtectLamp 3 "Unavailable / Do Not Flash" 2 "Reserved" 1 "Fast Flash (2 Hz, 50% DC)" 0 "Slow Flash (1 Hz, 50% DC)" ;
VAL_ 2566834699 DM_FlashMalfuncIndicatorLamp 3 "Unavailable / Do Not Flash" 2 "Reserved" 1 "Fast Flash (2 Hz, 50% DC)" 0 "Slow Flash (1 Hz, 50% DC)" ;
VAL_ 2566834699 DM_FlashAmberWarningLamp 3 "Unavailable / Do Not Flash" 2 "Reserved" 1 "Fast Flash (2 Hz, 50% DC)" 0 "Slow Flash (1 Hz, 50% DC)" ;
VAL_ 2566834699 DM_ProtectLampStatus 0 "Lamp off" 1 "Lamp on" 2 "Reserved" 3 "Not available" ;
VAL_ 2566834699 DM_RedStopLampState 0 "Lamp off" 1 "Lamp on" 2 "Reserved" 3 "Not available" ;
VAL_ 2566834699 DM_AmberWrningLmpStatus 0 "Lamp off" 1 "Lamp on" 2 "Reserved" 3 "Not available" ;
VAL_ 2566834699 DM_MalfuncnIndicatorLampStatus 0 "Lamp off" 1 "Lamp on" 2 "Reserved" 3 "Not available" ;
VAL_ 2566803211 VDCInfoSignal 0 "Off" 1 "On" 2 "Reserved" 3 "Don't Care/Take No Action" ;
VAL_ 2566803211 VDCFullyOperational 0 "Not Fully Operational" 1 "Fully Operation" 2 "Reserved" 3 "Don't Care" ;
VAL_ 2566803211 VDCBrakeLightRequest 0 "Turn brake light off" 1 "Turn brake light on" 2 "Reserved" 3 "Don't care/Take no action" ;
VAL_ 2566803211 ROPEngineControlActive 0 "passive, but installed" 1 "active" 2 "Reserved" 3 "Don't Care/Take no Action" ;
VAL_ 2566803211 ROPBrakeControlActive 0 "passive, but installed" 1 "active" 2 "Reserved" 3 "Don't Care/Take no Action" ;
VAL_ 2566803211 YCEngineControlactive 0 "passive, but installed" 1 "active" 2 "reserved" 3 "Don't care/Take no action" ;
VAL_ 2566803211 YCBrakeControlActive 0 "passive, but installed" 1 "active" 2 "reserved" 3 "Don't care/Take no action" ;
VAL_ 2565867787 SteeringWheelAngleSensorType 0 "Relative Measuring Principle" 1 "Absolute measuring principle" 2 "Reserved" 3 "Not Available" ;
VAL_ 2565865739 ABSActive 0 "Passive" 1 "Active" 2 "Reserved" 3 "NoAction" ;
VAL_ 2565865739 ASREngineCtrlActive 0 "Passive" 1 "Active" 2 "Reserved" 3 "NoAction" ;
VAL_ 2565865739 ASRBrakeCtrlActive 0 "Passive" 1 "Active" 2 "Reserved" 3 "NoAction" ;
VAL_ 2565865739 ABSOffroadSwitch 0 "Passive" 1 "Active" 2 "Error" 3 "NotAvailable" ;
VAL_ 2565865739 ASROffroadSwitch 0 "Passive" 1 "Active" 2 "Error" 3 "NotAvailable" ;
VAL_ 2565865739 ASRHillHolderSwitch 0 "Passive" 1 "Active" 2 "Error" 3 "NotAvailable" ;
VAL_ 2565865739 EBSBrakeSwitch 0 "Brake pedal is not being pressed" 1 "Brake pedal is being pressed" 2 "Reserved" 3 "Don't care" ;
VAL_ 2565865739 DL17_TractionCtrlOverrideSwitch 0 "Active" 1 "Inactive" 2 "Reserved" 3 "Don't care" ;
VAL_ 2565865739 AcceleratorInterlockSwitch 0 "off" 1 "on" 2 "Reserved" 3 "Don't care" ;
VAL_ 2565865739 EngineDerateSwitch 0 "off" 1 "on" 2 "Reserved" 3 "Don't care" ;
VAL_ 2565865739 AuxEngineShutdownSwitch 0 "off" 1 "on" 2 "Reserved" 3 "Don't care" ;
VAL_ 2565865739 RemoteAcceleratorSwitch 0 "off" 1 "on" 2 "Reserved" 3 "Don't care" ;
VAL_ 2565865739 ABSFullyOperational 0 "not fully operational" 1 "fully operational" 2 "Reserved" 3 "Don't care" ;
VAL_ 2565865739 EBSRedWarningState 0 "off" 1 "on" 2 "Reserved" 3 "Don't care" ;
VAL_ 2565865739 ABSEBSAmberWarningState 0 "off" 1 "on" 2 "Reserved" 3 "Don't care" ;
VAL_ 2565865739 ATC_ASR_InfoSig 0 "Off" 1 "On" 2 "Reserved" 3 "Take no action" ;
VAL_ 2565799591 ArbitraryAddressCapable 0 "No" 1 "Yes" ;
VAL_ 2565799551 ArbitraryAddressCapable 0 "No" 1 "Yes" ;
VAL_ 2565799550 ArbitraryAddressCapable 0 "No" 1 "Yes" ;
